VERSION ""

NS_ :

BS_:

BU_: PowertrainControlModule AtmosphericSensor SafetyRestraintSystem2 Aftertreatment_2_GasOutlet Aftertreatment_2_GasIntake DieselParticulateFilterControl Turbocharger SafetyRestraintSystem1 CabDisplay2 Aftertreatment_1_GasOutlet Aftertreatment_1_GasIntake OnBoardDataLogger OffBoardDiagnosticTool2 OffBoardDiagnosticTool1 FileServer ParkingBrakeController SeatController2 FanDriveController SteeringColumnUnit CommunicationUnitRadio CommunicationUnitSatellite CommunicationUnitCellular PropulsionBatteryCharger ChassisController2 ChassisController1 EngineValveControl AuxiliaryHeater2 AuxiliaryHeater1 ClutchUnit RampControl InformationSystem1 SuspensionSystemController2 OilSensor VehicleDynamicStability ExhaustEmissionController TransmissionDisplay2 TransmissionDisplay1 ClimateControl2 WaterPumpController RearAxleSteeringController LightingOperatorControl SeatController1 IgnitionController2 IgnitionController1 TirePressureController CabController2 CabController1 PneumaticSystemController SuspensionSystemController1 HydraulicPumpController EnduranceBrakingSystem RetarderExhaustEngine2 OnBoardDiagnosticUnit HeadwayController RetarderExhaustEngine1 CabDisplay1 ManagementComputer VirtualTerminal OffVehicleGateway PowerTakeOffFront HitchControl AuxiliaryValveControl BodyController TractorTrailerBridge1 StarterSystem ElectricalSystem VehicleSecurity VehicleNavigation AerodynamicControl ElectricalChargingSystem ClimateControl1 TripRecorder InstrumentCluster SuspensionDriveAxle2 SuspensionDriveAxle1 SuspensionSteerAxle SteeringController FuelSystem CruiseControl RetarderDriveline RetarderEngine BrakesDriveAxle2 BrakesDriveAxle1 BrakesSystemController BrakesSteerAxle AxleDrive2 AxleDrive1 AxleSteering PowerTakeOff ShiftConsoleSecondary ShiftConsolePrimary Transmission2 Transmission1 Engine2 Engine1

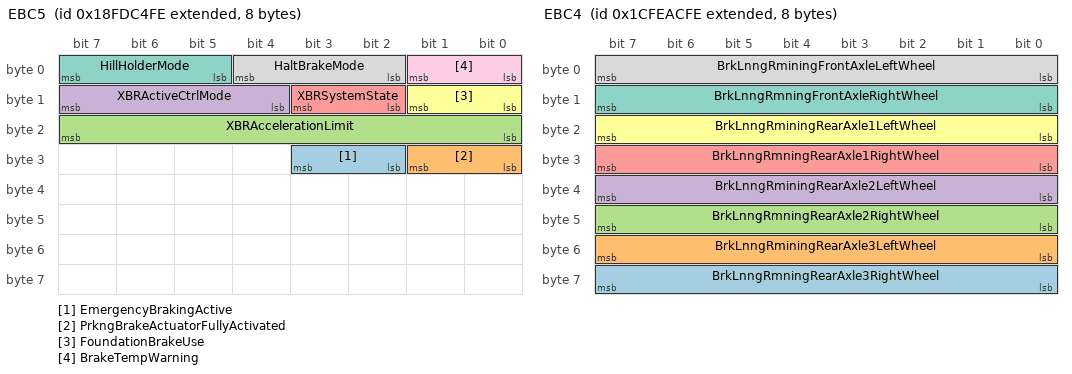
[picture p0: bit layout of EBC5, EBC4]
BO_ 2566767870 EBC5: 8 Vector__XXX
 SG_ EmergencyBrakingActive : 26|2@1+ (1,0) [0|3] "" Vector__XXX
 SG_ PrkngBrakeActuatorFullyActivated : 24|2@1+ (1,0) [0|3] "" Vector__XXX
 SG_ XBRAccelerationLimit : 16|8@1+ (0.1,-12.5) [-10|10] "m/s²" Vector__XXX
 SG_ XBRActiveCtrlMode : 12|4@1+ (1,0) [0|15] "" Vector__XXX
 SG_ XBRSystemState : 10|2@1+ (1,0) [0|3] "" Vector__XXX
 SG_ FoundationBrakeUse : 8|2@1+ (1,0) [0|3] "" Vector__XXX
 SG_ HillHolderMode : 5|3@1+ (1,0) [0|7] "" Vector__XXX
 SG_ HaltBrakeMode : 2|3@1+ (1,0) [0|7] "" Vector__XXX
 SG_ BrakeTempWarning : 0|2@1+ (1,0) [0|3] "" Vector__XXX

BO_ 2633936126 EBC4: 8 Vector__XXX
 SG_ BrkLnngRmningRearAxle3RightWheel : 56|8@1+ (0.4,0) [0|100] "%" Vector__XXX
 SG_ BrkLnngRminingRearAxle3LeftWheel : 48|8@1+ (0.4,0) [0|100] "%" Vector__XXX
 SG_ BrkLnngRmningRearAxle2RightWheel : 40|8@1+ (0.4,0) [0|100] "%" Vector__XXX
 SG_ BrkLnngRminingRearAxle2LeftWheel : 32|8@1+ (0.4,0) [0|100] "%" Vector__XXX
 SG_ BrkLnngRmningRearAxle1RightWheel : 24|8@1+ (0.4,0) [0|100] "%" Vector__XXX
 SG_ BrkLnngRminingRearAxle1LeftWheel : 16|8@1+ (0.4,0) [0|100] "%" Vector__XXX
 SG_ BrkLnngRmningFrontAxleRightWheel : 8|8@1+ (0.4,0) [0|100] "%" Vector__XXX
 SG_ BrkLnngRminingFrontAxleLeftWheel : 0|8@1+ (0.4,0) [0|100] "%" Vector__XXX

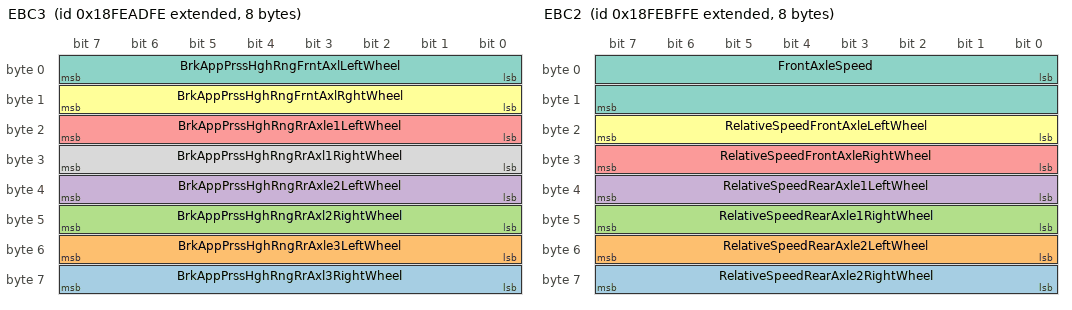
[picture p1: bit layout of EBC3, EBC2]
BO_ 2566827518 EBC3: 8 Vector__XXX
 SG_ BrkAppPrssHghRngRrAxl3RightWheel : 56|8@1+ (5,0) [0|1250] "kPa" Vector__XXX
 SG_ BrkAppPrssHghRngRrAxle3LeftWheel : 48|8@1+ (5,0) [0|1250] "kPa" Vector__XXX
 SG_ BrkAppPrssHghRngRrAxl2RightWheel : 40|8@1+ (5,0) [0|1250] "kPa" Vector__XXX
 SG_ BrkAppPrssHghRngRrAxle2LeftWheel : 32|8@1+ (5,0) [0|1250] "kPa" Vector__XXX
 SG_ BrkAppPrssHghRngRrAxle1LeftWheel : 16|8@1+ (5,0) [0|1250] "kPa" Vector__XXX
 SG_ BrkAppPrssHghRngFrntAxlRghtWheel : 8|8@1+ (5,0) [0|1250] "kPa" Vector__XXX
 SG_ BrkAppPrssHghRngFrntAxlLeftWheel : 0|8@1+ (5,0) [0|1250] "kPa" Vector__XXX
 SG_ BrkAppPrssHghRngRrAxl1RightWheel : 24|8@1+ (5,0) [0|1250] "kPa" Vector__XXX

BO_ 2566832126 EBC2: 8 Vector__XXX
 SG_ RelativeSpeedRearAxle2RightWheel : 56|8@1+ (0.0625,-7.8125) [-7.8125|7.8125] "km/h" Vector__XXX
 SG_ RelativeSpeedRearAxle2LeftWheel : 48|8@1+ (0.0625,-7.8125) [-7.8125|7.8125] "km/h" Vector__XXX
 SG_ RelativeSpeedRearAxle1RightWheel : 40|8@1+ (0.0625,-7.8125) [-7.8125|7.8125] "km/h" Vector__XXX
 SG_ RelativeSpeedRearAxle1LeftWheel : 32|8@1+ (0.0625,-7.8125) [-7.8125|7.8125] "km/h" Vector__XXX
 SG_ RelativeSpeedFrontAxleRightWheel : 24|8@1+ (0.0625,-7.8125) [-7.8125|7.8125] "km/h" Vector__XXX
 SG_ RelativeSpeedFrontAxleLeftWheel : 16|8@1+ (0.0625,-7.8125) [-7.8125|7.8125] "km/h" Vector__XXX
 SG_ FrontAxleSpeed : 0|16@1+ (0.00390625,0) [0|250.996] "km/h" Vector__XXX

BO_ 2565865982 EBC1: 8 Vector__XXX
 SG_ TrctrMntdTrailerABSWarningSignal : 62|2@1+ (1,0) [0|3] "" Vector__XXX
 SG_ TrailerABSStatus : 60|2@1+ (1,0) [0|3] "" Vector__XXX
 SG_ HaltBrakeSwitch : 58|2@1+ (1,0) [0|3] "" Vector__XXX
 SG_ SrcAddrssOfCntrllngDvcFrBrkeCtrl : 48|8@1+ (1,0) [0|253] "" Vector__XXX
 SG_ ATC_ASRInformationSignal : 46|2@1+ (1,0) [0|3] "" Vector__XXX
 SG_ ABS_EBSAmberWarningSignal : 44|2@1+ (1,0) [0|3] "" Vector__XXX
 SG_ EBSRedWarningSignal : 42|2@1+ (1,0) [0|3] "" Vector__XXX
 SG_ ABSFullyOperational : 40|2@1+ (1,0) [0|3] "" Vector__XXX
 SG_ EngRetarderSelection : 32|8@1+ (0.4,0) [0|100] "%" Vector__XXX
 SG_ RemoteAccelEnableSwitch : 30|2@1+ (1,0) [0|3] "" Vector__XXX
 SG_ EngAuxShutdownSwitch : 28|2@1+ (1,0) [0|3] "" Vector__XXX
 SG_ EngDerateSwitch : 26|2@1+ (1,0) [0|3] "" Vector__XXX
 SG_ AccelInterlockSwitch : 24|2@1+ (1,0) [0|3] "" Vector__XXX
 SG_ TractionCtrlOverrideSwitch : 22|2@1+ (1,0) [0|3] "" Vector__XXX
 SG_ ASRHillHolderSwitch : 20|2@1+ (1,0) [0|3] "" Vector__XXX
 SG_ ASROffroadSwitch : 18|2@1+ (1,0) [0|3] "" Vector__XXX
 SG_ ABSOffroadSwitch : 16|2@1+ (1,0) [0|3] "" Vector__XXX
 SG_ BrakePedalPos : 8|8@1+ (0.4,0) [0|100] "%" Vector__XXX
 SG_ EBSBrakeSwitch : 6|2@1+ (1,0) [0|3] "" Vector__XXX
 SG_ AntiLockBrakingActive : 4|2@1+ (1,0) [0|3] "" Vector__XXX
 SG_ ASRBrakeCtrlActive : 2|2@1+ (1,0) [0|3] "" Vector__XXX
 SG_ ASREngCtrlActive : 0|2@1+ (1,0) [0|3] "" Vector__XXX

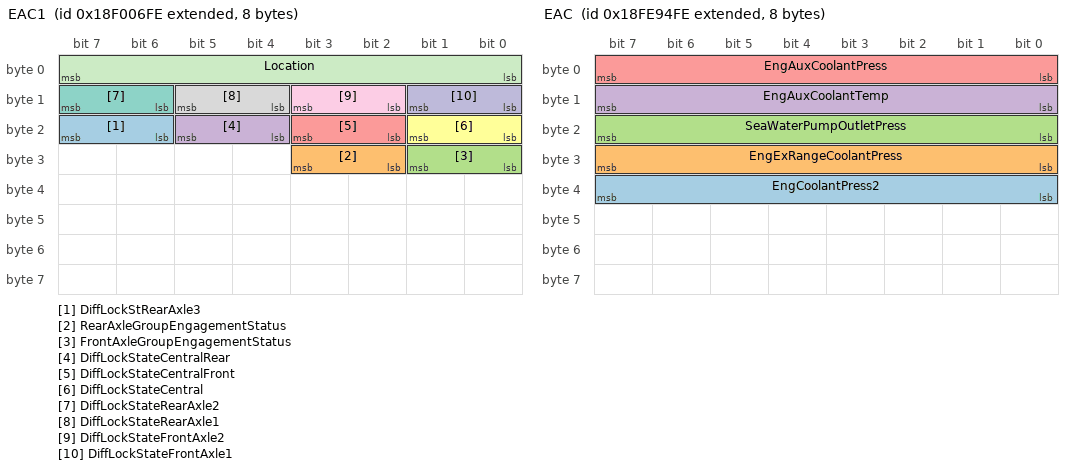
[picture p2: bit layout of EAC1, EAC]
BO_ 2565867262 EAC1: 8 Vector__XXX
 SG_ DiffLockStRearAxle3 : 22|2@1+ (1,0) [0|3] "" Vector__XXX
 SG_ RearAxleGroupEngagementStatus : 26|2@1+ (1,0) [0|3] "" Vector__XXX
 SG_ FrontAxleGroupEngagementStatus : 24|2@1+ (1,0) [0|3] "" Vector__XXX
 SG_ DiffLockStateCentralRear : 20|2@1+ (1,0) [0|3] "" Vector__XXX
 SG_ DiffLockStateCentralFront : 18|2@1+ (1,0) [0|3] "" Vector__XXX
 SG_ DiffLockStateCentral : 16|2@1+ (1,0) [0|3] "" Vector__XXX
 SG_ DiffLockStateRearAxle2 : 14|2@1+ (1,0) [0|3] "" Vector__XXX
 SG_ DiffLockStateRearAxle1 : 12|2@1+ (1,0) [0|3] "" Vector__XXX
 SG_ DiffLockStateFrontAxle2 : 10|2@1+ (1,0) [0|3] "" Vector__XXX
 SG_ DiffLockStateFrontAxle1 : 8|2@1+ (1,0) [0|3] "" Vector__XXX
 SG_ Location : 0|8@1+ (1,0) [0|255] "" Vector__XXX

BO_ 2566821118 EAC: 8 Vector__XXX
 SG_ EngCoolantPress2 : 32|8@1+ (4,0) [0|1000] "kPa" Vector__XXX
 SG_ EngExRangeCoolantPress : 24|8@1+ (4,0) [0|1000] "kPa" Vector__XXX
 SG_ SeaWaterPumpOutletPress : 16|8@1+ (2,0) [0|500] "kPa" Vector__XXX
 SG_ EngAuxCoolantTemp : 8|8@1+ (1,-40) [-40|210] "°C" Vector__XXX
 SG_ EngAuxCoolantPress : 0|8@1+ (4,0) [0|1000] "kPa" Vector__XXX

BO_ 2566810622 DI: 8 Vector__XXX
 SG_ Driver2Identification : 8|8@1+ (1,0) [0|255] "" Vector__XXX
 SG_ Driver1Identification : 0|8@1+ (1,0) [0|255] "" Vector__XXX

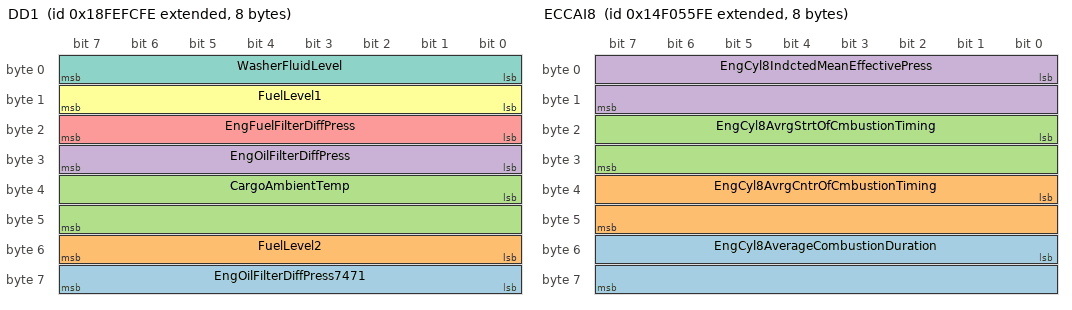
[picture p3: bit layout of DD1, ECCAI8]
BO_ 2566847742 DD1: 8 Vector__XXX
 SG_ EngOilFilterDiffPress7471 : 56|8@1+ (5,0) [0|1250] "kPa" Vector__XXX
 SG_ FuelLevel2 : 48|8@1+ (0.4,0) [0|100] "%" Vector__XXX
 SG_ CargoAmbientTemp : 32|16@1+ (0.03125,-273) [-273|1734.96875] "°C" Vector__XXX
 SG_ EngOilFilterDiffPress : 24|8@1+ (0.5,0) [0|125] "kPa" Vector__XXX
 SG_ EngFuelFilterDiffPress : 16|8@1+ (2,0) [0|500] "kPa" Vector__XXX
 SG_ FuelLevel1 : 8|8@1+ (0.4,0) [0|100] "%" Vector__XXX
 SG_ WasherFluidLevel : 0|8@1+ (0.4,0) [0|100] "%" Vector__XXX

BO_ 2498778622 ECCAI8: 8 Vector__XXX
 SG_ EngCyl8AverageCombustionDuration : 48|16@1+ (0.0078125,0) [0|501.99] "deg" Vector__XXX
 SG_ EngCyl8AvrgCntrOfCmbustionTiming : 32|16@1+ (0.0078125,-250) [-250|250.992] "deg" Vector__XXX
 SG_ EngCyl8AvrgStrtOfCmbustionTiming : 16|16@1+ (0.0078125,-250) [-250|250.992] "deg" Vector__XXX
 SG_ EngCyl8IndctedMeanEffectivePress : 0|16@1+ (0.0001220703125,-1) [-1|6.84362793] "MPa" Vector__XXX

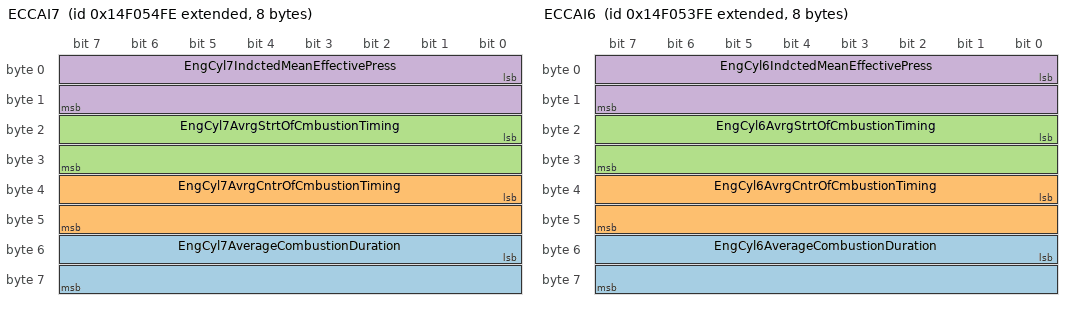
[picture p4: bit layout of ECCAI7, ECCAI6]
BO_ 2498778366 ECCAI7: 8 Vector__XXX
 SG_ EngCyl7AverageCombustionDuration : 48|16@1+ (0.0078125,0) [0|501.99] "deg" Vector__XXX
 SG_ EngCyl7AvrgCntrOfCmbustionTiming : 32|16@1+ (0.0078125,-250) [-250|250.992] "deg" Vector__XXX
 SG_ EngCyl7AvrgStrtOfCmbustionTiming : 16|16@1+ (0.0078125,-250) [-250|250.992] "deg" Vector__XXX
 SG_ EngCyl7IndctedMeanEffectivePress : 0|16@1+ (0.0001220703125,-1) [-1|6.84362793] "MPa" Vector__XXX

BO_ 2498778110 ECCAI6: 8 Vector__XXX
 SG_ EngCyl6AverageCombustionDuration : 48|16@1+ (0.0078125,0) [0|501.99] "deg" Vector__XXX
 SG_ EngCyl6AvrgCntrOfCmbustionTiming : 32|16@1+ (0.0078125,-250) [-250|250.992] "deg" Vector__XXX
 SG_ EngCyl6AvrgStrtOfCmbustionTiming : 16|16@1+ (0.0078125,-250) [-250|250.992] "deg" Vector__XXX
 SG_ EngCyl6IndctedMeanEffectivePress : 0|16@1+ (0.0001220703125,-1) [-1|6.84362793] "MPa" Vector__XXX

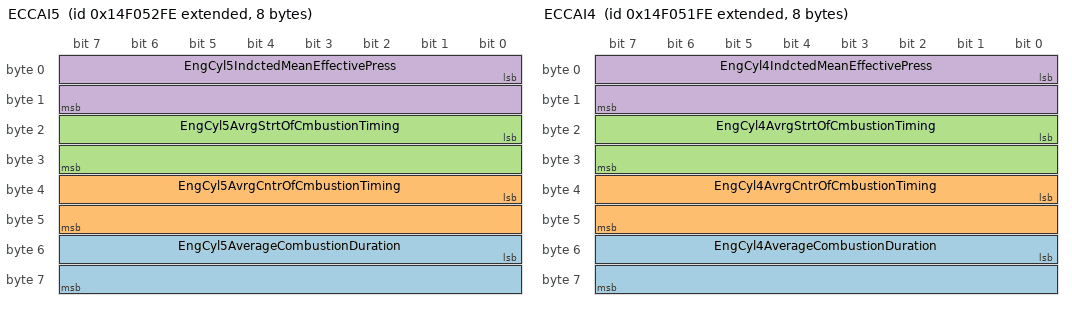
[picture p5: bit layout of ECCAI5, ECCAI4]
BO_ 2498777854 ECCAI5: 8 Vector__XXX
 SG_ EngCyl5AverageCombustionDuration : 48|16@1+ (0.0078125,0) [0|501.99] "deg" Vector__XXX
 SG_ EngCyl5AvrgCntrOfCmbustionTiming : 32|16@1+ (0.0078125,-250) [-250|250.992] "deg" Vector__XXX
 SG_ EngCyl5AvrgStrtOfCmbustionTiming : 16|16@1+ (0.0078125,-250) [-250|250.992] "deg" Vector__XXX
 SG_ EngCyl5IndctedMeanEffectivePress : 0|16@1+ (0.0001220703125,-1) [-1|6.84362793] "MPa" Vector__XXX

BO_ 2498777598 ECCAI4: 8 Vector__XXX
 SG_ EngCyl4AverageCombustionDuration : 48|16@1+ (0.0078125,0) [0|501.99] "deg" Vector__XXX
 SG_ EngCyl4AvrgCntrOfCmbustionTiming : 32|16@1+ (0.0078125,-250) [-250|250.992] "deg" Vector__XXX
 SG_ EngCyl4AvrgStrtOfCmbustionTiming : 16|16@1+ (0.0078125,-250) [-250|250.992] "deg" Vector__XXX
 SG_ EngCyl4IndctedMeanEffectivePress : 0|16@1+ (0.0001220703125,-1) [-1|6.84362793] "MPa" Vector__XXX

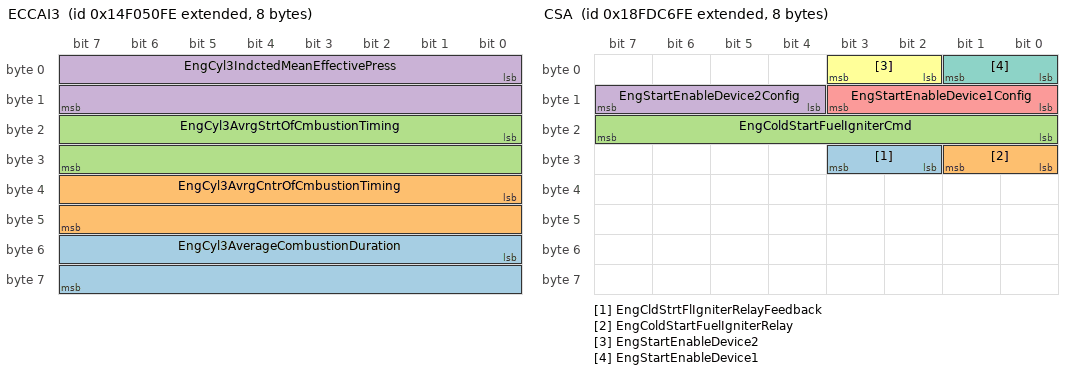
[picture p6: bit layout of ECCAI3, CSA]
BO_ 2498777342 ECCAI3: 8 Vector__XXX
 SG_ EngCyl3AverageCombustionDuration : 48|16@1+ (0.0078125,0) [0|501.99] "deg" Vector__XXX
 SG_ EngCyl3AvrgCntrOfCmbustionTiming : 32|16@1+ (0.0078125,-250) [-250|250.992] "deg" Vector__XXX
 SG_ EngCyl3AvrgStrtOfCmbustionTiming : 16|16@1+ (0.0078125,-250) [-250|250.992] "deg" Vector__XXX
 SG_ EngCyl3IndctedMeanEffectivePress : 0|16@1+ (0.0001220703125,-1) [-1|6.84362793] "MPa" Vector__XXX

BO_ 2566768382 CSA: 8 Vector__XXX
 SG_ EngCldStrtFlIgniterRelayFeedback : 26|2@1+ (1,0) [0|3] "" Vector__XXX
 SG_ EngColdStartFuelIgniterRelay : 24|2@1+ (1,0) [0|3] "" Vector__XXX
 SG_ EngColdStartFuelIgniterCmd : 16|8@1+ (0.4,0) [0|100] "%" Vector__XXX
 SG_ EngStartEnableDevice2Config : 12|4@1+ (1,0) [0|15] "" Vector__XXX
 SG_ EngStartEnableDevice1Config : 8|4@1+ (1,0) [0|15] "" Vector__XXX
 SG_ EngStartEnableDevice2 : 2|2@1+ (1,0) [0|3] "" Vector__XXX
 SG_ EngStartEnableDevice1 : 0|2@1+ (1,0) [0|3] "" Vector__XXX

BO_ 2566811902 CVW: 8 Vector__XXX
 SG_ PoweredVehicleWeight : 0|16@1+ (10,0) [0|642550] "kg" Vector__XXX
 SG_ GrossCombinationVehicleWeight : 16|16@1+ (10,0) [0|642550] "kg" Vector__XXX

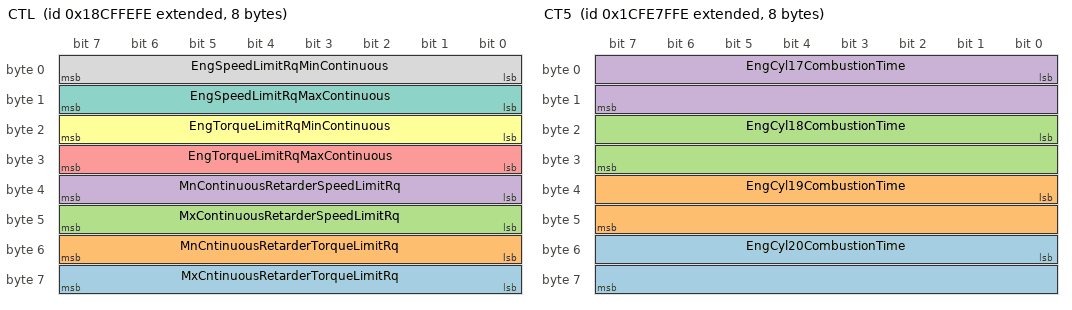
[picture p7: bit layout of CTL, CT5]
BO_ 2563768062 CTL: 8 Vector__XXX
 SG_ MxCntinuousRetarderTorqueLimitRq : 56|8@1+ (1,-125) [-125|0] "%" Vector__XXX
 SG_ MnCntinuousRetarderTorqueLimitRq : 48|8@1+ (1,-125) [-125|0] "%" Vector__XXX
 SG_ MxContinuousRetarderSpeedLimitRq : 40|8@1+ (32,0) [0|8000] "rpm" Vector__XXX
 SG_ MnContinuousRetarderSpeedLimitRq : 32|8@1+ (32,0) [0|8000] "rpm" Vector__XXX
 SG_ EngTorqueLimitRqMaxContinuous : 24|8@1+ (1,-125) [0|125] "%" Vector__XXX
 SG_ EngTorqueLimitRqMinContinuous : 16|8@1+ (1,-125) [0|125] "%" Vector__XXX
 SG_ EngSpeedLimitRqMaxContinuous : 8|8@1+ (32,0) [0|8000] "rpm" Vector__XXX
 SG_ EngSpeedLimitRqMinContinuous : 0|8@1+ (32,0) [0|8000] "rpm" Vector__XXX

BO_ 2633924862 CT6: 8 Vector__XXX
 SG_ EngAverageCombustionTime : 16|16@1+ (0.01,0) [0|642.55] "ms" Vector__XXX
 SG_ EngDesiredCombustionTime : 0|16@1+ (0.01,0) [0|642.55] "ms" Vector__XXX

BO_ 2633924606 CT5: 8 Vector__XXX
 SG_ EngCyl20CombustionTime : 48|16@1+ (0.01,0) [0|642.55] "ms" Vector__XXX
 SG_ EngCyl19CombustionTime : 32|16@1+ (0.01,0) [0|642.55] "ms" Vector__XXX
 SG_ EngCyl18CombustionTime : 16|16@1+ (0.01,0) [0|642.55] "ms" Vector__XXX
 SG_ EngCyl17CombustionTime : 0|16@1+ (0.01,0) [0|642.55] "ms" Vector__XXX

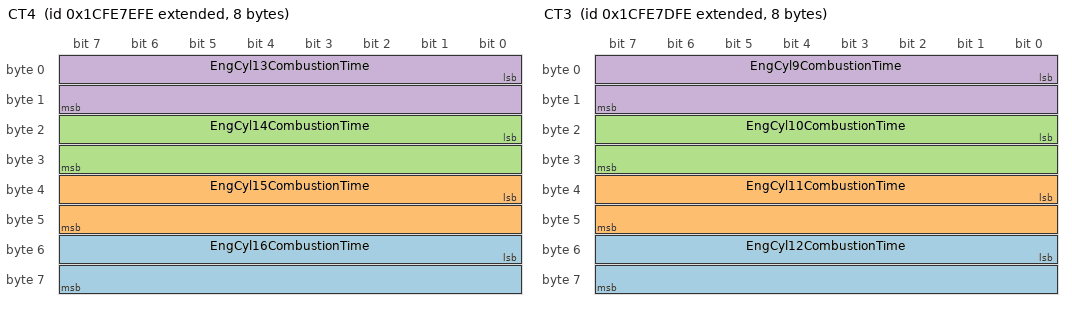
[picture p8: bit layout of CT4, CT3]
BO_ 2633924350 CT4: 8 Vector__XXX
 SG_ EngCyl16CombustionTime : 48|16@1+ (0.01,0) [0|642.55] "ms" Vector__XXX
 SG_ EngCyl15CombustionTime : 32|16@1+ (0.01,0) [0|642.55] "ms" Vector__XXX
 SG_ EngCyl14CombustionTime : 16|16@1+ (0.01,0) [0|642.55] "ms" Vector__XXX
 SG_ EngCyl13CombustionTime : 0|16@1+ (0.01,0) [0|642.55] "ms" Vector__XXX

BO_ 2633924094 CT3: 8 Vector__XXX
 SG_ EngCyl12CombustionTime : 48|16@1+ (0.01,0) [0|642.55] "ms" Vector__XXX
 SG_ EngCyl11CombustionTime : 32|16@1+ (0.01,0) [0|642.55] "ms" Vector__XXX
 SG_ EngCyl10CombustionTime : 16|16@1+ (0.01,0) [0|642.55] "ms" Vector__XXX
 SG_ EngCyl9CombustionTime : 0|16@1+ (0.01,0) [0|642.55] "ms" Vector__XXX

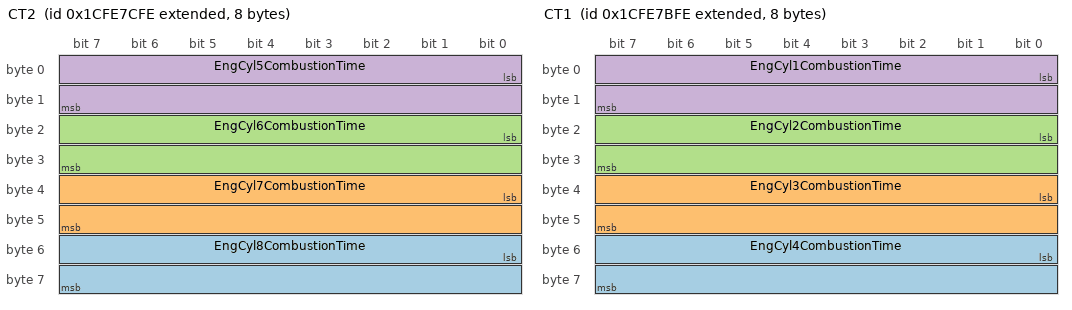
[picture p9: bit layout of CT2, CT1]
BO_ 2633923838 CT2: 8 Vector__XXX
 SG_ EngCyl8CombustionTime : 48|16@1+ (0.01,0) [0|642.55] "ms" Vector__XXX
 SG_ EngCyl7CombustionTime : 32|16@1+ (0.01,0) [0|642.55] "ms" Vector__XXX
 SG_ EngCyl6CombustionTime : 16|16@1+ (0.01,0) [0|642.55] "ms" Vector__XXX
 SG_ EngCyl5CombustionTime : 0|16@1+ (0.01,0) [0|642.55] "ms" Vector__XXX

BO_ 2633923582 CT1: 8 Vector__XXX
 SG_ EngCyl4CombustionTime : 48|16@1+ (0.01,0) [0|642.55] "ms" Vector__XXX
 SG_ EngCyl3CombustionTime : 32|16@1+ (0.01,0) [0|642.55] "ms" Vector__XXX
 SG_ EngCyl2CombustionTime : 16|16@1+ (0.01,0) [0|642.55] "ms" Vector__XXX
 SG_ EngCyl1CombustionTime : 0|16@1+ (0.01,0) [0|642.55] "ms" Vector__XXX

BO_ 2633878014 CMI: 8 Vector__XXX
 SG_ TotalCountOfConfigChangesMade : 0|16@1+ (1,0) [0|64255] "" Vector__XXX

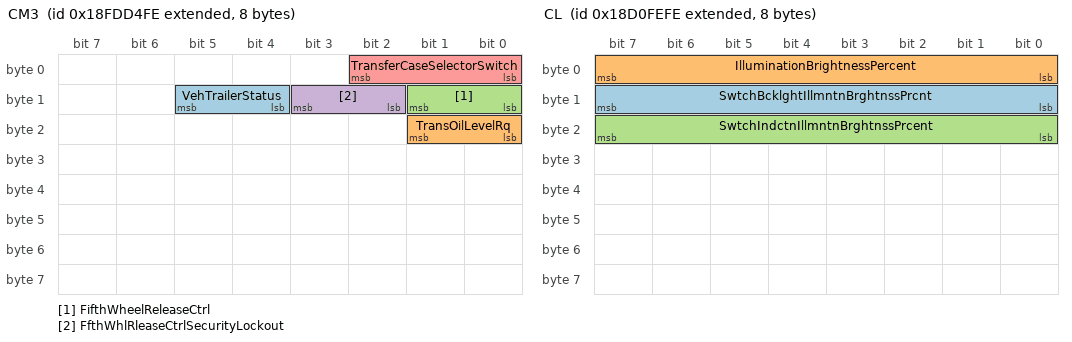
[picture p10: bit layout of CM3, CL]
BO_ 2566771966 CM3: 8 Vector__XXX
 SG_ VehTrailerStatus : 12|2@1+ (1,0) [0|3] "" Vector__XXX
 SG_ TransOilLevelRq : 16|2@1+ (1,0) [0|3] "" Vector__XXX
 SG_ FifthWheelReleaseCtrl : 8|2@1+ (1,0) [0|3] "" Vector__XXX
 SG_ FfthWhlRleaseCtrlSecurityLockout : 10|2@1+ (1,0) [0|3] "" Vector__XXX
 SG_ TransferCaseSelectorSwitch : 0|3@1+ (1,0) [0|7] "" Vector__XXX

BO_ 2564882174 CM1: 8 Vector__XXX
 SG_ SelectedMaxVehicleSpeedLimit : 56|8@1+ (1,0) [0|250] "" Vector__XXX
 SG_ RqCabZoneHeating : 54|2@1+ (1,0) [0|3] "" Vector__XXX
 SG_ RqEngZoneHeating : 52|2@1+ (1,0) [0|3] "" Vector__XXX
 SG_ AuxHeaterModeRq : 48|4@1+ (1,0) [0|15] "" Vector__XXX
 SG_ EngAutomaticStartEnableSwitch : 46|2@1+ (1,0) [0|3] "" Vector__XXX
 SG_ AtomaticGearShiftingEnableSwitch : 44|2@1+ (1,0) [0|3] "" Vector__XXX
 SG_ AFTRegenForceSw : 42|2@1+ (1,0) [0|3] "" Vector__XXX
 SG_ AFTRegenInhSw : 40|2@1+ (1,0) [0|3] "" Vector__XXX
 SG_ VhclLmtngSpdGovernorEnableSwitch : 38|2@1+ (1,0) [0|3] "" Vector__XXX
 SG_ VhclLmtngSpdGvrnrIncrementSwitch : 36|2@1+ (1,0) [0|3] "" Vector__XXX
 SG_ VhclLmtngSpdGvrnrDecrementSwitch : 34|2@1+ (1,0) [0|3] "" Vector__XXX
 SG_ ParkBrakeCmd : 32|2@1+ (1,0) [0|3] "" Vector__XXX
 SG_ SeatBeltSwitch : 30|2@1+ (1,0) [0|3] "" Vector__XXX
 SG_ OperatorSeatDirectionSwitch : 28|2@1+ (1,0) [0|3] "" Vector__XXX
 SG_ BatteryMainSwitchHoldRq : 26|2@1+ (1,0) [0|3] "" Vector__XXX
 SG_ AuxHeaterCoolantPumpRq : 24|2@1+ (1,0) [0|3] "" Vector__XXX
 SG_ CabInteriorTempCmd : 8|16@1+ (0.03125,-273) [-273|1734.96875] "°C" Vector__XXX
 SG_ RequestedPercentFanSpeed : 0|8@1+ (0.4,0) [0|100] "%" Vector__XXX

BO_ 2563833598 CL: 8 Vector__XXX
 SG_ SwtchBcklghtIllmntnBrghtnssPrcnt : 8|8@1+ (0.4,0) [0|100] "%" Vector__XXX
 SG_ IlluminationBrightnessPercent : 0|8@1+ (0.4,0) [0|100] "%" Vector__XXX
 SG_ SwtchIndctnIllmntnBrghtnssPrcent : 16|8@1+ (0.4,0) [0|100] "%" Vector__XXX

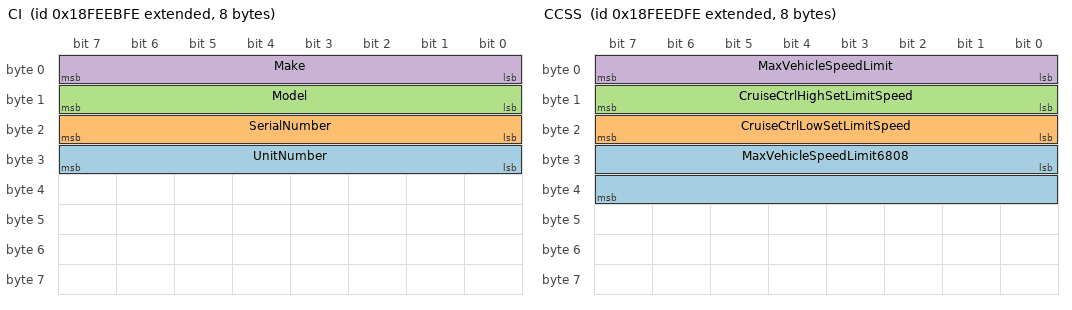
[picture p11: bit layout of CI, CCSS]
BO_ 2566843390 CI: 8 Vector__XXX
 SG_ UnitNumber : 24|8@1+ (1,0) [0|255] "" Vector__XXX
 SG_ SerialNumber : 16|8@1+ (1,0) [0|255] "" Vector__XXX
 SG_ Model : 8|8@1+ (1,0) [0|255] "" Vector__XXX
 SG_ Make : 0|8@1+ (1,0) [0|255] "" Vector__XXX

BO_ 2566844926 CCVS1: 8 Vector__XXX
 SG_ EngShutdownOverrideSwitch : 62|2@1+ (1,0) [0|3] "" Vector__XXX
 SG_ EngTestModeSwitch : 60|2@1+ (1,0) [0|3] "" Vector__XXX
 SG_ EngIdleDecrementSwitch : 58|2@1+ (1,0) [0|3] "" Vector__XXX
 SG_ EngIdleIncrementSwitch : 56|2@1+ (1,0) [0|3] "" Vector__XXX
 SG_ CruiseCtrlStates : 53|3@1+ (1,0) [0|7] "" Vector__XXX
 SG_ PTOGovernorState : 48|5@1+ (1,0) [0|31] "" Vector__XXX
 SG_ CruiseCtrlSetSpeed : 40|8@1+ (1,0) [0|250] "km/h" Vector__XXX
 SG_ CruiseCtrlAccelerateSwitch : 38|2@1+ (1,0) [0|3] "" Vector__XXX
 SG_ CruiseCtrlResumeSwitch : 36|2@1+ (1,0) [0|3] "" Vector__XXX
 SG_ CruiseCtrlCoastSwitch : 34|2@1+ (1,0) [0|3] "" Vector__XXX
 SG_ CruiseCtrlSetSwitch : 32|2@1+ (1,0) [0|3] "" Vector__XXX
 SG_ ClutchSwitch : 30|2@1+ (1,0) [0|3] "" Vector__XXX
 SG_ BrakeSwitch : 28|2@1+ (1,0) [0|3] "" Vector__XXX
 SG_ CruiseCtrlEnableSwitch : 26|2@1+ (1,0) [0|3] "" Vector__XXX
 SG_ CruiseCtrlActive : 24|2@1+ (1,0) [0|3] "" Vector__XXX
 SG_ WheelBasedVehicleSpeed : 8|16@1+ (0.00390625,0) [0|250.996] "km/h" Vector__XXX
 SG_ ParkBrakeReleaseInhibitRq : 6|2@1+ (1,0) [0|3] "" Vector__XXX
 SG_ CruiseCtrlPauseSwitch : 4|2@1+ (1,0) [0|3] "" Vector__XXX
 SG_ ParkingBrakeSwitch : 2|2@1+ (1,0) [0|3] "" Vector__XXX
 SG_ TwoSpeedAxleSwitch : 0|2@1+ (1,0) [0|3] "" Vector__XXX

BO_ 2566843902 CCSS: 8 Vector__XXX
 SG_ MaxVehicleSpeedLimit6808 : 24|16@1+ (0.00390625,0) [0|250.996] "km/h" Vector__XXX
 SG_ CruiseCtrlLowSetLimitSpeed : 16|8@1+ (1,0) [0|250] "km/h" Vector__XXX
 SG_ CruiseCtrlHighSetLimitSpeed : 8|8@1+ (1,0) [0|250] "km/h" Vector__XXX
 SG_ MaxVehicleSpeedLimit : 0|8@1+ (1,0) [0|250] "km/h" Vector__XXX

BO_ 2566809598 CCC: 8 Vector__XXX
 SG_ AuxHeaterMaxOutputPower : 0|16@1+ (2,0) [0|128510] "W" Vector__XXX

BO_ 2633940222 CBI: 16 Vector__XXX
 SG_ TripServiceBrakeApplications : 96|32@1+ (1,0) [0|4211081215] "appl" Vector__XXX
 SG_ TripServiceBrakeDistance : 64|32@1+ (0.125,0) [0|526385151.875] "km" Vector__XXX
 SG_ TripCompressionBrakeDistance : 32|32@1+ (0.125,0) [0|526385151.875] "km" Vector__XXX
 SG_ TotalCompressionBrakeDistance : 0|32@1+ (0.125,0) [0|526385151.875] "km" Vector__XXX

BO_ 2566775294 CACI: 8 Vector__XXX
 SG_ CbA_CRfrgrntCmpressorOutletPress : 0|8@1+ (16,0) [0|4000] "kPa" Vector__XXX

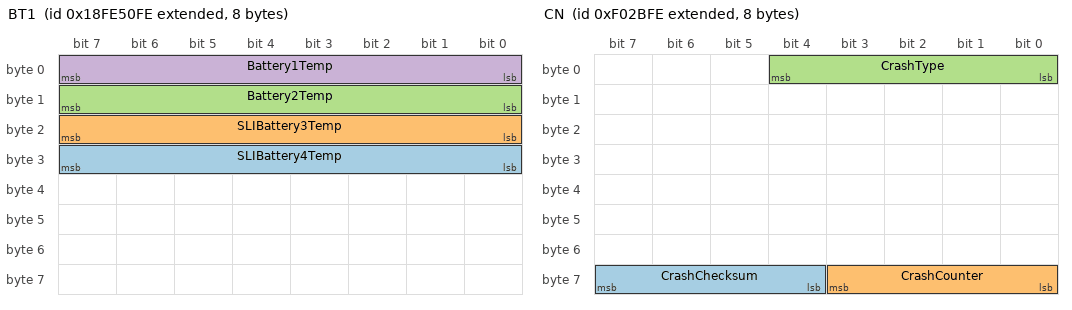
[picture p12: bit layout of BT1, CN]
BO_ 2566803710 BT1: 8 Vector__XXX
 SG_ SLIBattery4Temp : 24|8@1+ (1,-40) [-40|210] "°C" Vector__XXX
 SG_ SLIBattery3Temp : 16|8@1+ (1,-40) [-40|210] "°C" Vector__XXX
 SG_ Battery2Temp : 8|8@1+ (1,-40) [-40|210] "°C" Vector__XXX
 SG_ Battery1Temp : 0|8@1+ (1,-40) [-40|210] "°C" Vector__XXX

BO_ 2566719486 DLCC1: 8 Vector__XXX
 SG_ VhclAccelerationRateLimitLampCmd : 34|2@1+ (1,0) [0|3] "" Vector__XXX
 SG_ EngSpeedVeryHighLampCmd : 32|2@1+ (1,0) [0|3] "" Vector__XXX
 SG_ EngSpeedHighLampCmd : 30|2@1+ (1,0) [0|3] "" Vector__XXX
 SG_ EngCtrlModule3ReadyForUseLampCmd : 28|2@1+ (1,0) [0|3] "" Vector__XXX
 SG_ EngCtrlModule2ReadyForUseLampCmd : 26|2@1+ (1,0) [0|3] "" Vector__XXX
 SG_ EngCtrlModule1ReadyForUseLampCmd : 24|2@1+ (1,0) [0|3] "" Vector__XXX
 SG_ EngFuelFilterRestrictedLampCmd : 22|2@1+ (1,0) [0|3] "" Vector__XXX
 SG_ EngAirFilterRestrictionLampCmd : 20|2@1+ (1,0) [0|3] "" Vector__XXX
 SG_ EngIdleManagementActiveLampCmd : 18|2@1+ (1,0) [0|3] "" Vector__XXX
 SG_ EngCoolantLevelLowLampCmd : 16|2@1+ (1,0) [0|3] "" Vector__XXX
 SG_ EngCoolantTempHighLampCmd : 14|2@1+ (1,0) [0|3] "" Vector__XXX
 SG_ EngOilPressLowLampCmd : 12|2@1+ (1,0) [0|3] "" Vector__XXX
 SG_ CmprssnBrkEnblSwtchIndctrLampCmd : 10|2@1+ (1,0) [0|3] "" Vector__XXX
 SG_ EngBrakeActiveLampCmd : 8|2@1+ (1,0) [0|3] "" Vector__XXX
 SG_ OBDMalfunctionIndicatorLampCmd : 6|2@1+ (1,0) [0|3] "" Vector__XXX
 SG_ EngRedStopLampCmd : 4|2@1+ (1,0) [0|3] "" Vector__XXX
 SG_ EngAmberWarningLampCmd : 2|2@1+ (1,0) [0|3] "" Vector__XXX
 SG_ EngProtectLampCmd : 0|2@1+ (1,0) [0|3] "" Vector__XXX

BO_ 2163223550 CN: 8 Vector__XXX
 SG_ CrashChecksum : 60|4@1+ (1,0) [0|15] "" Vector__XXX
 SG_ CrashCounter : 56|4@1+ (1,0) [0|15] "" Vector__XXX
 SG_ CrashType : 0|5@1+ (1,0) [0|0] "" Vector__XXX

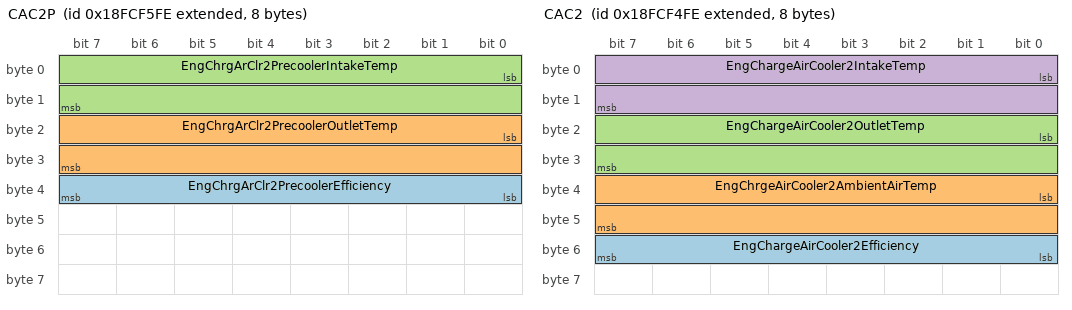
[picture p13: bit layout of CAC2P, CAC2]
BO_ 2566714878 CAC2P: 8 Vector__XXX
 SG_ EngChrgArClr2PrecoolerEfficiency : 32|8@1+ (0.4,0) [0|100] "%" Vector__XXX
 SG_ EngChrgArClr2PrecoolerOutletTemp : 16|16@1+ (0.03125,-273) [-273|1734.96875] "°C" Vector__XXX
 SG_ EngChrgArClr2PrecoolerIntakeTemp : 0|16@1+ (0.03125,-273) [-273|1734.96875] "°C" Vector__XXX

BO_ 2566714622 CAC2: 8 Vector__XXX
 SG_ EngChargeAirCooler2Efficiency : 48|8@1+ (0.4,0) [0|100] "%" Vector__XXX
 SG_ EngChrgeAirCooler2AmbientAirTemp : 32|16@1+ (0.03125,-273) [-273|1734.96875] "°C" Vector__XXX
 SG_ EngChargeAirCooler2OutletTemp : 16|16@1+ (0.03125,-273) [-273|1734.96875] "°C" Vector__XXX
 SG_ EngChargeAirCooler2IntakeTemp : 0|16@1+ (0.03125,-273) [-273|1734.96875] "°C" Vector__XXX

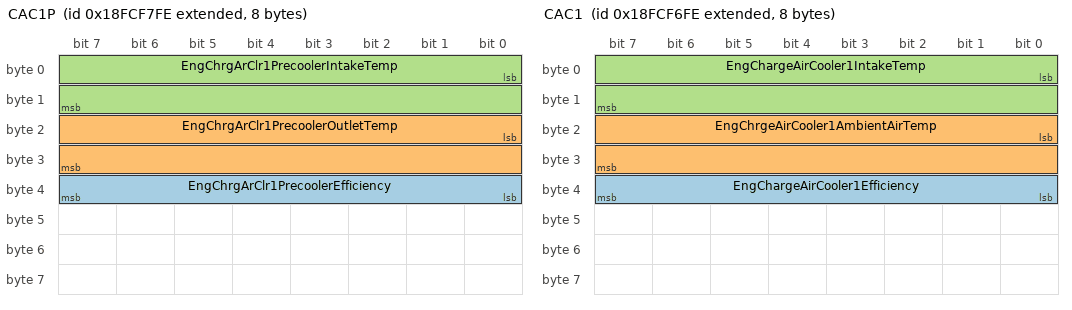
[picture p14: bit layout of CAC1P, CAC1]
BO_ 2566715390 CAC1P: 8 Vector__XXX
 SG_ EngChrgArClr1PrecoolerEfficiency : 32|8@1+ (0.4,0) [0|100] "%" Vector__XXX
 SG_ EngChrgArClr1PrecoolerOutletTemp : 16|16@1+ (0.03125,-273) [-273|1734.96875] "°C" Vector__XXX
 SG_ EngChrgArClr1PrecoolerIntakeTemp : 0|16@1+ (0.03125,-273) [-273|1734.96875] "°C" Vector__XXX

BO_ 2566715134 CAC1: 8 Vector__XXX
 SG_ EngChargeAirCooler1Efficiency : 32|8@1+ (0.4,0) [0|100] "%" Vector__XXX
 SG_ EngChrgeAirCooler1AmbientAirTemp : 16|16@1+ (0.03125,-273) [-273|1734.96875] "°C" Vector__XXX
 SG_ EngChargeAirCooler1IntakeTemp : 0|16@1+ (0.03125,-273) [-273|1734.96875] "°C" Vector__XXX

BO_ 2365400830 BJM9: 8 Vector__XXX
 SG_ Joystick9Button9PressedStatus : 62|2@1+ (1,0) [0|3] "" Vector__XXX
 SG_ Joystick9Button10PressedStatus : 60|2@1+ (1,0) [0|3] "" Vector__XXX
 SG_ Joystick9Button11PressedStatus : 58|2@1+ (1,0) [0|3] "" Vector__XXX
 SG_ Joystick9Button12PressedStatus : 56|2@1+ (1,0) [0|3] "" Vector__XXX
 SG_ Joystick9Button5PressedStatus : 54|2@1+ (1,0) [0|3] "" Vector__XXX
 SG_ Joystick9Button6PressedStatus : 52|2@1+ (1,0) [0|3] "" Vector__XXX
 SG_ Joystick9Button7PressedStatus : 50|2@1+ (1,0) [0|3] "" Vector__XXX
 SG_ Joystick9Button8PressedStatus : 48|2@1+ (1,0) [0|3] "" Vector__XXX
 SG_ Joystick9Button1PressedStatus : 46|2@1+ (1,0) [0|3] "" Vector__XXX
 SG_ Joystick9Button2PressedStatus : 44|2@1+ (1,0) [0|3] "" Vector__XXX
 SG_ Joystick9Button3PressedStatus : 42|2@1+ (1,0) [0|3] "" Vector__XXX
 SG_ Joystick9Button4PressedStatus : 40|2@1+ (1,0) [0|3] "" Vector__XXX
 SG_ Joystick9XAxisDetentPosStatus : 38|2@1+ (1,0) [0|3] "" Vector__XXX
 SG_ Joystick9YAxisDetentPosStatus : 36|2@1+ (1,0) [0|3] "" Vector__XXX
 SG_ Joystick9YAxisPos : 22|10@1+ (0.1,0) [0|102] "%" Vector__XXX
 SG_ Jystck9YAxsLvrFrwrdPstvPosStatus : 20|2@1+ (1,0) [0|3] "" Vector__XXX
 SG_ Jystck9YAxsLvrBckNgtivePosStatus : 18|2@1+ (1,0) [0|3] "" Vector__XXX
 SG_ Joystick9YAxisNeutralPosStatus : 16|2@1+ (1,0) [0|3] "" Vector__XXX
 SG_ Joystick9XAxisPos : 6|10@1+ (0.1,0) [0|102] "%" Vector__XXX
 SG_ Jystck9XAxsLvrRghtPstvePosStatus : 4|2@1+ (1,0) [0|3] "" Vector__XXX
 SG_ Jystck9XAxsLvrLftNgtivePosStatus : 2|2@1+ (1,0) [0|3] "" Vector__XXX
 SG_ Joystick9XAxisNeutralPosStatus : 0|2@1+ (1,0) [0|3] "" Vector__XXX

BO_ 2365401342 BJM8: 8 Vector__XXX
 SG_ Joystick8Button9PressedStatus : 62|2@1+ (1,0) [0|3] "" Vector__XXX
 SG_ Joystick8Button10PressedStatus : 60|2@1+ (1,0) [0|3] "" Vector__XXX
 SG_ Joystick8Button11PressedStatus : 58|2@1+ (1,0) [0|3] "" Vector__XXX
 SG_ Joystick8Button12PressedStatus : 56|2@1+ (1,0) [0|3] "" Vector__XXX
 SG_ Joystick8Button5PressedStatus : 54|2@1+ (1,0) [0|3] "" Vector__XXX
 SG_ Joystick8Button6PressedStatus : 52|2@1+ (1,0) [0|3] "" Vector__XXX
 SG_ Joystick8Button7PressedStatus : 50|2@1+ (1,0) [0|3] "" Vector__XXX
 SG_ Joystick8Button8PressedStatus : 48|2@1+ (1,0) [0|3] "" Vector__XXX
 SG_ Joystick8Button1PressedStatus : 46|2@1+ (1,0) [0|3] "" Vector__XXX
 SG_ Joystick8Button2PressedStatus : 44|2@1+ (1,0) [0|3] "" Vector__XXX
 SG_ Joystick8Button3PressedStatus : 42|2@1+ (1,0) [0|3] "" Vector__XXX
 SG_ Joystick8Button4PressedStatus : 40|2@1+ (1,0) [0|3] "" Vector__XXX
 SG_ Joystick8XAxisDetentPosStatus : 38|2@1+ (1,0) [0|3] "" Vector__XXX
 SG_ Joystick8YAxisDetentPosStatus : 36|2@1+ (1,0) [0|3] "" Vector__XXX
 SG_ Joystick8YAxisPos : 22|10@1+ (0.1,0) [0|102] "%" Vector__XXX
 SG_ Jystck8YAxsLvrFrwrdPstvPosStatus : 20|2@1+ (1,0) [0|3] "" Vector__XXX
 SG_ Jystck8YAxsLvrBckNgtivePosStatus : 18|2@1+ (1,0) [0|3] "" Vector__XXX
 SG_ Joystick8YAxisNeutralPosStatus : 16|2@1+ (1,0) [0|3] "" Vector__XXX
 SG_ Joystick8XAxisPos : 6|10@1+ (0.1,0) [0|102] "%" Vector__XXX
 SG_ Jystck8XAxsLvrRghtPstvePosStatus : 4|2@1+ (1,0) [0|3] "" Vector__XXX
 SG_ Jystck8XAxsLvrLftNgtivePosStatus : 2|2@1+ (1,0) [0|3] "" Vector__XXX
 SG_ Joystick8XAxisNeutralPosStatus : 0|2@1+ (1,0) [0|3] "" Vector__XXX

BO_ 2365401854 BJM7: 8 Vector__XXX
 SG_ Joystick7Button9PressedStatus : 62|2@1+ (1,0) [0|3] "" Vector__XXX
 SG_ Joystick7Button10PressedStatus : 60|2@1+ (1,0) [0|3] "" Vector__XXX
 SG_ Joystick7Button11PressedStatus : 58|2@1+ (1,0) [0|3] "" Vector__XXX
 SG_ Joystick7Button12PressedStatus : 56|2@1+ (1,0) [0|3] "" Vector__XXX
 SG_ Joystick7Button5PressedStatus : 54|2@1+ (1,0) [0|3] "" Vector__XXX
 SG_ Joystick7Button6PressedStatus : 52|2@1+ (1,0) [0|3] "" Vector__XXX
 SG_ Joystick7Button7PressedStatus : 50|2@1+ (1,0) [0|3] "" Vector__XXX
 SG_ Joystick7Button8PressedStatus : 48|2@1+ (1,0) [0|3] "" Vector__XXX
 SG_ Joystick7Button1PressedStatus : 46|2@1+ (1,0) [0|3] "" Vector__XXX
 SG_ Joystick7Button2PressedStatus : 44|2@1+ (1,0) [0|3] "" Vector__XXX
 SG_ Joystick7Button3PressedStatus : 42|2@1+ (1,0) [0|3] "" Vector__XXX
 SG_ Joystick7Button4PressedStatus : 40|2@1+ (1,0) [0|3] "" Vector__XXX
 SG_ Joystick7XAxisDetentPosStatus : 38|2@1+ (1,0) [0|3] "" Vector__XXX
 SG_ Joystick7YAxisDetentPosStatus : 36|2@1+ (1,0) [0|3] "" Vector__XXX
 SG_ Joystick7YAxisPos : 22|10@1+ (0.1,0) [0|102] "%" Vector__XXX
 SG_ Jystck7YAxsLvrFrwrdPstvPosStatus : 20|2@1+ (1,0) [0|3] "" Vector__XXX
 SG_ Jystck7YAxsLvrBckNgtivePosStatus : 18|2@1+ (1,0) [0|3] "" Vector__XXX
 SG_ Joystick7YAxisNeutralPosStatus : 16|2@1+ (1,0) [0|3] "" Vector__XXX
 SG_ Joystick7XAxisPos : 6|10@1+ (0.1,0) [0|102] "%" Vector__XXX
 SG_ Jystck7XAxsLvrRghtPstvePosStatus : 4|2@1+ (1,0) [0|3] "" Vector__XXX
 SG_ Jystck7XAxsLvrLftNgtivePosStatus : 2|2@1+ (1,0) [0|3] "" Vector__XXX
 SG_ Joystick7XAxisNeutralPosStatus : 0|2@1+ (1,0) [0|3] "" Vector__XXX

BO_ 2365402366 BJM6: 8 Vector__XXX
 SG_ Joystick6Button9PressedStatus : 62|2@1+ (1,0) [0|3] "" Vector__XXX
 SG_ Joystick6Button10PressedStatus : 60|2@1+ (1,0) [0|3] "" Vector__XXX
 SG_ Joystick6Button11PressedStatus : 58|2@1+ (1,0) [0|3] "" Vector__XXX
 SG_ Joystick6Button12PressedStatus : 56|2@1+ (1,0) [0|3] "" Vector__XXX
 SG_ Joystick6Button5PressedStatus : 54|2@1+ (1,0) [0|3] "" Vector__XXX
 SG_ Joystick6Button6PressedStatus : 52|2@1+ (1,0) [0|3] "" Vector__XXX
 SG_ Joystick6Button7PressedStatus : 50|2@1+ (1,0) [0|3] "" Vector__XXX
 SG_ Joystick6Button8PressedStatus : 48|2@1+ (1,0) [0|3] "" Vector__XXX
 SG_ Joystick6Button1PressedStatus : 46|2@1+ (1,0) [0|3] "" Vector__XXX
 SG_ Joystick6Button2PressedStatus : 44|2@1+ (1,0) [0|3] "" Vector__XXX
 SG_ Joystick6Button3PressedStatus : 42|2@1+ (1,0) [0|3] "" Vector__XXX
 SG_ Joystick6Button4PressedStatus : 40|2@1+ (1,0) [0|3] "" Vector__XXX
 SG_ Joystick6XAxisDetentPosStatus : 38|2@1+ (1,0) [0|3] "" Vector__XXX
 SG_ Joystick6YAxisDetentPosStatus : 36|2@1+ (1,0) [0|3] "" Vector__XXX
 SG_ Joystick6YAxisPos : 22|10@1+ (0.1,0) [0|102] "%" Vector__XXX
 SG_ Jystck6YAxsLvrFrwrdPstvPosStatus : 20|2@1+ (1,0) [0|3] "" Vector__XXX
 SG_ Jystck6YAxsLvrBckNgtivePosStatus : 18|2@1+ (1,0) [0|3] "" Vector__XXX
 SG_ Joystick6YAxisNeutralPosStatus : 16|2@1+ (1,0) [0|3] "" Vector__XXX
 SG_ Joystick6XAxisPos : 6|10@1+ (0.1,0) [0|102] "%" Vector__XXX
 SG_ Jystck6XAxsLvrRghtPstvePosStatus : 4|2@1+ (1,0) [0|3] "" Vector__XXX
 SG_ Jystck6XAxsLvrLftNgtivePosStatus : 2|2@1+ (1,0) [0|3] "" Vector__XXX
 SG_ Joystick6XAxisNeutralPosStatus : 0|2@1+ (1,0) [0|3] "" Vector__XXX

BO_ 2365402878 BJM5: 8 Vector__XXX
 SG_ Joystick5Button9PressedStatus : 62|2@1+ (1,0) [0|3] "" Vector__XXX
 SG_ Joystick5Button10PressedStatus : 60|2@1+ (1,0) [0|3] "" Vector__XXX
 SG_ Joystick5Button11PressedStatus : 58|2@1+ (1,0) [0|3] "" Vector__XXX
 SG_ Joystick5Button12PressedStatus : 56|2@1+ (1,0) [0|3] "" Vector__XXX
 SG_ Joystick5Button5PressedStatus : 54|2@1+ (1,0) [0|3] "" Vector__XXX
 SG_ Joystick5Button6PressedStatus : 52|2@1+ (1,0) [0|3] "" Vector__XXX
 SG_ Joystick5Button7PressedStatus : 50|2@1+ (1,0) [0|3] "" Vector__XXX
 SG_ Joystick5Button8PressedStatus : 48|2@1+ (1,0) [0|3] "" Vector__XXX
 SG_ Joystick5Button1PressedStatus : 46|2@1+ (1,0) [0|3] "" Vector__XXX
 SG_ Joystick5Button2PressedStatus : 44|2@1+ (1,0) [0|3] "" Vector__XXX
 SG_ Joystick5Button3PressedStatus : 42|2@1+ (1,0) [0|3] "" Vector__XXX
 SG_ Joystick5Button4PressedStatus : 40|2@1+ (1,0) [0|3] "" Vector__XXX
 SG_ Joystick5XAxisDetentPosStatus : 38|2@1+ (1,0) [0|3] "" Vector__XXX
 SG_ Joystick5YAxisDetentPosStatus : 36|2@1+ (1,0) [0|3] "" Vector__XXX
 SG_ Joystick5YAxisPos : 22|10@1+ (0.1,0) [0|102] "%" Vector__XXX
 SG_ Jystck5YAxsLvrFrwrdPstvPosStatus : 20|2@1+ (1,0) [0|3] "" Vector__XXX
 SG_ Jystck5YAxsLvrBckNgtivePosStatus : 18|2@1+ (1,0) [0|3] "" Vector__XXX
 SG_ Joystick5YAxisNeutralPosStatus : 16|2@1+ (1,0) [0|3] "" Vector__XXX
 SG_ Joystick5XAxisPos : 6|10@1+ (0.1,0) [0|102] "%" Vector__XXX
 SG_ Jystck5XAxsLvrRghtPstvePosStatus : 4|2@1+ (1,0) [0|3] "" Vector__XXX
 SG_ Jystck5XAxsLvrLftNgtivePosStatus : 2|2@1+ (1,0) [0|3] "" Vector__XXX
 SG_ Joystick5XAxisNeutralPosStatus : 0|2@1+ (1,0) [0|3] "" Vector__XXX

BO_ 2365403390 BJM4: 8 Vector__XXX
 SG_ Joystick4Button9PressedStatus : 62|2@1+ (1,0) [0|3] "" Vector__XXX
 SG_ Joystick4Button10PressedStatus : 60|2@1+ (1,0) [0|3] "" Vector__XXX
 SG_ Joystick4Button11PressedStatus : 58|2@1+ (1,0) [0|3] "" Vector__XXX
 SG_ Joystick4Button12PressedStatus : 56|2@1+ (1,0) [0|3] "" Vector__XXX
 SG_ Joystick4Button5PressedStatus : 54|2@1+ (1,0) [0|3] "" Vector__XXX
 SG_ Joystick4Button6PressedStatus : 52|2@1+ (1,0) [0|3] "" Vector__XXX
 SG_ Joystick4Button7PressedStatus : 50|2@1+ (1,0) [0|3] "" Vector__XXX
 SG_ Joystick4Button8PressedStatus : 48|2@1+ (1,0) [0|3] "" Vector__XXX
 SG_ Joystick4Button1PressedStatus : 46|2@1+ (1,0) [0|3] "" Vector__XXX
 SG_ Joystick4Button2PressedStatus : 44|2@1+ (1,0) [0|3] "" Vector__XXX
 SG_ Joystick4Button3PressedStatus : 42|2@1+ (1,0) [0|3] "" Vector__XXX
 SG_ Joystick4Button4PressedStatus : 40|2@1+ (1,0) [0|3] "" Vector__XXX
 SG_ Joystick4XAxisDetentPosStatus : 38|2@1+ (1,0) [0|3] "" Vector__XXX
 SG_ Joystick4YAxisDetentPosStatus : 36|2@1+ (1,0) [0|3] "" Vector__XXX
 SG_ Joystick4YAxisPos : 22|10@1+ (0.1,0) [0|102] "%" Vector__XXX
 SG_ Jystck4YAxsLvrFrwrdPstvPosStatus : 20|2@1+ (1,0) [0|3] "" Vector__XXX
 SG_ Jystck4YAxsLvrBckNgtivePosStatus : 18|2@1+ (1,0) [0|3] "" Vector__XXX
 SG_ Joystick4YAxisNeutralPosStatus : 16|2@1+ (1,0) [0|3] "" Vector__XXX
 SG_ Joystick4XAxisPos : 6|10@1+ (0.1,0) [0|102] "%" Vector__XXX
 SG_ Jystck4XAxsLvrRghtPstvePosStatus : 4|2@1+ (1,0) [0|3] "" Vector__XXX
 SG_ Jystck4XAxsLvrLftNgtivePosStatus : 2|2@1+ (1,0) [0|3] "" Vector__XXX
 SG_ Joystick4XAxisNeutralPosStatus : 0|2@1+ (1,0) [0|3] "" Vector__XXX

CM_ BO_ 2566767870 "Electronic Brake Controller 5
Used for information on brake control.";
CM_ SG_ 2566767870 EmergencyBrakingActive "Signal which indicates an emergency braking situation (ref. ECE Regulation 13 paragraph 5.2.1.31) with high  deceleration values.  This signal can be used to activate the hazard lights (ref ECE Regulation 48 paragraph 6.23) to
indicate other road ...";
CM_ SG_ 2566767870 PrkngBrakeActuatorFullyActivated "Signal which indicates when the parking brake actuator is fully activated.  (see also SPN 70 and 619).

00 - Parking Brake Actuator not fully activated
01 - Parking Brake Actuator fully activated
10 - Error
11 - Not available";
CM_ SG_ 2566767870 XBRAccelerationLimit "The brake system may temporarily or generally limit the maximum brake performance available for external systems. A temporary limit may be nessary due to high brake temperature; a general limit may be defined by the vehicle manufacturer, e.g. a ...";
CM_ SG_ 2566767870 XBRActiveCtrlMode "This parameter indicates which XBR Control Mode is executed by the brake system.
0000                No brake demand being executed (default mode)
0001                Driver's brake demand being executed, no external brake demand
0010 ...";
CM_ SG_ 2566767870 XBRSystemState "This parameter indicates which external brake control is allowed.
00 - Any external brake demand will be accepted (brake system fully operational)
01 - Only external brake demand of highest XBR Priority (00) will be accepted  (e.g. because the ...";
CM_ SG_ 2566767870 FoundationBrakeUse "This parameter indicates if the brake system presently uses the foundation brakes.

00   Foundation brakes not in use
01   Foundation brakes in use
10   Reserved
11   Not available";
CM_ SG_ 2566767870 HillHolderMode "Signal which indicates the current mode of the hill holder function.
000            Inactive
001            Active
010            Active, but will change to inactive in a short time.  (This mode may be used to warn the driver)
011 ...";
CM_ SG_ 2566767870 HaltBrakeMode "Signal which indicates the current mode of the halt brake function.
000            Inactive
001            Active
010            Active, but not functioning properly.  (This mode may be used to warn the driver)
011 - 101  Not defined
110 ...";
CM_ SG_ 2566767870 BrakeTempWarning "This parameter indicates if the temperature in the service brakes exceeds a certain value. It can be used for a warning information for the driver. The temperature warning value is vehicle manufacturer specific.
00 Not Active
01 Active
10 ...";
CM_ BO_ 2633936126 "Wheel Brake Lining Remaining Information";
CM_ SG_ 2633936126 BrkLnngRmningRearAxle3RightWheel "The percentage of brake lining which can still be measured for the right wheel on the rear axle #3.  100% represents new brake linings, 0% represents totally worn brake linings.";
CM_ SG_ 2633936126 BrkLnngRminingRearAxle3LeftWheel "The percentage of brake lining which can still be measured for the left wheel on the rear axle #3.  100% represents new brake linings, 0% represents totally worn brake linings.";
CM_ SG_ 2633936126 BrkLnngRmningRearAxle2RightWheel "The percentage of brake lining which can still be measured for the right wheel on the rear axle #2.  100% represents new brake linings, 0% represents totally worn brake linings.";
CM_ SG_ 2633936126 BrkLnngRminingRearAxle2LeftWheel "The percentage of brake lining which can still be measured for the left wheel on the rear axle #2.  100% represents new brake linings, 0% represents totally worn brake linings.";
CM_ SG_ 2633936126 BrkLnngRmningRearAxle1RightWheel "The percentage of brake lining which can still be measured for the right wheel on the rear axle #1.  100% represents new brake linings, 0% represents totally worn brake linings.";
CM_ SG_ 2633936126 BrkLnngRminingRearAxle1LeftWheel "The percentage of brake lining which can still be measured for the left wheel on the rear axle #1.  100% represents new brake linings, 0% represents totally worn brake linings.";
CM_ SG_ 2633936126 BrkLnngRmningFrontAxleRightWheel "The percentage of brake lining which can still be measured for the right wheel on the front axle.  100% represents new brake linings, 0% represents totally worn brake linings.";
CM_ SG_ 2633936126 BrkLnngRminingFrontAxleLeftWheel "The percentage of brake lining which can still be measured for the left wheel on the front axle.  100% represents new brake linings, 0% represents totally worn brake linings.";
CM_ BO_ 2566827518 "Wheel Application Pressure High Range Information";
CM_ SG_ 2566827518 BrkAppPrssHghRngRrAxl3RightWheel "The brake application pressure for the right wheel on the rear axle #3.";
CM_ SG_ 2566827518 BrkAppPrssHghRngRrAxle3LeftWheel "The brake application pressure for the left wheel on the rear axle #3.";
CM_ SG_ 2566827518 BrkAppPrssHghRngRrAxl2RightWheel "The brake application pressure for the right wheel on the rear axle #2.";
CM_ SG_ 2566827518 BrkAppPrssHghRngRrAxle2LeftWheel "The brake application pressure for the left wheel on the rear axle #2.";
CM_ SG_ 2566827518 BrkAppPrssHghRngRrAxle1LeftWheel "The brake application pressure for the left wheel on the rear axle #1.";
CM_ SG_ 2566827518 BrkAppPrssHghRngFrntAxlRghtWheel "The brake application pressure for the right wheel on the front axle.";
CM_ SG_ 2566827518 BrkAppPrssHghRngFrntAxlLeftWheel "The brake application pressure for the left wheel on the front axle.";
CM_ SG_ 2566827518 BrkAppPrssHghRngRrAxl1RightWheel "The brake application pressure for the right wheel on the rear axle #1.";
CM_ BO_ 2566832126 "Wheel Speed Information";
CM_ SG_ 2566832126 RelativeSpeedRearAxle2RightWheel "The speed of the rear axle #2, right wheel relative to the front axle speed, SPN 904.";
CM_ SG_ 2566832126 RelativeSpeedRearAxle2LeftWheel "The speed of the rear axle #2, left wheel relative to the front axle speed, SPN 904.";
CM_ SG_ 2566832126 RelativeSpeedRearAxle1RightWheel "The speed of the rear axle #1, right wheel relative to the front axle speed, SPN 904.";
CM_ SG_ 2566832126 RelativeSpeedRearAxle1LeftWheel "The speed of the rear axle #1, left wheel relative to the front axle speed, SPN 904.";
CM_ SG_ 2566832126 RelativeSpeedFrontAxleRightWheel "The speed of the front axle, right wheel relative to the front axle speed, SPN 904.";
CM_ SG_ 2566832126 RelativeSpeedFrontAxleLeftWheel "The speed of the front axle, left wheel relative to the front axle speed, SPN 904.";
CM_ SG_ 2566832126 FrontAxleSpeed "The average speed of the two front wheels.";
CM_ BO_ 2565865982 "Electronic Brake Controller 1
Used for brake control information";
CM_ SG_ 2565865982 TrctrMntdTrailerABSWarningSignal "This parameter commands the tractor-mounted trailer ABS optical warning signal.

00 Off
01 On 
10 Reserved
11 Take no action";
CM_ SG_ 2565865982 TrailerABSStatus "State signal which indicates that ABS in the trailer is actively controlling the brakes.  A message is sent to the tractor from the trailer (i.e. by PLC). The receiving device in the tractor transfers this information to the J1939 network.  At the ...";
CM_ SG_ 2565865982 HaltBrakeSwitch "Switch signal which indicates the position of the halt brake switch.

00    Halt brake switch passive
01    Halt brake switch active
10    Error
11    Not available";
CM_ SG_ 2565865982 SrcAddrssOfCntrllngDvcFrBrkeCtrl "The source address of the SAE J1939 device currently controlling the brake system. Its value may be the source address of the ECU transmitting the message (which means that no external SAE J1939 message is providing the active command) or the source ...";
CM_ SG_ 2565865982 ATC_ASRInformationSignal "This parameter commands the ATC/ASR driver information signal, for example a dash lamp.

00 Off
01 On 
10 Reserved
11 Take no action";
CM_ SG_ 2565865982 ABS_EBSAmberWarningSignal "This parameter commands the ABS/EBS amber/yellow optical warning signal

00 Off
01 On
10 Reserved
11 Take no action";
CM_ SG_ 2565865982 EBSRedWarningSignal "This parameter commands the EBS red optical warning signal

00 Off
01 On
10 Reserved
11 Take no action";
CM_ SG_ 2565865982 ABSFullyOperational "Signal which indicates whether an ABS system is fully operational or whether its functionality is reduced by a defect or by an intended action (e.g., by activation of an ABS-off-road switch or during special diagnostic procedures).  There are cases ...";
CM_ SG_ 2565865982 EngRetarderSelection "The position of the operator controlled selector, expressed as a percentage and determined by the ratio of the current position of the selector to its maximum possible position. Zero percent means no braking torque is requested by the operator from ...";
CM_ SG_ 2565865982 RemoteAccelEnableSwitch "Switch signal which indicates that the remote accelerator has been enabled and controls the engine.
00 - Off
01 - On
10 - Error
11 - Not available
NOTE—The accelerator interlock switch (see SPN 972) must be disabled in order for the remote ...";
CM_ SG_ 2565865982 EngAuxShutdownSwitch "Switch signal which requests that all engine fueling stop.

00 - Off
01 - On
10 - Error
11 - Not available";
CM_ SG_ 2565865982 EngDerateSwitch "Switch signal used to activate the torque limiting feature of the engine.  The specific nature of torque limiting should be verified with the manufacturer.

00 - Off
01 - On
10 - Error
11 - Not available";
CM_ SG_ 2565865982 AccelInterlockSwitch "Switch signal used to disable the accelerator and remote accelerator inputs, causing the engine to return to idle.

00 - Off
01 - On
10 - Error
11 - Not available";
CM_ SG_ 2565865982 TractionCtrlOverrideSwitch "Switch signal which indicates the position of the traction control override switch.  The traction control override signal disables the automatic traction control function allowing the wheels to spin.
00 - Off
01 - On
10 - Error
11 - Not ...";
CM_ SG_ 2565865982 ASRHillHolderSwitch "Switch signal which indicates the position of the ASR “hill holder” switch.

00 - ASR “hill holder” switch passive
01 - ASR “hill holder” switch active
10 - Error
11 - Not available";
CM_ SG_ 2565865982 ASROffroadSwitch "Switch signal which indicates the position of the ASR off-road switch.

00 - ASR off-road switch passive
01 - ASR off-road switch active
10 - Error
11 - Not available";
CM_ SG_ 2565865982 ABSOffroadSwitch "Switch signal which indicates the position of the ABS off-road switch.

00 - ABS off-road switch passive
01 - ABS off-road switch active
10 - Error
11 - Not available";
CM_ SG_ 2565865982 BrakePedalPos "Ratio of brake pedal position to maximum pedal position.  Used for electric brake applications. 0% means no braking. Also when there are two brake pedals on the machine (Left Brake Pedal Position SPN 3033 and Right Brake Pedal Position SPN 3032) the ...";
CM_ SG_ 2565865982 EBSBrakeSwitch "Switch signal which indicates that the brake pedal is being pressed.  The EBS brake switch is independent of the brake light switch and has no provisions for external connections.
00 - Brake pedal is not being pressed
01 - Brake pedal is being ...";
CM_ SG_ 2565865982 AntiLockBrakingActive "State signal which indicates that the ABS is active.  The signal is set active when wheel brake pressure actually starts to be modulated by ABS and is reset to passive when all wheels are in a stable condition for a certain time.  The signal can ...";
CM_ SG_ 2565865982 ASRBrakeCtrlActive "State signal which indicates that ASR brake control is active. Active means that ASR actually controls wheel brake pressure at one or more wheels of the driven axle(s).
00 - ASR brake control passive but installed
01 - ASR brake control active
10 ...";
CM_ SG_ 2565865982 ASREngCtrlActive "State signal which indicates that ASR engine control has been commanded to be active. Active means that ASR actually tries to control the engine. This state signal is independent of other control commands to the engine (e.g., from the transmission) ...";
CM_ BO_ 2565867262 "Electronic Axle Controller 1
NOTE - Request has to be responded to with as many messages as necessary to transmit all available information.";
CM_ SG_ 2565867262 DiffLockStRearAxle3 "State used which indicates the condition of the rear axle 3 differential lock. The differential locks are located as defined in figure SPN 564_A.
[Ed note:  Forum comment resolution is in process.  The figure may need to be updated further and/or ...";
CM_ SG_ 2565867262 RearAxleGroupEngagementStatus "Rear axle group engagement status

00 rear axle group disengaged 
01 rear axle group engaged
10 error
11 not available";
CM_ SG_ 2565867262 FrontAxleGroupEngagementStatus "Front axle group engagement status 

00 front axle group disengaged 
01 front axle group engaged
10 error
11 not available";
CM_ SG_ 2565867262 DiffLockStateCentralRear "State used which indicates the condition of the central rear differential lock.  The differential locks are located as defined in figure SPN564_A.

00 Differential lock disengaged
01 Differential lock engaged
10 Error
11 Not available";
CM_ SG_ 2565867262 DiffLockStateCentralFront "State used which indicates the condition of the central front differential lock.  The differential locks are located as defined in figure SPN564_A.

00 Differential lock disengaged
01 Differential lock engaged
10 Error
11 Not available";
CM_ SG_ 2565867262 DiffLockStateCentral "State used which indicates the condition of the central differential lock.  The differential locks are located as defined in attached figure SPN564_A.

00 Differential lock disengaged
01 Differential lock engaged
10 Error
11 Not available";
CM_ SG_ 2565867262 DiffLockStateRearAxle2 "State used which indicates the condition of the rear axle 2 differential lock.  The differential locks are located as defined in figure SPN 564_A.

00 Differential lock disengaged
01 Differential lock engaged
10 Error
11 Not available";
CM_ SG_ 2565867262 DiffLockStateRearAxle1 "State used which indicates the condition of the rear axle 1 differential lock.  The differential locks are located as defined in figure SPN 564_A.

00 Differential lock disengaged
01 Differential lock engaged
10 Error
11 Not available";
CM_ SG_ 2565867262 DiffLockStateFrontAxle2 "State used which indicates the condition of the front axle 2 differential lock. The differential locks are located as defined in figure SPN 564_A.

00 Differential lock disengaged
01 Differential lock engaged
10 Error
11 Not available";
CM_ SG_ 2565867262 DiffLockStateFrontAxle1 "State used which indicates the condition of the front axle 1 differential lock.  The differential locks are located as defined in figure SPN564_A.

00 Differential lock disengaged
01 Differential lock engaged
10 Error
11 Not available";
CM_ SG_ 2565867262 Location "To identify to which of several similar devices (such as tires or fuel tanks) the information applies.
The low order 4 bits represent a position number, counting left to right when facing in the direction of normal vehicle travel (forward).
The ...";
CM_ BO_ 2566821118 "Engine Auxiliary Coolant";
CM_ SG_ 2566821118 EngCoolantPress2 "Gage pressure of liquid found in engine coolant system - second instance.

See also SPN 5708 for alternate range and resolution.";
CM_ SG_ 2566821118 EngExRangeCoolantPress "Gage pressure of liquid found in engine cooling system.

See also SPN 109 for alternate range and resolution.";
CM_ SG_ 2566821118 SeaWaterPumpOutletPress "Gauge pressure of liquid found at outlet of sea water pump in sea water cooling system.";
CM_ SG_ 2566821118 EngAuxCoolantTemp "Temperature of coolant found in the intercooler which is located after the turbocharger.";
CM_ SG_ 2566821118 EngAuxCoolantPress "Gage pressure of coolant found in the intercooler which is located after the turbocharger.";
CM_ BO_ 2566810622 "Driver's Identification
Field:
a Driver 1 Identification
Delimiter (ASCII “*”)
b Driver 2 Identification
Delimiter (ASCII “*”)
NOTE - If only driver card 1 is present, only the parameter driver 1 identification and two delimiters shall be ...";
CM_ SG_ 2566810622 Driver2Identification "Used to obtain the driver identity.";
CM_ SG_ 2566810622 Driver1Identification "Used to obtain the driver identity.";
CM_ BO_ 2566847742 "Dash Display 1";
CM_ SG_ 2566847742 EngOilFilterDiffPress7471 "Change in engine oil pressure, measured across the filter, due to the filter and any accumulation of solid or semisolid material on or in the filter. See SPN 99 for alternate resolution.";
CM_ SG_ 2566847742 FuelLevel2 "Ratio of volume of fuel to the total volume of fuel in the second or right-side storage container.  When Fuel Level 2 is not used, Fuel Level 1 (SPN 96) represents the total fuel in all fuel storage containers.";
CM_ SG_ 2566847742 CargoAmbientTemp "Temperature of air inside vehicle container used to accommodate cargo.";
CM_ SG_ 2566847742 EngOilFilterDiffPress "Change in engine oil pressure, measured across the filter, due to the filter and any accumulation of solid or semisolid material on or in the filter.  See SPN 7471 for alternate resolution.";
CM_ SG_ 2566847742 EngFuelFilterDiffPress "Change in fuel delivery pressure, measured across the filter, due to accumulation of solid or semisolid matter on the filter element.";
CM_ SG_ 2566847742 FuelLevel1 "Ratio of volume of fuel to the total volume of fuel storage container.
When Fuel Level 2 (SPN 38) is not used, Fuel Level 1 represents the total fuel in all fuel storage containers.  When Fuel Level 2 is used, Fuel Level 1 represents the fuel level ...";
CM_ SG_ 2566847742 WasherFluidLevel "Ratio of volume of liquid to total container volume of fluid reservoir in windshield wash system.";
CM_ BO_ 2498778622 "Engine Cylinder 8 Combustion Average Information
Used to transmit the average of combustion parameters of Engine Cylinder 8.
This PGN is transmitted at a defined ratio of the engine speed. The transmission rate is dependent on
SPN 6394 - Number ...";
CM_ SG_ 2498778622 EngCyl8AverageCombustionDuration "Average duration of combustion calculated over defined number of combustion cycles for engine cylinder 8 with reference to the crank angle.  Combustion duration is the difference between end of combustion and start of combustion expressed, in this ...";
CM_ SG_ 2498778622 EngCyl8AvrgCntrOfCmbustionTiming "Average timing calculated over defined number of combustion cycles for the center of combustion in engine cylinder 8 with reference to the crank angle.  Center of Combustion is used to indicate the combustion efficiency.  When the combustion happens ...";
CM_ SG_ 2498778622 EngCyl8AvrgStrtOfCmbustionTiming "Average start of combustion timing calculated over defined number of combustion cycles for engine cylinder 8 with reference to the crank angle.  When the combustion happens after the TDC (Top Dead Center) of this cylinder, the timing is referred in ...";
CM_ SG_ 2498778622 EngCyl8IndctedMeanEffectivePress "Average cylinder pressure calculated over defined number of combustion cycles for engine cylinder 8.  Negative range is to cover thermodynamic behavior during misfire.";
CM_ BO_ 2498778366 "Engine Cylinder 7 Combustion Average Information
Used to transmit the average of combustion parameters of Engine Cylinder 7.
This PGN is transmitted at a defined ratio of the engine speed. The transmission rate is dependent on
SPN 6394 - Number ...";
CM_ SG_ 2498778366 EngCyl7AverageCombustionDuration "Average duration of combustion calculated over defined number of combustion cycles for engine cylinder 7 with reference to the crank angle.  Combustion duration is the difference between end of combustion and start of combustion expressed, in this ...";
CM_ SG_ 2498778366 EngCyl7AvrgCntrOfCmbustionTiming "Average timing calculated over defined number of combustion cycles for the center of combustion in engine cylinder 7 with reference to the crank angle.  Center of Combustion is used to indicate the combustion efficiency.  When the combustion happens ...";
CM_ SG_ 2498778366 EngCyl7AvrgStrtOfCmbustionTiming "Average start of combustion timing calculated over defined number of combustion cycles for engine cylinder 7 with reference to the crank angle.  When the combustion happens after the TDC (Top Dead Center) of this cylinder, the timing is referred in ...";
CM_ SG_ 2498778366 EngCyl7IndctedMeanEffectivePress "Average cylinder pressure calculated over defined number of combustion cycles for engine cylinder 7.  Negative range is to cover thermodynamic behavior during misfire.";
CM_ BO_ 2498778110 "Engine Cylinder 6 Combustion Average Information
Used to transmit the average of combustion parameters of Engine Cylinder 6.
This PGN is transmitted at a defined ratio of the engine speed. The transmission rate is dependent on
SPN 6394 - Number ...";
CM_ SG_ 2498778110 EngCyl6AverageCombustionDuration "Average duration of combustion calculated over defined number of combustion cycles for engine cylinder 6 with reference to the crank angle.  Combustion duration is the difference between end of combustion and start of combustion expressed, in this ...";
CM_ SG_ 2498778110 EngCyl6AvrgCntrOfCmbustionTiming "Average timing calculated over defined number of combustion cycles for the center of combustion in engine cylinder 6 with reference to the crank angle.  Center of Combustion is used to indicate the combustion efficiency.  When the combustion happens ...";
CM_ SG_ 2498778110 EngCyl6AvrgStrtOfCmbustionTiming "Average start of combustion timing calculated over defined number of combustion cycles for engine cylinder 6 with reference to the crank angle.  When the combustion happens after the TDC (Top Dead Center) of this cylinder, the timing is referred in ...";
CM_ SG_ 2498778110 EngCyl6IndctedMeanEffectivePress "Average cylinder pressure calculated over defined number of combustion cycles for engine cylinder 6.  Negative range is to cover thermodynamic behavior during misfire.";
CM_ BO_ 2498777854 "Engine Cylinder 5 Combustion Average Information
Used to transmit the average of combustion parameters of Engine Cylinder 5.
This PGN is transmitted at a defined ratio of the engine speed. The transmission rate is dependent on
SPN 6394 - Number ...";
CM_ SG_ 2498777854 EngCyl5AverageCombustionDuration "Average duration of combustion calculated over defined number of combustion cycles for engine cylinder 5 with reference to the crank angle.  Combustion duration is the difference between end of combustion and start of combustion expressed, in this ...";
CM_ SG_ 2498777854 EngCyl5AvrgCntrOfCmbustionTiming "Average timing calculated over defined number of combustion cycles for the center of combustion in engine cylinder 5 with reference to the crank angle.  Center of Combustion is used to indicate the combustion efficiency.  When the combustion happens ...";
CM_ SG_ 2498777854 EngCyl5AvrgStrtOfCmbustionTiming "Average start of combustion timing calculated over defined number of combustion cycles for engine cylinder 5 with reference to the crank angle.  When the combustion happens after the TDC (Top Dead Center) of this cylinder, the timing is referred in ...";
CM_ SG_ 2498777854 EngCyl5IndctedMeanEffectivePress "Average cylinder pressure calculated over defined number of combustion cycles for engine cylinder 5.  Negative range is to cover thermodynamic behavior during misfire.";
CM_ BO_ 2498777598 "Engine Cylinder 4 Combustion Average Information
Used to transmit the average of combustion parameters of Engine Cylinder 4.
This PGN is transmitted at a defined ratio of the engine speed. The transmission rate is dependent on
SPN 6394 - Number ...";
CM_ SG_ 2498777598 EngCyl4AverageCombustionDuration "Average duration of combustion calculated over defined number of combustion cycles for engine cylinder 4 with reference to the crank angle.  Combustion duration is the difference between end of combustion and start of combustion expressed, in this ...";
CM_ SG_ 2498777598 EngCyl4AvrgCntrOfCmbustionTiming "Average timing calculated over defined number of combustion cycles for the center of combustion in engine cylinder 4 with reference to the crank angle.  Center of Combustion is used to indicate the combustion efficiency.  When the combustion happens ...";
CM_ SG_ 2498777598 EngCyl4AvrgStrtOfCmbustionTiming "Average start of combustion timing calculated over defined number of combustion cycles for engine cylinder 4 with reference to the crank angle.  When the combustion happens after the TDC (Top Dead Center) of this cylinder, the timing is referred in ...";
CM_ SG_ 2498777598 EngCyl4IndctedMeanEffectivePress "Average cylinder pressure calculated over defined number of combustion cycles for engine cylinder 4.  Negative range is to cover thermodynamic behavior during misfire.";
CM_ BO_ 2498777342 "Engine Cylinder 3 Combustion Average Information
Used to transmit the average of combustion parameters of Engine Cylinder 3.
This PGN is transmitted at a defined ratio of the engine speed. The transmission rate is dependent on
SPN 6394 - Number ...";
CM_ SG_ 2498777342 EngCyl3AverageCombustionDuration "Average duration of combustion calculated over defined number of combustion cycles for engine cylinder 3 with reference to the crank angle.  Combustion duration is the difference between end of combustion and start of combustion expressed, in this ...";
CM_ SG_ 2498777342 EngCyl3AvrgCntrOfCmbustionTiming "Average timing calculated over defined number of combustion cycles for the center of combustion in engine cylinder 3 with reference to the crank angle.  Center of Combustion is used to indicate the combustion efficiency.  When the combustion happens ...";
CM_ SG_ 2498777342 EngCyl3AvrgStrtOfCmbustionTiming "Average start of combustion timing calculated over defined number of combustion cycles for engine cylinder 3 with reference to the crank angle.  When the combustion happens after the TDC (Top Dead Center) of this cylinder, the timing is referred in ...";
CM_ SG_ 2498777342 EngCyl3IndctedMeanEffectivePress "Average cylinder pressure calculated over defined number of combustion cycles for engine cylinder 3.  Negative range is to cover thermodynamic behavior during misfire.";
CM_ BO_ 2566768382 "Cold Start Aids
Cold start aid information and settings.";
CM_ SG_ 2566768382 EngCldStrtFlIgniterRelayFeedback "Feedback state of the engine cold start fuel igniter relay which indicates the status of the relay output.

00  Off
01  On
10  Error
11  Not available";
CM_ SG_ 2566768382 EngColdStartFuelIgniterRelay "The engine cold start fuel igniter relay control command.  This command controls the relay, not the igniter.

00  Off
01  On
10  Reserved
11  Don't care/take no action";
CM_ SG_ 2566768382 EngColdStartFuelIgniterCmd "The engine cold start fuel igniter control command, normalized to %, where 0% represents fully off and 100% represents fully on.";
CM_ SG_ 2566768382 EngStartEnableDevice2Config "The start enable device installed for start enable device 2.
0000 - no start enable device 2 installed
0001 - glow plugs installed
0010 - fuelled start installed
0011 - ether injection installed
0100 - electric intake air heater installed
0101 ...";
CM_ SG_ 2566768382 EngStartEnableDevice1Config "The start enable device installed for start enable device 1.
0000 - no start enable device 1 installed
0001 - glow plugs installed
0010 - fuelled start installed
0011 - ether injection installed
0100 - electric intake air heater installed
0101 ...";
CM_ SG_ 2566768382 EngStartEnableDevice2 "Devices that assist an engine in starting, e.g. intake heaters, ether, or an alternate/secondary starting aid.  May be of the same type or different than Start Enable Device 1 (SPN 626). Parameter indicating whether the start enable device 2 is ON ...";
CM_ SG_ 2566768382 EngStartEnableDevice1 "Devices that assist an Engine in starting, e.g. intake heaters and ether.  Primary starting aid.
Parameter indicating whether the start enable device 1 is ON or OFF

00 - start enable OFF
01 - start enable ON
10 - reserved
11 - not available";
CM_ BO_ 2566811902 "Combination Vehicle Weight";
CM_ SG_ 2566811902 PoweredVehicleWeight "Total mass imposed by the tires of the powered vehicle on the road surface.  Does not include the trailer.";
CM_ SG_ 2566811902 GrossCombinationVehicleWeight "The total weight of the truck and all attached trailers.";
CM_ BO_ 2563768062 "Continuous Torque & Speed Limit Request";
CM_ SG_ 2563768062 MxCntinuousRetarderTorqueLimitRq "Requested maximum continuous retarder torque (operating range: -125 to 0%)";
CM_ SG_ 2563768062 MnCntinuousRetarderTorqueLimitRq "Requested minimum continuous retarder torque (operating range: -125 to 0%)";
CM_ SG_ 2563768062 MxContinuousRetarderSpeedLimitRq "Requested maximum continuous retarder speed";
CM_ SG_ 2563768062 MnContinuousRetarderSpeedLimitRq "Requested minimum continuous retarder speed";
CM_ SG_ 2563768062 EngTorqueLimitRqMaxContinuous "Requested maximum continuous engine torque (operating range: 0 to 125%)";
CM_ SG_ 2563768062 EngTorqueLimitRqMinContinuous "Requested minimum continuous engine torque (operating range: 0 to 125%)";
CM_ SG_ 2563768062 EngSpeedLimitRqMaxContinuous "Requested maximum continuous engine speed";
CM_ SG_ 2563768062 EngSpeedLimitRqMinContinuous "Requested minimum continuous engine speed";
CM_ BO_ 2633924862 "Combustion Time 6";
CM_ SG_ 2633924862 EngAverageCombustionTime "The average combustion time of all cylinders of an engine.";
CM_ SG_ 2633924862 EngDesiredCombustionTime "The desired combustion time based upon engine load and speed lookup maps.";
CM_ BO_ 2633924606 "Combustion Time 5";
CM_ SG_ 2633924606 EngCyl20CombustionTime "The amount of time from when the ignition of the fuel is initiated to when the fuel is completely ignited (i.e., the flame front has propagated across the cylinder).";
CM_ SG_ 2633924606 EngCyl19CombustionTime "The amount of time from when the ignition of the fuel is initiated to when the fuel is completely ignited (i.e., the flame front has propagated across the cylinder).";
CM_ SG_ 2633924606 EngCyl18CombustionTime "The amount of time from when the ignition of the fuel is initiated to when the fuel is completely ignited (i.e., the flame front has propagated across the cylinder).";
CM_ SG_ 2633924606 EngCyl17CombustionTime "The amount of time from when the ignition of the fuel is initiated to when the fuel is completely ignited (i.e., the flame front has propagated across the cylinder).";
CM_ BO_ 2633924350 "Combustion Time 4";
CM_ SG_ 2633924350 EngCyl16CombustionTime "The amount of time from when the ignition of the fuel is initiated to when the fuel is completely ignited (i.e., the flame front has propagated across the cylinder).";
CM_ SG_ 2633924350 EngCyl15CombustionTime "The amount of time from when the ignition of the fuel is initiated to when the fuel is completely ignited (i.e., the flame front has propagated across the cylinder).";
CM_ SG_ 2633924350 EngCyl14CombustionTime "The amount of time from when the ignition of the fuel is initiated to when the fuel is completely ignited (i.e., the flame front has propagated across the cylinder).";
CM_ SG_ 2633924350 EngCyl13CombustionTime "The amount of time from when the ignition of the fuel is initiated to when the fuel is completely ignited (i.e., the flame front has propagated across the cylinder).";
CM_ BO_ 2633924094 "Combustion Time 3";
CM_ SG_ 2633924094 EngCyl12CombustionTime "The amount of time from when the ignition of the fuel is initiated to when the fuel is completely ignited (i.e., the flame front has propagated across the cylinder).";
CM_ SG_ 2633924094 EngCyl11CombustionTime "The amount of time from when the ignition of the fuel is initiated to when the fuel is completely ignited (i.e., the flame front has propagated across the cylinder).";
CM_ SG_ 2633924094 EngCyl10CombustionTime "The amount of time from when the ignition of the fuel is initiated to when the fuel is completely ignited (i.e., the flame front has propagated across the cylinder).";
CM_ SG_ 2633924094 EngCyl9CombustionTime "The amount of time from when the ignition of the fuel is initiated to when the fuel is completely ignited (i.e., the flame front has propagated across the cylinder).";
CM_ BO_ 2633923838 "Combustion Time 2";
CM_ SG_ 2633923838 EngCyl8CombustionTime "The amount of time from when the ignition of the fuel is initiated to when the fuel is completely ignited (i.e., the flame front has propagated across the cylinder).";
CM_ SG_ 2633923838 EngCyl7CombustionTime "The amount of time from when the ignition of the fuel is initiated to when the fuel is completely ignited (i.e., the flame front has propagated across the cylinder).";
CM_ SG_ 2633923838 EngCyl6CombustionTime "The amount of time from when the ignition of the fuel is initiated to when the fuel is completely ignited (i.e., the flame front has propagated across the cylinder).";
CM_ SG_ 2633923838 EngCyl5CombustionTime "The amount of time from when the ignition of the fuel is initiated to when the fuel is completely ignited (i.e., the flame front has propagated across the cylinder).";
CM_ BO_ 2633923582 "Combustion Time 1";
CM_ SG_ 2633923582 EngCyl4CombustionTime "The amount of time from when the ignition of the fuel is initiated to when the fuel is completely ignited (i.e., the flame front has propagated across the cylinder).";
CM_ SG_ 2633923582 EngCyl3CombustionTime "The amount of time from when the ignition of the fuel is initiated to when the fuel is completely ignited (i.e., the flame front has propagated across the cylinder).";
CM_ SG_ 2633923582 EngCyl2CombustionTime "The amount of time from when the ignition of the fuel is initiated to when the fuel is completely ignited (i.e., the flame front has propagated across the cylinder).";
CM_ SG_ 2633923582 EngCyl1CombustionTime "The amount of time from when the ignition of the fuel is initiated to when the fuel is completely ignited (i.e., the flame front has propagated across the cylinder).";
CM_ BO_ 2633878014 "Electronic Control Module Information
Information relating to electronic control modules";
CM_ SG_ 2633878014 TotalCountOfConfigChangesMade "Total number of times changes have been made to any of the configurable parameters.";
CM_ BO_ 2566771966 "Cab Message 3
Provides information from Cab mounted operator inputs.";
CM_ SG_ 2566771966 VehTrailerStatus "Indicates a trailer is connected to the towing mechanism.  This is not intended to indicate that the trailer is latched.

00 - Trailer is not detected
01 - Trailer is detected
10 - Error
11 - Not available";
CM_ SG_ 2566771966 TransOilLevelRq "Conveys operator or vehicle system desire for a transmission oil level reading to be taken. 

00 - No transmission oil level reading desired
01 - Transmission oil level reading desired
10 - Reserved
11 - Don't care / take no action";
CM_ SG_ 2566771966 FifthWheelReleaseCtrl "Operator input used to release the fifth wheel. Fifth Wheel Release Control Security Lockout and other conditions must be properly enabled before this will function.
00   Coupler Locked
01   Coupler Unlocked, trailer can be unhitched or hitched
 ...";
CM_ SG_ 2566771966 FfthWhlRleaseCtrlSecurityLockout "Operator's fifth wheel release control interlock. This operator input must be enabled prior to activating the fifth wheel release control (SPN 3314).
00    Fifth wheel release Disabled
01    Fifth wheel release Enabled
10    Error
11    Not ...";
CM_ SG_ 2566771966 TransferCaseSelectorSwitch "Operator switch to select the condition of the transfer case.  States 000 and 001 should be used if the transfer case only functions to switch between 2-wheel and 4-wheel drive.  If the transfer case includes a High / Low Range function, states 011 ...";
CM_ BO_ 2564882174 "Cab Message 1
Message containing parameters originating from the vehicle cab.";
CM_ SG_ 2564882174 SelectedMaxVehicleSpeedLimit "User selected maximum vehicle speed.  If one is selected, then this SPN must equal one of the maximum vehicle speeds #1-#7 from PGN 64997 - Maximum Vehicle Speed Limit Status . If different maximum vehicle speed requests are present from different ...";
CM_ SG_ 2564882174 RqCabZoneHeating "Request to activate cab zone heating.

00 Do not heat cab engine zone
01 Heat cab zone
10 Reserved
11 Don't care/take no action";
CM_ SG_ 2564882174 RqEngZoneHeating "Request to activate engine zone heating.

00 Do not heat engine zone
01 Heat engine zone
10 Reserved
11 Don't care/take no action";
CM_ SG_ 2564882174 AuxHeaterModeRq "Request to activate the auxiliary heater.
0000 De-activate auxiliary heater
0001 Off due to ADR per European Regulations for Transport of hazardous materials
0010 Economy mode
0011 Normal mode
0100 Heater pump up-keep
0101-1000 Reserved
 ...";
CM_ SG_ 2564882174 EngAutomaticStartEnableSwitch "Switch signal which enables the idle management system to be enabled. When this system is enabled with the engine in an idle mode and safe operating conditions existing, then the engine may be started or stopped automatically.
00 - Switch in the ...";
CM_ SG_ 2564882174 AtomaticGearShiftingEnableSwitch "Indicates that automated gear shifting is enabled via a switch

    00 = Automated Gear Shifting is disabled
    01 = Automated Gear Shifting is enabled
    10 = Error
    11 = Not available";
CM_ SG_ 2564882174 AFTRegenForceSw "Indicates the state of a switch available to the operator that forces aftertreatment regeneration.
00 not active
01 active
10 error
11 not available
This SPN would be “not active” when aftertreatment regeneration is allowed to occur normally ...";
CM_ SG_ 2564882174 AFTRegenInhSw "Indicates the state of a switch available to the operator that inhibits aftertreatment regeneration.
00 not active
01 active
10 error
11 not available
This SPN would be “not active” when aftertreatment regeneration is allowed to occur normally ...";
CM_ SG_ 2564882174 VhclLmtngSpdGovernorEnableSwitch "Switch signal which enables the Vehicle Limiting Speed Governor (VLSG) such that the vehicle speed may be either increased or decreased when the engine is off idle.

00 - Switch disabled
01 - Switched enabled
10 - Error
11 - Not available";
CM_ SG_ 2564882174 VhclLmtngSpdGvrnrIncrementSwitch "Switch signal which increases the Vehicle Limiting Speed Governor (VLSG).

00 - Switch in the off state
01 - Switch in the on state - increase
10 - Error
11 - Not available";
CM_ SG_ 2564882174 VhclLmtngSpdGvrnrDecrementSwitch "Switch signal which decreases the Vehicle Limiting Speed Governor (VLSG).

00 - Switch in the off state
01 - Switch in the on state - decrease
10 - Error
11 - Not available";
CM_ SG_ 2564882174 ParkBrakeCmd "Request by a secondary device to command the Park Brake.  The Park Brake controller should treat this as a request and should apply the Park Brake as determined by the controller.
Feedback of the park brake actuation may utilize SPN 70, SPN 619 or ...";
CM_ SG_ 2564882174 SeatBeltSwitch "State of switch used to determine if Seat Belt is buckled

00 NOT Buckled
01 OK - Seat Belt is buckled
10 Error - Switch state cannot be determined
11 Not Available";
CM_ SG_ 2564882174 OperatorSeatDirectionSwitch "Senses whether the operator seat is in the forward driving position

00 Operator seat not facing forward
01 Operator seat is facing forward
10 Error
11 Not Available";
CM_ SG_ 2564882174 BatteryMainSwitchHoldRq "Request to hold the battery main switch.

00 Release Battery Main Switch
01 Hold Battery Main Switch
10 undefined
11 Don't care/take no action";
CM_ SG_ 2564882174 AuxHeaterCoolantPumpRq "Indicates whether to activate the auxiliary heater coolant water pump.

00 Deactivate water pump
01 Activate water pump
10 Reserved
11 Don't care/take no action";
CM_ SG_ 2564882174 CabInteriorTempCmd "Parameter used to command a certain cab interior temperature.

Note: See also SPN 170.  SPN 1662 is an additional diagnostic SPN associated with cab temperature.";
CM_ SG_ 2564882174 RequestedPercentFanSpeed "Fan speed of the first or only fan in the system as a ratio of the actual fan drive (current speed) to the fully engaged fan drive (maximum fan speed). A two state fan (off/on) will use 0% and 100% respectively. A three state fan ...";
CM_ BO_ 2563833598 "Cab Illumination Message
This message contains information that controls illumination devices inside the vehicle's cab.";
CM_ SG_ 2563833598 SwtchBcklghtIllmntnBrghtnssPrcnt "Commanded switch backlight brightness level for all operator control switches.  This is separate from the cab display illumination Brightness Percent parameter.
Note:  If a single device is used to control both the backlight brightness level of the ...";
CM_ SG_ 2563833598 IlluminationBrightnessPercent "Commanded backlight brightness level for all cab displays.  

Note:  If a separate device is used to independently control the switch backlight brightness level, see SPN 5532.";
CM_ SG_ 2563833598 SwtchIndctnIllmntnBrghtnssPrcent "Commanded switch indication illumination brightness level for all operator control switches. This is separate from the cab display illumination Brightness Percent parameter.
Note: If a single device is used to control both the indication brightness ...";
CM_ BO_ 2566843390 "Component Identification
NOTE - The make, model, serial number and unit number fields in this message are optional and separated by an ASCII “*”.  It is not necessary to include all fields; however, the delimiter (“*”) is always required.
Field:
 ...";
CM_ SG_ 2566843390 UnitNumber "Owner assigned unit number for the power unit of the vehicle.

NOTE: The ASCII character \"*\" is reserved as a delimiter.";
CM_ SG_ 2566843390 SerialNumber "Serial number of the component.

NOTE - The ASCII character \"*\" is reserved as a delimiter.";
CM_ SG_ 2566843390 Model "Model of the component.

NOTE - The ASCII character \"*\" is reserved as a delimiter.";
CM_ SG_ 2566843390 Make "Make of the component corresponding to the codes defined in the American Trucking Association Vehicle Maintenance Reporting Standard (ATA/VMRS).
Note:  This parameter is to be transmitted as a 5 character ASCII string;  as a zero length string, if ...";
CM_ BO_ 2566844926 "Cruise Control/Vehicle Speed 1
Cruise Control/Vehicle Speed 1";
CM_ SG_ 2566844926 EngShutdownOverrideSwitch "Switch signal which indicates the position of the engine shutdown override switch.  This switch function allows the operator to override an impending engine shutdown.

00 - Off
01 - On
10 - Error
11 - Not available";
CM_ SG_ 2566844926 EngTestModeSwitch "Switch signal which indicates the position of the engine diagnostic test mode switch.

00 - Off
01 - On
10 - Error
11 - Not available";
CM_ SG_ 2566844926 EngIdleDecrementSwitch "Switch signal which indicates the position of the idle decrement switch.

00 - Off
01 - On
10 - Error
11 - Not available";
CM_ SG_ 2566844926 EngIdleIncrementSwitch "Switch signal which indicates the position of the idle increment switch.

00 - Off
01 - On
10 - Error
11 - Not available";
CM_ SG_ 2566844926 CruiseCtrlStates "This parameter is used to indicate the current state, or mode, of operation by the cruise control device.  This is a status parameter.
000 - Off/Disabled
001 - Hold
010 - Accelerate
011 - Decelerate
100 - Resume
101 - Set
110 - Accelerator ...";
CM_ SG_ 2566844926 PTOGovernorState "This parameter is used to indicate the current state or mode of operation by the power takeoff (PTO) governor.  In lieu of support for PTO Drive Engagement parameters, this parameter may represent the status of a PTO drive.  The broadcasting device ...";
CM_ SG_ 2566844926 CruiseCtrlSetSpeed "Value of set (chosen) velocity of velocity control system.  See SPN 6809 for an alternate resolution.
If an algorithm that can modify the cruise control set point exists in the system, such as Predictive Cruise Control or Adaptive Cruise Control, ...";
CM_ SG_ 2566844926 CruiseCtrlAccelerateSwitch "Switch signal of the cruise control activator which indicates that the activator is in the position “accelerate.”
00 - Cruise control activator not in the position “accelerate”
01 - Cruise control activator in position “accelerate”
10 - Error
11 ...";
CM_ SG_ 2566844926 CruiseCtrlResumeSwitch "Switch signal of the cruise control activator which indicates that the activator is in the position “resume.”
00 - Cruise control activator not in the position “resume”
01 - Cruise control activator in position “resume”
10 - Error
11 - Not ...";
CM_ SG_ 2566844926 CruiseCtrlCoastSwitch "Switch signal of the cruise control activator which indicates that the activator is in the position “coast (decelerate).”
00 - Cruise control activator not in the position “coast”
01 - Cruise control activator in position “coast”
10 - Error
11 - ...";
CM_ SG_ 2566844926 CruiseCtrlSetSwitch "Switch signal of the cruise control activator which indicates that the activator is in the position “set.”

00 - Cruise control activator not in the position “set”
01 - Cruise control activator in position “set”
10 - Error
11 - Not available";
CM_ SG_ 2566844926 ClutchSwitch "Switch signal which indicates that the clutch pedal is being pressed. It is necessary for a safe drivetrain behavior that the clutch switch is set before the clutch is opened (cruise control function).
00 - Clutch pedal released
01 - Clutch pedal ...";
CM_ SG_ 2566844926 BrakeSwitch "Switch signal which indicates that the driver operated brake foot pedal is being pressed.  This brake foot pedal is controlling the vehicles’ service brake (total vehicle braking application, not park brakes).  It is necessary for safe drivetrain ...";
CM_ SG_ 2566844926 CruiseCtrlEnableSwitch "Switch signal which indicates that it is possible to manage the cruise control function.

00 - Cruise control disabled
01 - Cruise control enabled
10 - Error
11 - Not available";
CM_ SG_ 2566844926 CruiseCtrlActive "Cruise control is switched on.  It is not ensured that the engine is controlled by cruise control, as in the case of a large driver's demand the engine is controlled by the driver while cruise control is active (maximum selection of cruise control ...";
CM_ SG_ 2566844926 WheelBasedVehicleSpeed "Speed of the vehicle as calculated from wheel or tailshaft speed.";
CM_ SG_ 2566844926 ParkBrakeReleaseInhibitRq "Park Brake Release Inhibit Request signals the desire that an applied park brake remain applied and limit the ability of the vehicle to be moved.
00 - Park Brake Release Inhibit not requested
01 - Park Brake Release Inhibit requested
10 - SAE ...";
CM_ SG_ 2566844926 CruiseCtrlPauseSwitch "Switch signal which indicates the position of the Cruise Control Pause Switch used on Remote Cruise Control applications. The Cruise Control Pause Switch signal temporarily disables the Cruise Control function.
00 - Off
01 - On
10 - Error ...";
CM_ SG_ 2566844926 ParkingBrakeSwitch "Switch signal which indicates when the parking brake is set. In general the switch actuated by the operator's park brake control, whether a pedal, lever or other control mechanism  (see also SPN 619 and 5275).
00 - Parking brake not set
01 - ...";
CM_ SG_ 2566844926 TwoSpeedAxleSwitch "Switch signal which indicates the current axle range.

00 - Low speed range
01 - High speed range
10 - Error
11 - Not available";
CM_ BO_ 2566843902 "Cruise Control/Vehicle Speed Setup";
CM_ SG_ 2566843902 MaxVehicleSpeedLimit6808 "Maximum vehicle velocity allowed. See SPN 74 for an alternate resolution.";
CM_ SG_ 2566843902 CruiseCtrlLowSetLimitSpeed "Minimum vehicle velocity at which cruise can be set or minimum vehicle velocity for cruise operation before it will exit cruise control operation.";
CM_ SG_ 2566843902 CruiseCtrlHighSetLimitSpeed "Maximum vehicle velocity at which cruise can be set.

If Cruise Control Adjusted Maximum Speed (SPN 7495) is supported, then SPN 7495 has priority over SPN 87. See the definition for SPN 7495 for more details.";
CM_ SG_ 2566843902 MaxVehicleSpeedLimit "Maximum vehicle velocity allowed.   See SPN 6808 for an alternate resolution.";
CM_ BO_ 2566809598 "Climate Control Configuration";
CM_ SG_ 2566809598 AuxHeaterMaxOutputPower "The maximum output power of the auxiliary heater.";
CM_ BO_ 2633940222 "Compression/Service Brake Information";
CM_ SG_ 2633940222 TripServiceBrakeApplications "Total number of times the service brakes have been activated since the last trip reset.  Brake applications of less than 0.5 s are not counted and lengthy brake applications (longer than 0.5 s) are counted as a single event.
NOTE - Definition and ...";
CM_ SG_ 2633940222 TripServiceBrakeDistance "Total distance over which the service brakes have been active since the last trip reset.";
CM_ SG_ 2633940222 TripCompressionBrakeDistance "Total distance over which the compression brakes have been active since the last trip reset.";
CM_ SG_ 2633940222 TotalCompressionBrakeDistance "Total distance over which the compression brakes have been active for the life of the engine.";
CM_ BO_ 2566775294 "Cab A/C Climate System Information
This message contains measurement and condition information from cab air conditioning components.";
CM_ SG_ 2566775294 CbA_CRfrgrntCmpressorOutletPress "This is the gage pressure at the compressor outlet in the cab air conditioning system.";
CM_ BO_ 2566803710 "Battery Temperature
Contains battery temperature information.";
CM_ SG_ 2566803710 SLIBattery4Temp "Temperature of the battery 4 used for starting the engine, for lighting, and for ignition (SLI). 

The relation to physical location is determined by the equipment manufacturer.";
CM_ SG_ 2566803710 SLIBattery3Temp "Temperature of the battery 3 used for starting the engine, for lighting, and for ignition (SLI). 

The relation to physical location is determined by the equipment manufacturer.";
CM_ SG_ 2566803710 Battery2Temp "Temperature of the battery 2 used for starting the engine, for lighting, and for ignition (SLI). 

The relation to physical location is determined by the equipment manufacturer.";
CM_ SG_ 2566803710 Battery1Temp "Temperature of the battery 1 used for starting the engine, for lighting, and for ignition (SLI). 

The relation to physical location is determined by the equipment manufacturer.";
CM_ BO_ 2566719486 "Direct Lamp Control Command 1
Message that directly controls the driver indicator lamps.  See also PGN 64774 for additional lamps and PGN 64773 for the feedback information about these lamps.
Note: Since this message is direct lamp control, it is ...";
CM_ SG_ 2566719486 VhclAccelerationRateLimitLampCmd "Command signal directly controlling the Vehicle Acceleration Rate Limit Lamp.
00 - Lamp Off
01 - Lamp On
10 - Reserved
11 - Not available
NOTE: SPN 2979 is the original parameter used to provide vehicle acceleration rate limit status.  This ...";
CM_ SG_ 2566719486 EngSpeedVeryHighLampCmd "Command signal directly controlling the Engine Speed Very High Warning lamp.

00 - Lamp Off
01 - Lamp On
10 - Reserved
11 - Not available";
CM_ SG_ 2566719486 EngSpeedHighLampCmd "Command signal directly controlling the Engine Speed High Warning lamp.

00 - Lamp Off
01 - Lamp On
10 - Reserved
11 - Not available";
CM_ SG_ 2566719486 EngCtrlModule3ReadyForUseLampCmd "Command signal directly controlling the Engine Control Module 3 Ready for Use Lamp. This lamp is used to indicate whether ECM 3 can control the operation of the engine. In case of a failure in ECM 3, lamp will be turned OFF.
00 - Lamp Off
01 - ...";
CM_ SG_ 2566719486 EngCtrlModule2ReadyForUseLampCmd "Command signal directly controlling the Engine Control Module 2 Ready for Use Lamp. This lamp is used to indicate whether ECM 2 can control the operation of the engine. In case of a failure in ECM 2, lamp will be turned OFF.
00 - Lamp Off
01 - ...";
CM_ SG_ 2566719486 EngCtrlModule1ReadyForUseLampCmd "Command signal directly controlling the Engine Control Module 1 Ready for use Lamp. This lamp is used to indicate whether ECM 1 can control the operation of the engine. In case of a failure in ECM 1, lamp will be turned OFF.
00 - Lamp Off
01 - ...";
CM_ SG_ 2566719486 EngFuelFilterRestrictedLampCmd "Command signal directly controlling the Engine Fuel Filter Restricted Lamp.

00 - Lamp Off
01 - Lamp On
10 - Reserved
11 - Not available";
CM_ SG_ 2566719486 EngAirFilterRestrictionLampCmd "Command signal directly controlling the Engine Air Filter Restriction Lamp.

00 - Lamp Off
01 - Lamp On
10 - Reserved
11 - Not available";
CM_ SG_ 2566719486 EngIdleManagementActiveLampCmd "Command signal directly controlling the Engine Idle Management Active Lamp

00 - Lamp Off
01 - Lamp On
10 - Reserved
11 - Not available

Note:  SPN 1661 should be used for reporting diagnostics of the Engine Idle Management Active Lamp.";
CM_ SG_ 2566719486 EngCoolantLevelLowLampCmd "Command signal directly controlling the Engine Coolant Level Low Lamp

00 - Lamp Off
01 - Lamp On
10 - Reserved
11 - Not available";
CM_ SG_ 2566719486 EngCoolantTempHighLampCmd "Command signal directly controlling the Engine Coolant Temperature High Lamp

00 - Lamp Off
01 - Lamp On
10 - Reserved
11 - Not available";
CM_ SG_ 2566719486 EngOilPressLowLampCmd "Command signal directly controlling the Engine Oil Pressure Low Lamp

00 - Lamp Off
01 - Lamp On
10 - Reserved
11 - Not available";
CM_ SG_ 2566719486 CmprssnBrkEnblSwtchIndctrLampCmd "Command signal directly controlling Compression Brake Enable Switch Indicator Lamp.  The compression brake switch indicator signals the status of the compression brake enable switch to the operator.
00 - Lamp OFF
01 - Lamp ON
10 - Reserved
11 - ...";
CM_ SG_ 2566719486 EngBrakeActiveLampCmd "Command signal directly controlling the Engine Brake Active Lamp. This is used for engine based retarders.

00 - Lamp Off
01 - Lamp On
10 - Reserved
11 - Not available";
CM_ SG_ 2566719486 OBDMalfunctionIndicatorLampCmd "Command signal directly controlling the OBD Malfunction Indicator Lamp

00 - Lamp Off
01 - Lamp On
10 - Reserved
11 - Not available

Note:  SPN 1213 should be used for reporting diagnostics of the OBD Malfunction Indicator Lamp.";
CM_ SG_ 2566719486 EngRedStopLampCmd "Command signal directly controlling the Engine Red Stop Lamp

00 - Lamp Off
01 - Lamp On
10 - Reserved
11 - Not available

Note:  SPN 623 should be used for reporting diagnostics of the Engine Red Stop Lamp.";
CM_ SG_ 2566719486 EngAmberWarningLampCmd "Command signal directly controlling the Engine Amber Warning Lamp

00 - Lamp Off
01 - Lamp On
10 - Reserved
11 - Not available

Note:  SPN 624 should be used for reporting diagnostics of the Engine Amber Warning Lamp.";
CM_ SG_ 2566719486 EngProtectLampCmd "Command signal directly controlling the Engine Protect Lamp

00 - Lamp Off
01 - Lamp On
10 - Reserved
11 - Not available

Note:  SPN 987 should be used for reporting diagnostics of the Engine Protect Lamp.";
CM_ BO_ 2163223550 "Crash Notification
This message is transmitted in case of a crash event.
The message contains information about the Crash Type, a Crash Counter and a Checksum. The function of the Crash Counter is to prevent other ECU's from reacting to a faulty ...";
CM_ SG_ 2163223550 CrashChecksum "The Crash Checksum is used to verify the signal path from the airbag ECU to other devices in case of a crash.
The 4 bit checksum is the sum of the high nibble and the low nibble of the sum of the identifier, the first 7 data bytes and the 4 bit ...";
CM_ SG_ 2163223550 CrashCounter "The Crash Counter prevents other ECUs from reacting to a faulty transmission of the Crash Notification PGN and serves as a safety mechanism. The Crash Counter becomes incremented by 1 for every sent message, starting with \"0\". (0 follows 15)";
CM_ SG_ 2163223550 CrashType "Type of crash event. 

00001 = frontal crash
00010 = rear crash
00100 = side crash (left)
01000 = side crash (right)
10000 = rollover

It is possible to combine different Crash Types. (e.g. frontal and side crash (left) = 00101)";
CM_ BO_ 2566714878 "Charge Air Cooler 2 Precooler
Engine bank 2 CAC precooler parameters";
CM_ SG_ 2566714878 EngChrgArClr2PrecoolerEfficiency "Engine charge air cooler 2 (CAC2) precooler efficiency is an indication of the precooler’s ability to reduce the temperature of the gas that is being routed through the precooler. 0% = no reduction in temperature, 100% = maximum cooling. The CAC2 ...";
CM_ SG_ 2566714878 EngChrgArClr2PrecoolerOutletTemp "Temperature of the combustion air measured at the charge air cooler 2 precooler outlet.";
CM_ SG_ 2566714878 EngChrgArClr2PrecoolerIntakeTemp "Temperature of the combustion air measured at the charge air cooler 2 precooler Intake.";
CM_ BO_ 2566714622 "Charge Air Cooler 2
Engine bank 2 Charge Air Cooler parameters";
CM_ SG_ 2566714622 EngChargeAirCooler2Efficiency "Engine charge air cooler 2 (CAC2) is an indication of the CAC’s ability to reduce the temperature of the combustion air that is being routed through the CAC. 0% = no reduction in temperature, 100% = maximum cooling. The CAC2 efficiency is calculated ...";
CM_ SG_ 2566714622 EngChrgeAirCooler2AmbientAirTemp "Temperature of the air surrounding charge air cooler 2.";
CM_ SG_ 2566714622 EngChargeAirCooler2OutletTemp "Temperature of combustion air after it exits from the Charge Air Cooler 2 but before any mixing of recirculated exhaust gas.";
CM_ SG_ 2566714622 EngChargeAirCooler2IntakeTemp "Temperature of the combustion air measured at the charge air cooler 2 Intake.";
CM_ BO_ 2566715390 "Charge Air Cooler 1 Precooler
Engine bank 1 CAC precooler parameters";
CM_ SG_ 2566715390 EngChrgArClr1PrecoolerEfficiency "Engine charge air cooler 1 (CAC1) precooler efficiency is an indication of the precooler’s ability to reduce the temperature of the combustion air that is being routed through the precooler. 0% = no reduction in temperature, 100% = maximum cooling ...";
CM_ SG_ 2566715390 EngChrgArClr1PrecoolerOutletTemp "Temperature of the combustion air measured at the charge air cooler 1 precooler outlet.";
CM_ SG_ 2566715390 EngChrgArClr1PrecoolerIntakeTemp "Temperature of the combustion air measured at the charge air cooler 1 precooler intake.";
CM_ BO_ 2566715134 "Charge Air Cooler 1
Engine bank 1 Charge Air Cooler parameters";
CM_ SG_ 2566715134 EngChargeAirCooler1Efficiency "Engine charge air cooler 1(CAC1) efficiency is an indication of the CAC’s ability to reduce the temperature of the combustion air that is being routed through the CAC1. 0% = no reduction in temperature, 100% = maximum cooling. The CAC1 efficiency is ...";
CM_ SG_ 2566715134 EngChrgeAirCooler1AmbientAirTemp "Temperature of the air surrounding charge air cooler 1.";
CM_ SG_ 2566715134 EngChargeAirCooler1IntakeTemp "Temperature of the combustion air measured at the CAC 1 Intake.";
CM_ BO_ 2365400830 "Basic Joystick Message 9
Used to transfer information about the measured status of the 1st 2 axes and up to 12 buttons of a joystick.  Additional handle information is available in the Expanded Joystick Message.
10-bit position parameters are ...";
CM_ SG_ 2365400830 Joystick9Button9PressedStatus "Reports when the joystick button has been pressed.

00 Button not pressed
01 Button pressed
10 Error Indicator
11 Not Available";
CM_ SG_ 2365400830 Joystick9Button10PressedStatus "Reports when the joystick button has been pressed.

00 Button not pressed
01 Button pressed
10 Error Indicator
11 Not Available";
CM_ SG_ 2365400830 Joystick9Button11PressedStatus "Reports when the joystick button has been pressed.

00 Button not pressed
01 Button pressed
10 Error Indicator
11 Not Available";
CM_ SG_ 2365400830 Joystick9Button12PressedStatus "Reports when the joystick button has been pressed.

00 Button not pressed
01 Button pressed
10 Error Indicator
11 Not Available";
CM_ SG_ 2365400830 Joystick9Button5PressedStatus "Reports when the joystick button has been pressed.

00 Button not pressed
01 Button pressed
10 Error Indicator
11 Not Available";
CM_ SG_ 2365400830 Joystick9Button6PressedStatus "Reports when the joystick button has been pressed.

00 Button not pressed
01 Button pressed
10 Error Indicator
11 Not Available";
CM_ SG_ 2365400830 Joystick9Button7PressedStatus "Reports when the joystick button has been pressed.

00 Button not pressed
01 Button pressed
10 Error Indicator
11 Not Available";
CM_ SG_ 2365400830 Joystick9Button8PressedStatus "Reports when the joystick button has been pressed.

00 Button not pressed
01 Button pressed
10 Error Indicator
11 Not Available";
CM_ SG_ 2365400830 Joystick9Button1PressedStatus "Reports when the joystick button has been pressed.

00 Button not pressed
01 Button pressed
10 Error Indicator
11 Not Available";
CM_ SG_ 2365400830 Joystick9Button2PressedStatus "Reports when the joystick button has been pressed.

00 Button not pressed
01 Button pressed
10 Error Indicator
11 Not Available";
CM_ SG_ 2365400830 Joystick9Button3PressedStatus "Reports when the joystick button has been pressed.

00 Button not pressed
01 Button pressed
10 Error Indicator
11 Not Available";
CM_ SG_ 2365400830 Joystick9Button4PressedStatus "Reports when the joystick button has been pressed.

00 Button not pressed
01 Button pressed
10 Error Indicator
11 Not Available";
CM_ SG_ 2365400830 Joystick9XAxisDetentPosStatus "Reports when the current joystick position is in the detent position for that axis of travel.

00 Not in the Detent Position
01 In the Detent Position
10 Error Indicator
11 Not Available";
CM_ SG_ 2365400830 Joystick9YAxisDetentPosStatus "Reports when the current joystick position is in the detent position for that axis of travel.

00 Not in the Detent Position
01 In the Detent Position
10 Error Indicator
11 Not Available";
CM_ SG_ 2365400830 Joystick9YAxisPos "The position of the joystick in the relative motion of travel from the neutral position.  Position value of 0 is Neutral and position value 1000 (100%) is the end of linear zone.  Value of 1022 indicates an error has occurred.";
CM_ SG_ 2365400830 Jystck9YAxsLvrFrwrdPstvPosStatus "Reports when the current joystick position is on the positive travel side (forward, right, clockwise, up) relative to the neutral position for that axis of travel.
00 Not on Positive side of Neutral
01 On positive side of Neutral
10 Error ...";
CM_ SG_ 2365400830 Jystck9YAxsLvrBckNgtivePosStatus "Reports when the current joystick position is on the negative travel side (back, left, counterclockwise, down) relative to the neutral position for that axis of travel.
00 Not on negative side of Neutral
01 On negative side of Neutral
10 Error ...";
CM_ SG_ 2365400830 Joystick9YAxisNeutralPosStatus "Reports when the current joystick position is in the neutral position for that axis of travel.  The neutral position measurement must be determined from some mechanism other than the axis position measurement device.
00 Not in Neutral Position
01 ...";
CM_ SG_ 2365400830 Joystick9XAxisPos "The position of the joystick in the relative motion of travel from the neutral position.  Position value of 0 is Neutral and position value 1000 (100%) is the end of linear zone.  Value of 1022 indicates an error has occurred.";
CM_ SG_ 2365400830 Jystck9XAxsLvrRghtPstvePosStatus "Reports when the current joystick position is on the positive travel side (forward, right, clockwise, up) relative to the neutral position for that axis of travel.
00 Not on Positive side of Neutral
01 On positive side of Neutral
10 Error ...";
CM_ SG_ 2365400830 Jystck9XAxsLvrLftNgtivePosStatus "Reports when the current joystick position is on the negative travel side (back, left, counterclockwise, down) relative to the neutral position for that axis of travel.
00 Not on negative side of Neutral
01 On negative side of Neutral
10 Error ...";
CM_ SG_ 2365400830 Joystick9XAxisNeutralPosStatus "Reports when the current joystick position is in the neutral position for that axis of travel.  The neutral position measurement must be determined from some mechanism other than the axis position measurement device.
00 Not in Neutral Position
01 ...";
CM_ BO_ 2365401342 "Basic Joystick Message 8
Used to transfer information about the measured status of the 1st 2 axes and up to 12 buttons of a joystick.  Additional handle information is available in the Expanded Joystick Message.
10-bit position parameters are ...";
CM_ SG_ 2365401342 Joystick8Button9PressedStatus "Reports when the joystick button has been pressed.

00 Button not pressed
01 Button pressed
10 Error Indicator
11 Not Available";
CM_ SG_ 2365401342 Joystick8Button10PressedStatus "Reports when the joystick button has been pressed.

00 Button not pressed
01 Button pressed
10 Error Indicator
11 Not Available";
CM_ SG_ 2365401342 Joystick8Button11PressedStatus "Reports when the joystick button has been pressed.

00 Button not pressed
01 Button pressed
10 Error Indicator
11 Not Available";
CM_ SG_ 2365401342 Joystick8Button12PressedStatus "Reports when the joystick button has been pressed.

00 Button not pressed
01 Button pressed
10 Error Indicator
11 Not Available";
CM_ SG_ 2365401342 Joystick8Button5PressedStatus "Reports when the joystick button has been pressed.

00 Button not pressed
01 Button pressed
10 Error Indicator
11 Not Available";
CM_ SG_ 2365401342 Joystick8Button6PressedStatus "Reports when the joystick button has been pressed.

00 Button not pressed
01 Button pressed
10 Error Indicator
11 Not Available";
CM_ SG_ 2365401342 Joystick8Button7PressedStatus "Reports when the joystick button has been pressed.

00 Button not pressed
01 Button pressed
10 Error Indicator
11 Not Available";
CM_ SG_ 2365401342 Joystick8Button8PressedStatus "Reports when the joystick button has been pressed.

00 Button not pressed
01 Button pressed
10 Error Indicator
11 Not Available";
CM_ SG_ 2365401342 Joystick8Button1PressedStatus "Reports when the joystick button has been pressed.

00 Button not pressed
01 Button pressed
10 Error Indicator
11 Not Available";
CM_ SG_ 2365401342 Joystick8Button2PressedStatus "Reports when the joystick button has been pressed.

00 Button not pressed
01 Button pressed
10 Error Indicator
11 Not Available";
CM_ SG_ 2365401342 Joystick8Button3PressedStatus "Reports when the joystick button has been pressed.

00 Button not pressed
01 Button pressed
10 Error Indicator
11 Not Available";
CM_ SG_ 2365401342 Joystick8Button4PressedStatus "Reports when the joystick button has been pressed.

00 Button not pressed
01 Button pressed
10 Error Indicator
11 Not Available";
CM_ SG_ 2365401342 Joystick8XAxisDetentPosStatus "Reports when the current joystick position is in the detent position for that axis of travel.

00 Not in the Detent Position
01 In the Detent Position
10 Error Indicator
11 Not Available";
CM_ SG_ 2365401342 Joystick8YAxisDetentPosStatus "Reports when the current joystick position is in the detent position for that axis of travel.

00 Not in the Detent Position
01 In the Detent Position
10 Error Indicator
11 Not Available";
CM_ SG_ 2365401342 Joystick8YAxisPos "The position of the joystick in the relative motion of travel from the neutral position.  Position value of 0 is Neutral and position value 1000 (100%) is the end of linear zone.  Value of 1022 indicates an error has occurred.";
CM_ SG_ 2365401342 Jystck8YAxsLvrFrwrdPstvPosStatus "Reports when the current joystick position is on the positive travel side (forward, right, clockwise, up) relative to the neutral position for that axis of travel.
00 Not on Positive side of Neutral
01 On positive side of Neutral
10 Error ...";
CM_ SG_ 2365401342 Jystck8YAxsLvrBckNgtivePosStatus "Reports when the current joystick position is on the negative travel side (back, left, counterclockwise, down) relative to the neutral position for that axis of travel.
00 Not on negative side of Neutral
01 On negative side of Neutral
10 Error ...";
CM_ SG_ 2365401342 Joystick8YAxisNeutralPosStatus "Reports when the current joystick position is in the neutral position for that axis of travel.  The neutral position measurement must be determined from some mechanism other than the axis position measurement device.
00 Not in Neutral Position
01 ...";
CM_ SG_ 2365401342 Joystick8XAxisPos "The position of the joystick in the relative motion of travel from the neutral position.  Position value of 0 is Neutral and position value 1000 (100%) is the end of linear zone.  Value of 1022 indicates an error has occurred.";
CM_ SG_ 2365401342 Jystck8XAxsLvrRghtPstvePosStatus "Reports when the current joystick position is on the positive travel side (forward, right, clockwise, up) relative to the neutral position for that axis of travel.
00 Not on Positive side of Neutral
01 On positive side of Neutral
10 Error ...";
CM_ SG_ 2365401342 Jystck8XAxsLvrLftNgtivePosStatus "Reports when the current joystick position is on the negative travel side (back, left, counterclockwise, down) relative to the neutral position for that axis of travel.
00 Not on negative side of Neutral
01 On negative side of Neutral
10 Error ...";
CM_ SG_ 2365401342 Joystick8XAxisNeutralPosStatus "Reports when the current joystick position is in the neutral position for that axis of travel.  The neutral position measurement must be determined from some mechanism other than the axis position measurement device.
00 Not in Neutral Position
01 ...";
CM_ BO_ 2365401854 "Basic Joystick Message 7
Used to transfer information about the measured status of the 1st 2 axes and up to 12 buttons of a joystick.  Additional handle information is available in the Expanded Joystick Message.
10-bit position parameters are ...";
CM_ SG_ 2365401854 Joystick7Button9PressedStatus "Reports when the joystick button has been pressed.

00 Button not pressed
01 Button pressed
10 Error Indicator
11 Not Available";
CM_ SG_ 2365401854 Joystick7Button10PressedStatus "Reports when the joystick button has been pressed.

00 Button not pressed
01 Button pressed
10 Error Indicator
11 Not Available";
CM_ SG_ 2365401854 Joystick7Button11PressedStatus "Reports when the joystick button has been pressed.

00 Button not pressed
01 Button pressed
10 Error Indicator
11 Not Available";
CM_ SG_ 2365401854 Joystick7Button12PressedStatus "Reports when the joystick button has been pressed.

00 Button not pressed
01 Button pressed
10 Error Indicator
11 Not Available";
CM_ SG_ 2365401854 Joystick7Button5PressedStatus "Reports when the joystick button has been pressed.

00 Button not pressed
01 Button pressed
10 Error Indicator
11 Not Available";
CM_ SG_ 2365401854 Joystick7Button6PressedStatus "Reports when the joystick button has been pressed.

00 Button not pressed
01 Button pressed
10 Error Indicator
11 Not Available";
CM_ SG_ 2365401854 Joystick7Button7PressedStatus "Reports when the joystick button has been pressed.

00 Button not pressed
01 Button pressed
10 Error Indicator
11 Not Available";
CM_ SG_ 2365401854 Joystick7Button8PressedStatus "Reports when the joystick button has been pressed.

00 Button not pressed
01 Button pressed
10 Error Indicator
11 Not Available";
CM_ SG_ 2365401854 Joystick7Button1PressedStatus "Reports when the joystick button has been pressed.

00 Button not pressed
01 Button pressed
10 Error Indicator
11 Not Available";
CM_ SG_ 2365401854 Joystick7Button2PressedStatus "Reports when the joystick button has been pressed.

00 Button not pressed
01 Button pressed
10 Error Indicator
11 Not Available";
CM_ SG_ 2365401854 Joystick7Button3PressedStatus "Reports when the joystick button has been pressed.

00 Button not pressed
01 Button pressed
10 Error Indicator
11 Not Available";
CM_ SG_ 2365401854 Joystick7Button4PressedStatus "Reports when the joystick button has been pressed.

00 Button not pressed
01 Button pressed
10 Error Indicator
11 Not Available";
CM_ SG_ 2365401854 Joystick7XAxisDetentPosStatus "Reports when the current joystick position is in the detent position for that axis of travel.

00 Not in the Detent Position
01 In the Detent Position
10 Error Indicator
11 Not Available";
CM_ SG_ 2365401854 Joystick7YAxisDetentPosStatus "Reports when the current joystick position is in the detent position for that axis of travel.

00 Not in the Detent Position
01 In the Detent Position
10 Error Indicator
11 Not Available";
CM_ SG_ 2365401854 Joystick7YAxisPos "The position of the joystick in the relative motion of travel from the neutral position.  Position value of 0 is Neutral and position value 1000 (100%) is the end of linear zone.  Value of 1022 indicates an error has occurred.";
CM_ SG_ 2365401854 Jystck7YAxsLvrFrwrdPstvPosStatus "Reports when the current joystick position is on the positive travel side (forward, right, clockwise, up) relative to the neutral position for that axis of travel.
00 Not on Positive side of Neutral
01 On positive side of Neutral
10 Error ...";
CM_ SG_ 2365401854 Jystck7YAxsLvrBckNgtivePosStatus "Reports when the current joystick position is on the negative travel side (back, left, counterclockwise, down) relative to the neutral position for that axis of travel.
00 Not on negative side of Neutral
01 On negative side of Neutral
10 Error ...";
CM_ SG_ 2365401854 Joystick7YAxisNeutralPosStatus "Reports when the current joystick position is in the neutral position for that axis of travel.  The neutral position measurement must be determined from some mechanism other than the axis position measurement device.
00 Not in Neutral Position
01 ...";
CM_ SG_ 2365401854 Joystick7XAxisPos "The position of the joystick in the relative motion of travel from the neutral position.  Position value of 0 is Neutral and position value 1000 (100%) is the end of linear zone.  Value of 1022 indicates an error has occurred.";
CM_ SG_ 2365401854 Jystck7XAxsLvrRghtPstvePosStatus "Reports when the current joystick position is on the positive travel side (forward, right, clockwise, up) relative to the neutral position for that axis of travel.
00 Not on Positive side of Neutral
01 On positive side of Neutral
10 Error ...";
CM_ SG_ 2365401854 Jystck7XAxsLvrLftNgtivePosStatus "Reports when the current joystick position is on the negative travel side (back, left, counterclockwise, down) relative to the neutral position for that axis of travel.
00 Not on negative side of Neutral
01 On negative side of Neutral
10 Error ...";
CM_ SG_ 2365401854 Joystick7XAxisNeutralPosStatus "Reports when the current joystick position is in the neutral position for that axis of travel.  The neutral position measurement must be determined from some mechanism other than the axis position measurement device.
00 Not in Neutral Position
01 ...";
CM_ BO_ 2365402366 "Basic Joystick Message 6
Used to transfer information about the measured status of the 1st 2 axes and up to 12 buttons of a joystick.  Additional handle information is available in the Expanded Joystick Message.
10-bit position parameters are ...";
CM_ SG_ 2365402366 Joystick6Button9PressedStatus "Reports when the joystick button has been pressed.

00 Button not pressed
01 Button pressed
10 Error Indicator
11 Not Available";
CM_ SG_ 2365402366 Joystick6Button10PressedStatus "Reports when the joystick button has been pressed.

00 Button not pressed
01 Button pressed
10 Error Indicator
11 Not Available";
CM_ SG_ 2365402366 Joystick6Button11PressedStatus "Reports when the joystick button has been pressed.

00 Button not pressed
01 Button pressed
10 Error Indicator
11 Not Available";
CM_ SG_ 2365402366 Joystick6Button12PressedStatus "Reports when the joystick button has been pressed.

00 Button not pressed
01 Button pressed
10 Error Indicator
11 Not Available";
CM_ SG_ 2365402366 Joystick6Button5PressedStatus "Reports when the joystick button has been pressed.

00 Button not pressed
01 Button pressed
10 Error Indicator
11 Not Available";
CM_ SG_ 2365402366 Joystick6Button6PressedStatus "Reports when the joystick button has been pressed.

00 Button not pressed
01 Button pressed
10 Error Indicator
11 Not Available";
CM_ SG_ 2365402366 Joystick6Button7PressedStatus "Reports when the joystick button has been pressed.

00 Button not pressed
01 Button pressed
10 Error Indicator
11 Not Available";
CM_ SG_ 2365402366 Joystick6Button8PressedStatus "Reports when the joystick button has been pressed.

00 Button not pressed
01 Button pressed
10 Error Indicator
11 Not Available";
CM_ SG_ 2365402366 Joystick6Button1PressedStatus "Reports when the joystick button has been pressed.

00 Button not pressed
01 Button pressed
10 Error Indicator
11 Not Available";
CM_ SG_ 2365402366 Joystick6Button2PressedStatus "Reports when the joystick button has been pressed.

00 Button not pressed
01 Button pressed
10 Error Indicator
11 Not Available";
CM_ SG_ 2365402366 Joystick6Button3PressedStatus "Reports when the joystick button has been pressed.

00 Button not pressed
01 Button pressed
10 Error Indicator
11 Not Available";
CM_ SG_ 2365402366 Joystick6Button4PressedStatus "Reports when the joystick button has been pressed.

00 Button not pressed
01 Button pressed
10 Error Indicator
11 Not Available";
CM_ SG_ 2365402366 Joystick6XAxisDetentPosStatus "Reports when the current joystick position is in the detent position for that axis of travel.

00 Not in the Detent Position
01 In the Detent Position
10 Error Indicator
11 Not Available";
CM_ SG_ 2365402366 Joystick6YAxisDetentPosStatus "Reports when the current joystick position is in the detent position for that axis of travel.

00 Not in the Detent Position
01 In the Detent Position
10 Error Indicator
11 Not Available";
CM_ SG_ 2365402366 Joystick6YAxisPos "The position of the joystick in the relative motion of travel from the neutral position.  Position value of 0 is Neutral and position value 1000 (100%) is the end of linear zone.  Value of 1022 indicates an error has occurred.";
CM_ SG_ 2365402366 Jystck6YAxsLvrFrwrdPstvPosStatus "Reports when the current joystick position is on the positive travel side (forward, right, clockwise, up) relative to the neutral position for that axis of travel.
00 Not on Positive side of Neutral
01 On positive side of Neutral
10 Error ...";
CM_ SG_ 2365402366 Jystck6YAxsLvrBckNgtivePosStatus "Reports when the current joystick position is on the negative travel side (back, left, counterclockwise, down) relative to the neutral position for that axis of travel.
00 Not on negative side of Neutral
01 On negative side of Neutral
10 Error ...";
CM_ SG_ 2365402366 Joystick6YAxisNeutralPosStatus "Reports when the current joystick position is in the neutral position for that axis of travel.  The neutral position measurement must be determined from some mechanism other than the axis position measurement device.
00 Not in Neutral Position
01 ...";
CM_ SG_ 2365402366 Joystick6XAxisPos "The position of the joystick in the relative motion of travel from the neutral position.  Position value of 0 is Neutral and position value 1000 (100%) is the end of linear zone.  Value of 1022 indicates an error has occurred.";
CM_ SG_ 2365402366 Jystck6XAxsLvrRghtPstvePosStatus "Reports when the current joystick position is on the positive travel side (forward, right, clockwise, up) relative to the neutral position for that axis of travel.
00 Not on Positive side of Neutral
01 On positive side of Neutral
10 Error ...";
CM_ SG_ 2365402366 Jystck6XAxsLvrLftNgtivePosStatus "Reports when the current joystick position is on the negative travel side (back, left, counterclockwise, down) relative to the neutral position for that axis of travel.
00 Not on negative side of Neutral
01 On negative side of Neutral
10 Error ...";
CM_ SG_ 2365402366 Joystick6XAxisNeutralPosStatus "Reports when the current joystick position is in the neutral position for that axis of travel.  The neutral position measurement must be determined from some mechanism other than the axis position measurement device.
00 Not in Neutral Position
01 ...";
CM_ BO_ 2365402878 "Basic Joystick Message 5
Used to transfer information about the measured status of the 1st 2 axes and up to 12 buttons of a joystick.  Additional handle information is available in the Expanded Joystick Message.
10-bit position parameters are ...";
CM_ SG_ 2365402878 Joystick5Button9PressedStatus "Reports when the joystick button has been pressed.

00 Button not pressed
01 Button pressed
10 Error Indicator
11 Not Available";
CM_ SG_ 2365402878 Joystick5Button10PressedStatus "Reports when the joystick button has been pressed.

00 Button not pressed
01 Button pressed
10 Error Indicator
11 Not Available";
CM_ SG_ 2365402878 Joystick5Button11PressedStatus "Reports when the joystick button has been pressed.

00 Button not pressed
01 Button pressed
10 Error Indicator
11 Not Available";
CM_ SG_ 2365402878 Joystick5Button12PressedStatus "Reports when the joystick button has been pressed.

00 Button not pressed
01 Button pressed
10 Error Indicator
11 Not Available";
CM_ SG_ 2365402878 Joystick5Button5PressedStatus "Reports when the joystick button has been pressed.

00 Button not pressed
01 Button pressed
10 Error Indicator
11 Not Available";
CM_ SG_ 2365402878 Joystick5Button6PressedStatus "Reports when the joystick button has been pressed.

00 Button not pressed
01 Button pressed
10 Error Indicator
11 Not Available";
CM_ SG_ 2365402878 Joystick5Button7PressedStatus "Reports when the joystick button has been pressed.

00 Button not pressed
01 Button pressed
10 Error Indicator
11 Not Available";
CM_ SG_ 2365402878 Joystick5Button8PressedStatus "Reports when the joystick button has been pressed.

00 Button not pressed
01 Button pressed
10 Error Indicator
11 Not Available";
CM_ SG_ 2365402878 Joystick5Button1PressedStatus "Reports when the joystick button has been pressed.

00 Button not pressed
01 Button pressed
10 Error Indicator
11 Not Available";
CM_ SG_ 2365402878 Joystick5Button2PressedStatus "Reports when the joystick button has been pressed.

00 Button not pressed
01 Button pressed
10 Error Indicator
11 Not Available";
CM_ SG_ 2365402878 Joystick5Button3PressedStatus "Reports when the joystick button has been pressed.

00 Button not pressed
01 Button pressed
10 Error Indicator
11 Not Available";
CM_ SG_ 2365402878 Joystick5Button4PressedStatus "Reports when the joystick button has been pressed.

00 Button not pressed
01 Button pressed
10 Error Indicator
11 Not Available";
CM_ SG_ 2365402878 Joystick5XAxisDetentPosStatus "Reports when the current joystick position is in the detent position for that axis of travel.

00 Not in the Detent Position
01 In the Detent Position
10 Error Indicator
11 Not Available";
CM_ SG_ 2365402878 Joystick5YAxisDetentPosStatus "Reports when the current joystick position is in the detent position for that axis of travel.

00 Not in the Detent Position
01 In the Detent Position
10 Error Indicator
11 Not Available";
CM_ SG_ 2365402878 Joystick5YAxisPos "The position of the joystick in the relative motion of travel from the neutral position.  Position value of 0 is Neutral and position value 1000 (100%) is the end of linear zone.  Value of 1022 indicates an error has occurred.";
CM_ SG_ 2365402878 Jystck5YAxsLvrFrwrdPstvPosStatus "Reports when the current joystick position is on the positive travel side (forward, right, clockwise, up) relative to the neutral position for that axis of travel.
00 Not on Positive side of Neutral
01 On positive side of Neutral
10 Error ...";
CM_ SG_ 2365402878 Jystck5YAxsLvrBckNgtivePosStatus "Reports when the current joystick position is on the negative travel side (back, left, counterclockwise, down) relative to the neutral position for that axis of travel.
00 Not on negative side of Neutral
01 On negative side of Neutral
10 Error ...";
CM_ SG_ 2365402878 Joystick5YAxisNeutralPosStatus "Reports when the current joystick position is in the neutral position for that axis of travel.  The neutral position measurement must be determined from some mechanism other than the axis position measurement device.
00 Not in Neutral Position
01 ...";
CM_ SG_ 2365402878 Joystick5XAxisPos "The position of the joystick in the relative motion of travel from the neutral position.  Position value of 0 is Neutral and position value 1000 (100%) is the end of linear zone.  Value of 1022 indicates an error has occurred.";
CM_ SG_ 2365402878 Jystck5XAxsLvrRghtPstvePosStatus "Reports when the current joystick position is on the positive travel side (forward, right, clockwise, up) relative to the neutral position for that axis of travel.
00 Not on Positive side of Neutral
01 On positive side of Neutral
10 Error ...";
CM_ SG_ 2365402878 Jystck5XAxsLvrLftNgtivePosStatus "Reports when the current joystick position is on the negative travel side (back, left, counterclockwise, down) relative to the neutral position for that axis of travel.
00 Not on negative side of Neutral
01 On negative side of Neutral
10 Error ...";
CM_ SG_ 2365402878 Joystick5XAxisNeutralPosStatus "Reports when the current joystick position is in the neutral position for that axis of travel.  The neutral position measurement must be determined from some mechanism other than the axis position measurement device.
00 Not in Neutral Position
01 ...";
CM_ BO_ 2365403390 "Basic Joystick Message 4
Used to transfer information about the measured status of the 1st 2 axes and up to 12 buttons of a joystick.  Additional handle information is available in the Expanded Joystick Message.
10-bit position parameters are ...";
CM_ SG_ 2365403390 Joystick4Button9PressedStatus "Reports when the joystick button has been pressed.

00 Button not pressed
01 Button pressed
10 Error Indicator
11 Not Available";
CM_ SG_ 2365403390 Joystick4Button10PressedStatus "Reports when the joystick button has been pressed.

00 Button not pressed
01 Button pressed
10 Error Indicator
11 Not Available";
CM_ SG_ 2365403390 Joystick4Button11PressedStatus "Reports when the joystick button has been pressed.

00 Button not pressed
01 Button pressed
10 Error Indicator
11 Not Available";
CM_ SG_ 2365403390 Joystick4Button12PressedStatus "Reports when the joystick button has been pressed.

00 Button not pressed
01 Button pressed
10 Error Indicator
11 Not Available";
CM_ SG_ 2365403390 Joystick4Button5PressedStatus "Reports when the joystick button has been pressed.

00 Button not pressed
01 Button pressed
10 Error Indicator
11 Not Available";
CM_ SG_ 2365403390 Joystick4Button6PressedStatus "Reports when the joystick button has been pressed.

00 Button not pressed
01 Button pressed
10 Error Indicator
11 Not Available";
CM_ SG_ 2365403390 Joystick4Button7PressedStatus "Reports when the joystick button has been pressed.

00 Button not pressed
01 Button pressed
10 Error Indicator
11 Not Available";
CM_ SG_ 2365403390 Joystick4Button8PressedStatus "Reports when the joystick button has been pressed.

00 Button not pressed
01 Button pressed
10 Error Indicator
11 Not Available";
CM_ SG_ 2365403390 Joystick4Button1PressedStatus "Reports when the joystick button has been pressed.

00 Button not pressed
01 Button pressed
10 Error Indicator
11 Not Available";
CM_ SG_ 2365403390 Joystick4Button2PressedStatus "Reports when the joystick button has been pressed.

00 Button not pressed
01 Button pressed
10 Error Indicator
11 Not Available";
CM_ SG_ 2365403390 Joystick4Button3PressedStatus "Reports when the joystick button has been pressed.

00 Button not pressed
01 Button pressed
10 Error Indicator
11 Not Available";
CM_ SG_ 2365403390 Joystick4Button4PressedStatus "Reports when the joystick button has been pressed.

00 Button not pressed
01 Button pressed
10 Error Indicator
11 Not Available";
CM_ SG_ 2365403390 Joystick4XAxisDetentPosStatus "Reports when the current joystick position is in the detent position for that axis of travel.

00 Not in the Detent Position
01 In the Detent Position
10 Error Indicator
11 Not Available";
CM_ SG_ 2365403390 Joystick4YAxisDetentPosStatus "Reports when the current joystick position is in the detent position for that axis of travel.

00 Not in the Detent Position
01 In the Detent Position
10 Error Indicator
11 Not Available";
CM_ SG_ 2365403390 Joystick4YAxisPos "The position of the joystick in the relative motion of travel from the neutral position.  Position value of 0 is Neutral and position value 1000 (100%) is the end of linear zone.  Value of 1022 indicates an error has occurred.";
CM_ SG_ 2365403390 Jystck4YAxsLvrFrwrdPstvPosStatus "Reports when the current joystick position is on the positive travel side (forward, right, clockwise, up) relative to the neutral position for that axis of travel.
00 Not on Positive side of Neutral
01 On positive side of Neutral
10 Error ...";
CM_ SG_ 2365403390 Jystck4YAxsLvrBckNgtivePosStatus "Reports when the current joystick position is on the negative travel side (back, left, counterclockwise, down) relative to the neutral position for that axis of travel.
00 Not on negative side of Neutral
01 On negative side of Neutral
10 Error ...";
CM_ SG_ 2365403390 Joystick4YAxisNeutralPosStatus "Reports when the current joystick position is in the neutral position for that axis of travel.  The neutral position measurement must be determined from some mechanism other than the axis position measurement device.
00 Not in Neutral Position
01 ...";
CM_ SG_ 2365403390 Joystick4XAxisPos "The position of the joystick in the relative motion of travel from the neutral position.  Position value of 0 is Neutral and position value 1000 (100%) is the end of linear zone.  Value of 1022 indicates an error has occurred.";
CM_ SG_ 2365403390 Jystck4XAxsLvrRghtPstvePosStatus "Reports when the current joystick position is on the positive travel side (forward, right, clockwise, up) relative to the neutral position for that axis of travel.
00 Not on Positive side of Neutral
01 On positive side of Neutral
10 Error ...";
CM_ SG_ 2365403390 Jystck4XAxsLvrLftNgtivePosStatus "Reports when the current joystick position is on the negative travel side (back, left, counterclockwise, down) relative to the neutral position for that axis of travel.
00 Not on negative side of Neutral
01 On negative side of Neutral
10 Error ...";
CM_ SG_ 2365403390 Joystick4XAxisNeutralPosStatus "Reports when the current joystick position is in the neutral position for that axis of travel.  The neutral position measurement must be determined from some mechanism other than the axis position measurement device.
00 Not in Neutral Position
01 ...";
BA_DEF_ SG_  "SigType" ENUM  "Default","Range","RangeSigned","ASCII","Discrete","Control","ReferencePGN","DTC","StringDelimiter","StringLength","StringLengthControl","MessageCounter","MessageChecksum";
BA_DEF_ SG_  "GenSigStartValue" INT 0 2147483647;
BA_DEF_ SG_  "GenSigSendType" ENUM  "Cyclic","OnWrite","OnWriteWithRepetition","OnChange","OnChangeWithRepetition","IfActive","IfActiveWithRepetition","NoSigSendType";
BA_DEF_ SG_  "GenSigILSupport" ENUM  "No","Yes";
BA_DEF_ SG_  "GenSigEVName" STRING ;
BA_DEF_ SG_  "SPN" INT 0 524287;
BA_DEF_ BO_  "TpJ1939VarDlc" ENUM  "No","Yes";
BA_DEF_ BO_  "GenMsgStartDelayTime" INT 0 100000;
BA_DEF_ BO_  "GenMsgILSupport" ENUM  "No","Yes";
BA_DEF_ BO_  "GenMsgDelayTime" INT 0 1000;
BA_DEF_ BO_  "GenMsgRequestable" INT 0 1;
BA_DEF_ BO_  "GenMsgSendType" ENUM  "cyclic","NotUsed","NotUsed","NotUsed","NotUsed","NotUsed","NotUsed","IfActive","noMsgSendType";
BA_DEF_ BO_  "VFrameFormat" ENUM  "StandardCAN","ExtendedCAN","reserved","J1939PG";
BA_DEF_ BO_  "GenMsgCycleTime" INT 0 3600000;
BA_DEF_ SG_  "SystemSignalLongSymbol" STRING ;
BA_DEF_DEF_  "SigType" "Default";
BA_DEF_DEF_  "GenSigStartValue" 0;
BA_DEF_DEF_  "GenSigSendType" "NoSigSendType";
BA_DEF_DEF_  "GenSigILSupport" "Yes";
BA_DEF_DEF_  "GenSigEVName" "Env@Nodename_@Signame";
BA_DEF_DEF_  "SPN" 0;
BA_DEF_DEF_  "TpJ1939VarDlc" "No";
BA_DEF_DEF_  "GenMsgStartDelayTime" 0;
BA_DEF_DEF_  "GenMsgILSupport" "Yes";
BA_DEF_DEF_  "GenMsgDelayTime" 0;
BA_DEF_DEF_  "GenMsgRequestable" 1;
BA_DEF_DEF_  "GenMsgSendType" "noMsgSendType";
BA_DEF_DEF_  "VFrameFormat" "J1939PG";
BA_DEF_DEF_  "GenMsgCycleTime" 0;
BA_DEF_DEF_  "SystemSignalLongSymbol" "";
BA_ "GenMsgSendType" BO_ 2566767870 0;
BA_ "GenMsgCycleTime" BO_ 2566767870 100;
BA_ "GenMsgSendType" BO_ 2566827518 0;
BA_ "GenMsgCycleTime" BO_ 2566827518 100;
BA_ "GenMsgSendType" BO_ 2566832126 0;
BA_ "GenMsgCycleTime" BO_ 2566832126 100;
BA_ "GenMsgSendType" BO_ 2565865982 0;
BA_ "GenMsgCycleTime" BO_ 2565865982 100;
BA_ "GenMsgSendType" BO_ 2565867262 0;
BA_ "GenMsgCycleTime" BO_ 2565867262 500;
BA_ "GenMsgSendType" BO_ 2566821118 0;
BA_ "GenMsgCycleTime" BO_ 2566821118 5000;
BA_ "TpJ1939VarDlc" BO_ 2566810622 1;
BA_ "GenMsgSendType" BO_ 2566847742 0;
BA_ "GenMsgCycleTime" BO_ 2566847742 1000;
BA_ "GenMsgSendType" BO_ 2563768062 0;
BA_ "GenMsgCycleTime" BO_ 2563768062 5000;
BA_ "GenMsgDelayTime" BO_ 2566771966 100;
BA_ "GenMsgSendType" BO_ 2566771966 0;
BA_ "GenMsgCycleTime" BO_ 2566771966 10000;
BA_ "GenMsgSendType" BO_ 2564882174 0;
BA_ "GenMsgCycleTime" BO_ 2564882174 1000;
BA_ "GenMsgDelayTime" BO_ 2563833598 100;
BA_ "GenMsgSendType" BO_ 2563833598 0;
BA_ "GenMsgCycleTime" BO_ 2563833598 5000;
BA_ "TpJ1939VarDlc" BO_ 2566843390 1;
BA_ "GenMsgSendType" BO_ 2566844926 0;
BA_ "GenMsgCycleTime" BO_ 2566844926 100;
BA_ "GenMsgSendType" BO_ 2566775294 0;
BA_ "GenMsgCycleTime" BO_ 2566775294 1000;
BA_ "GenMsgSendType" BO_ 2566803710 0;
BA_ "GenMsgCycleTime" BO_ 2566803710 1000;
BA_ "GenMsgDelayTime" BO_ 2566719486 100;
BA_ "GenMsgSendType" BO_ 2566719486 0;
BA_ "GenMsgCycleTime" BO_ 2566719486 1000;
BA_ "GenMsgSendType" BO_ 2163223550 0;
BA_ "GenMsgCycleTime" BO_ 2163223550 20;
BA_ "GenMsgSendType" BO_ 2566714878 0;
BA_ "GenMsgCycleTime" BO_ 2566714878 1000;
BA_ "GenMsgSendType" BO_ 2566714622 0;
BA_ "GenMsgCycleTime" BO_ 2566714622 1000;
BA_ "GenMsgSendType" BO_ 2566715390 0;
BA_ "GenMsgCycleTime" BO_ 2566715390 1000;
BA_ "GenMsgSendType" BO_ 2566715134 0;
BA_ "GenMsgCycleTime" BO_ 2566715134 1000;
BA_ "GenMsgDelayTime" BO_ 2365400830 20;
BA_ "GenMsgSendType" BO_ 2365400830 0;
BA_ "GenMsgCycleTime" BO_ 2365400830 100;
BA_ "GenMsgDelayTime" BO_ 2365401342 20;
BA_ "GenMsgSendType" BO_ 2365401342 0;
BA_ "GenMsgCycleTime" BO_ 2365401342 100;
BA_ "GenMsgDelayTime" BO_ 2365401854 20;
BA_ "GenMsgSendType" BO_ 2365401854 0;
BA_ "GenMsgCycleTime" BO_ 2365401854 100;
BA_ "GenMsgDelayTime" BO_ 2365402366 20;
BA_ "GenMsgSendType" BO_ 2365402366 0;
BA_ "GenMsgCycleTime" BO_ 2365402366 100;
BA_ "GenMsgDelayTime" BO_ 2365402878 20;
BA_ "GenMsgSendType" BO_ 2365402878 0;
BA_ "GenMsgCycleTime" BO_ 2365402878 100;
BA_ "GenMsgDelayTime" BO_ 2365403390 20;
BA_ "GenMsgSendType" BO_ 2365403390 0;
BA_ "GenMsgCycleTime" BO_ 2365403390 100;
BA_ "SigType" SG_ 2566767870 EmergencyBrakingActive 5;
BA_ "SPN" SG_ 2566767870 EmergencyBrakingActive 5847;
BA_ "SigType" SG_ 2566767870 PrkngBrakeActuatorFullyActivated 4;
BA_ "SPN" SG_ 2566767870 PrkngBrakeActuatorFullyActivated 5275;
BA_ "SigType" SG_ 2566767870 XBRAccelerationLimit 1;
BA_ "GenSigStartValue" SG_ 2566767870 XBRAccelerationLimit 25;
BA_ "SPN" SG_ 2566767870 XBRAccelerationLimit 2921;
BA_ "SPN" SG_ 2566767870 XBRActiveCtrlMode 2918;
BA_ "SigType" SG_ 2566767870 XBRSystemState 5;
BA_ "SPN" SG_ 2566767870 XBRSystemState 2917;
BA_ "SigType" SG_ 2566767870 FoundationBrakeUse 5;
BA_ "SPN" SG_ 2566767870 FoundationBrakeUse 2919;
BA_ "SPN" SG_ 2566767870 HillHolderMode 2912;
BA_ "SPN" SG_ 2566767870 HaltBrakeMode 2913;
BA_ "SigType" SG_ 2566767870 BrakeTempWarning 5;
BA_ "SPN" SG_ 2566767870 BrakeTempWarning 3839;
BA_ "SigType" SG_ 2633936126 BrkLnngRmningRearAxle3RightWheel 1;
BA_ "SPN" SG_ 2633936126 BrkLnngRmningRearAxle3RightWheel 1106;
BA_ "SigType" SG_ 2633936126 BrkLnngRminingRearAxle3LeftWheel 1;
BA_ "SPN" SG_ 2633936126 BrkLnngRminingRearAxle3LeftWheel 1105;
BA_ "SigType" SG_ 2633936126 BrkLnngRmningRearAxle2RightWheel 1;
BA_ "SPN" SG_ 2633936126 BrkLnngRmningRearAxle2RightWheel 1104;
BA_ "SigType" SG_ 2633936126 BrkLnngRminingRearAxle2LeftWheel 1;
BA_ "SPN" SG_ 2633936126 BrkLnngRminingRearAxle2LeftWheel 1103;
BA_ "SigType" SG_ 2633936126 BrkLnngRmningRearAxle1RightWheel 1;
BA_ "SPN" SG_ 2633936126 BrkLnngRmningRearAxle1RightWheel 1102;
BA_ "SigType" SG_ 2633936126 BrkLnngRminingRearAxle1LeftWheel 1;
BA_ "SPN" SG_ 2633936126 BrkLnngRminingRearAxle1LeftWheel 1101;
BA_ "SigType" SG_ 2633936126 BrkLnngRmningFrontAxleRightWheel 1;
BA_ "SPN" SG_ 2633936126 BrkLnngRmningFrontAxleRightWheel 1100;
BA_ "SigType" SG_ 2633936126 BrkLnngRminingFrontAxleLeftWheel 1;
BA_ "SPN" SG_ 2633936126 BrkLnngRminingFrontAxleLeftWheel 1099;
BA_ "SigType" SG_ 2566827518 BrkAppPrssHghRngRrAxl3RightWheel 1;
BA_ "SPN" SG_ 2566827518 BrkAppPrssHghRngRrAxl3RightWheel 1098;
BA_ "SigType" SG_ 2566827518 BrkAppPrssHghRngRrAxle3LeftWheel 1;
BA_ "SPN" SG_ 2566827518 BrkAppPrssHghRngRrAxle3LeftWheel 1097;
BA_ "SigType" SG_ 2566827518 BrkAppPrssHghRngRrAxl2RightWheel 1;
BA_ "SPN" SG_ 2566827518 BrkAppPrssHghRngRrAxl2RightWheel 1096;
BA_ "SigType" SG_ 2566827518 BrkAppPrssHghRngRrAxle2LeftWheel 1;
BA_ "SPN" SG_ 2566827518 BrkAppPrssHghRngRrAxle2LeftWheel 1095;
BA_ "SigType" SG_ 2566827518 BrkAppPrssHghRngRrAxle1LeftWheel 1;
BA_ "SPN" SG_ 2566827518 BrkAppPrssHghRngRrAxle1LeftWheel 1093;
BA_ "SigType" SG_ 2566827518 BrkAppPrssHghRngFrntAxlRghtWheel 1;
BA_ "SPN" SG_ 2566827518 BrkAppPrssHghRngFrntAxlRghtWheel 1092;
BA_ "SigType" SG_ 2566827518 BrkAppPrssHghRngFrntAxlLeftWheel 1;
BA_ "SPN" SG_ 2566827518 BrkAppPrssHghRngFrntAxlLeftWheel 1091;
BA_ "SigType" SG_ 2566827518 BrkAppPrssHghRngRrAxl1RightWheel 1;
BA_ "SPN" SG_ 2566827518 BrkAppPrssHghRngRrAxl1RightWheel 1094;
BA_ "SigType" SG_ 2566832126 RelativeSpeedRearAxle2RightWheel 1;
BA_ "SPN" SG_ 2566832126 RelativeSpeedRearAxle2RightWheel 910;
BA_ "SigType" SG_ 2566832126 RelativeSpeedRearAxle2LeftWheel 1;
BA_ "SPN" SG_ 2566832126 RelativeSpeedRearAxle2LeftWheel 909;
BA_ "SigType" SG_ 2566832126 RelativeSpeedRearAxle1RightWheel 1;
BA_ "SPN" SG_ 2566832126 RelativeSpeedRearAxle1RightWheel 908;
BA_ "SigType" SG_ 2566832126 RelativeSpeedRearAxle1LeftWheel 1;
BA_ "SPN" SG_ 2566832126 RelativeSpeedRearAxle1LeftWheel 907;
BA_ "SigType" SG_ 2566832126 RelativeSpeedFrontAxleRightWheel 1;
BA_ "SPN" SG_ 2566832126 RelativeSpeedFrontAxleRightWheel 906;
BA_ "SigType" SG_ 2566832126 RelativeSpeedFrontAxleLeftWheel 1;
BA_ "SPN" SG_ 2566832126 RelativeSpeedFrontAxleLeftWheel 905;
BA_ "SigType" SG_ 2566832126 FrontAxleSpeed 1;
BA_ "SPN" SG_ 2566832126 FrontAxleSpeed 904;
BA_ "SigType" SG_ 2565865982 TrctrMntdTrailerABSWarningSignal 5;
BA_ "SPN" SG_ 2565865982 TrctrMntdTrailerABSWarningSignal 1792;
BA_ "SigType" SG_ 2565865982 TrailerABSStatus 5;
BA_ "SPN" SG_ 2565865982 TrailerABSStatus 1836;
BA_ "SigType" SG_ 2565865982 HaltBrakeSwitch 4;
BA_ "SPN" SG_ 2565865982 HaltBrakeSwitch 2911;
BA_ "SPN" SG_ 2565865982 SrcAddrssOfCntrllngDvcFrBrkeCtrl 1481;
BA_ "SigType" SG_ 2565865982 ATC_ASRInformationSignal 5;
BA_ "SPN" SG_ 2565865982 ATC_ASRInformationSignal 1793;
BA_ "SigType" SG_ 2565865982 ABS_EBSAmberWarningSignal 5;
BA_ "SPN" SG_ 2565865982 ABS_EBSAmberWarningSignal 1438;
BA_ "SigType" SG_ 2565865982 EBSRedWarningSignal 5;
BA_ "SPN" SG_ 2565865982 EBSRedWarningSignal 1439;
BA_ "SigType" SG_ 2565865982 ABSFullyOperational 5;
BA_ "SPN" SG_ 2565865982 ABSFullyOperational 1243;
BA_ "SigType" SG_ 2565865982 EngRetarderSelection 1;
BA_ "SPN" SG_ 2565865982 EngRetarderSelection 973;
BA_ "SigType" SG_ 2565865982 RemoteAccelEnableSwitch 4;
BA_ "SPN" SG_ 2565865982 RemoteAccelEnableSwitch 969;
BA_ "SigType" SG_ 2565865982 EngAuxShutdownSwitch 4;
BA_ "SPN" SG_ 2565865982 EngAuxShutdownSwitch 970;
BA_ "SigType" SG_ 2565865982 EngDerateSwitch 4;
BA_ "SPN" SG_ 2565865982 EngDerateSwitch 971;
BA_ "SigType" SG_ 2565865982 AccelInterlockSwitch 4;
BA_ "SPN" SG_ 2565865982 AccelInterlockSwitch 972;
BA_ "SigType" SG_ 2565865982 TractionCtrlOverrideSwitch 4;
BA_ "SPN" SG_ 2565865982 TractionCtrlOverrideSwitch 1238;
BA_ "SigType" SG_ 2565865982 ASRHillHolderSwitch 4;
BA_ "SPN" SG_ 2565865982 ASRHillHolderSwitch 577;
BA_ "SigType" SG_ 2565865982 ASROffroadSwitch 4;
BA_ "SPN" SG_ 2565865982 ASROffroadSwitch 576;
BA_ "SigType" SG_ 2565865982 ABSOffroadSwitch 4;
BA_ "SPN" SG_ 2565865982 ABSOffroadSwitch 575;
BA_ "SigType" SG_ 2565865982 BrakePedalPos 1;
BA_ "SPN" SG_ 2565865982 BrakePedalPos 521;
BA_ "SigType" SG_ 2565865982 EBSBrakeSwitch 4;
BA_ "SPN" SG_ 2565865982 EBSBrakeSwitch 1121;
BA_ "SigType" SG_ 2565865982 AntiLockBrakingActive 5;
BA_ "SPN" SG_ 2565865982 AntiLockBrakingActive 563;
BA_ "SigType" SG_ 2565865982 ASRBrakeCtrlActive 5;
BA_ "SPN" SG_ 2565865982 ASRBrakeCtrlActive 562;
BA_ "SigType" SG_ 2565865982 ASREngCtrlActive 5;
BA_ "SPN" SG_ 2565865982 ASREngCtrlActive 561;
BA_ "SigType" SG_ 2565867262 DiffLockStRearAxle3 5;
BA_ "SPN" SG_ 2565867262 DiffLockStRearAxle3 7716;
BA_ "SigType" SG_ 2565867262 RearAxleGroupEngagementStatus 5;
BA_ "SPN" SG_ 2565867262 RearAxleGroupEngagementStatus 3820;
BA_ "SigType" SG_ 2565867262 FrontAxleGroupEngagementStatus 5;
BA_ "SPN" SG_ 2565867262 FrontAxleGroupEngagementStatus 3819;
BA_ "SigType" SG_ 2565867262 DiffLockStateCentralRear 5;
BA_ "SPN" SG_ 2565867262 DiffLockStateCentralRear 566;
BA_ "SigType" SG_ 2565867262 DiffLockStateCentralFront 5;
BA_ "SPN" SG_ 2565867262 DiffLockStateCentralFront 565;
BA_ "SigType" SG_ 2565867262 DiffLockStateCentral 5;
BA_ "SPN" SG_ 2565867262 DiffLockStateCentral 564;
BA_ "SigType" SG_ 2565867262 DiffLockStateRearAxle2 5;
BA_ "SPN" SG_ 2565867262 DiffLockStateRearAxle2 570;
BA_ "SigType" SG_ 2565867262 DiffLockStateRearAxle1 5;
BA_ "SPN" SG_ 2565867262 DiffLockStateRearAxle1 569;
BA_ "SigType" SG_ 2565867262 DiffLockStateFrontAxle2 5;
BA_ "SPN" SG_ 2565867262 DiffLockStateFrontAxle2 568;
BA_ "SigType" SG_ 2565867262 DiffLockStateFrontAxle1 5;
BA_ "SPN" SG_ 2565867262 DiffLockStateFrontAxle1 567;
BA_ "SPN" SG_ 2565867262 Location 927;
BA_ "SigType" SG_ 2566821118 EngCoolantPress2 1;
BA_ "SPN" SG_ 2566821118 EngCoolantPress2 7313;
BA_ "SigType" SG_ 2566821118 EngExRangeCoolantPress 1;
BA_ "SPN" SG_ 2566821118 EngExRangeCoolantPress 20;
BA_ "SigType" SG_ 2566821118 SeaWaterPumpOutletPress 1;
BA_ "SPN" SG_ 2566821118 SeaWaterPumpOutletPress 2435;
BA_ "SigType" SG_ 2566821118 EngAuxCoolantTemp 1;
BA_ "SPN" SG_ 2566821118 EngAuxCoolantTemp 1212;
BA_ "SigType" SG_ 2566821118 EngAuxCoolantPress 1;
BA_ "SPN" SG_ 2566821118 EngAuxCoolantPress 1203;
BA_ "SigType" SG_ 2566810622 Driver2Identification 8;
BA_ "SPN" SG_ 2566810622 Driver2Identification 1626;
BA_ "SigType" SG_ 2566810622 Driver1Identification 8;
BA_ "SPN" SG_ 2566810622 Driver1Identification 1625;
BA_ "SigType" SG_ 2566847742 EngOilFilterDiffPress7471 1;
BA_ "SPN" SG_ 2566847742 EngOilFilterDiffPress7471 7471;
BA_ "SigType" SG_ 2566847742 FuelLevel2 1;
BA_ "SPN" SG_ 2566847742 FuelLevel2 38;
BA_ "SigType" SG_ 2566847742 CargoAmbientTemp 1;
BA_ "SPN" SG_ 2566847742 CargoAmbientTemp 169;
BA_ "SigType" SG_ 2566847742 EngOilFilterDiffPress 1;
BA_ "SPN" SG_ 2566847742 EngOilFilterDiffPress 99;
BA_ "SigType" SG_ 2566847742 EngFuelFilterDiffPress 1;
BA_ "SPN" SG_ 2566847742 EngFuelFilterDiffPress 95;
BA_ "SigType" SG_ 2566847742 FuelLevel1 1;
BA_ "SPN" SG_ 2566847742 FuelLevel1 96;
BA_ "SigType" SG_ 2566847742 WasherFluidLevel 1;
BA_ "SPN" SG_ 2566847742 WasherFluidLevel 80;
BA_ "SigType" SG_ 2498778622 EngCyl8AverageCombustionDuration 1;
BA_ "SPN" SG_ 2498778622 EngCyl8AverageCombustionDuration 6514;
BA_ "SigType" SG_ 2498778622 EngCyl8AvrgCntrOfCmbustionTiming 1;
BA_ "SPN" SG_ 2498778622 EngCyl8AvrgCntrOfCmbustionTiming 6513;
BA_ "SigType" SG_ 2498778622 EngCyl8AvrgStrtOfCmbustionTiming 1;
BA_ "SPN" SG_ 2498778622 EngCyl8AvrgStrtOfCmbustionTiming 6512;
BA_ "SigType" SG_ 2498778622 EngCyl8IndctedMeanEffectivePress 1;
BA_ "SPN" SG_ 2498778622 EngCyl8IndctedMeanEffectivePress 6511;
BA_ "SigType" SG_ 2498778366 EngCyl7AverageCombustionDuration 1;
BA_ "SPN" SG_ 2498778366 EngCyl7AverageCombustionDuration 6510;
BA_ "SigType" SG_ 2498778366 EngCyl7AvrgCntrOfCmbustionTiming 1;
BA_ "SPN" SG_ 2498778366 EngCyl7AvrgCntrOfCmbustionTiming 6509;
BA_ "SigType" SG_ 2498778366 EngCyl7AvrgStrtOfCmbustionTiming 1;
BA_ "SPN" SG_ 2498778366 EngCyl7AvrgStrtOfCmbustionTiming 6508;
BA_ "SigType" SG_ 2498778366 EngCyl7IndctedMeanEffectivePress 1;
BA_ "SPN" SG_ 2498778366 EngCyl7IndctedMeanEffectivePress 6507;
BA_ "SigType" SG_ 2498778110 EngCyl6AverageCombustionDuration 1;
BA_ "SPN" SG_ 2498778110 EngCyl6AverageCombustionDuration 6506;
BA_ "SigType" SG_ 2498778110 EngCyl6AvrgCntrOfCmbustionTiming 1;
BA_ "SPN" SG_ 2498778110 EngCyl6AvrgCntrOfCmbustionTiming 6505;
BA_ "SigType" SG_ 2498778110 EngCyl6AvrgStrtOfCmbustionTiming 1;
BA_ "SPN" SG_ 2498778110 EngCyl6AvrgStrtOfCmbustionTiming 6504;
BA_ "SigType" SG_ 2498778110 EngCyl6IndctedMeanEffectivePress 1;
BA_ "SPN" SG_ 2498778110 EngCyl6IndctedMeanEffectivePress 6503;
BA_ "SigType" SG_ 2498777854 EngCyl5AverageCombustionDuration 1;
BA_ "SPN" SG_ 2498777854 EngCyl5AverageCombustionDuration 6502;
BA_ "SigType" SG_ 2498777854 EngCyl5AvrgCntrOfCmbustionTiming 1;
BA_ "SPN" SG_ 2498777854 EngCyl5AvrgCntrOfCmbustionTiming 6501;
BA_ "SigType" SG_ 2498777854 EngCyl5AvrgStrtOfCmbustionTiming 1;
BA_ "SPN" SG_ 2498777854 EngCyl5AvrgStrtOfCmbustionTiming 6500;
BA_ "SigType" SG_ 2498777854 EngCyl5IndctedMeanEffectivePress 1;
BA_ "SPN" SG_ 2498777854 EngCyl5IndctedMeanEffectivePress 6499;
BA_ "SigType" SG_ 2498777598 EngCyl4AverageCombustionDuration 1;
BA_ "SPN" SG_ 2498777598 EngCyl4AverageCombustionDuration 6498;
BA_ "SigType" SG_ 2498777598 EngCyl4AvrgCntrOfCmbustionTiming 1;
BA_ "SPN" SG_ 2498777598 EngCyl4AvrgCntrOfCmbustionTiming 6497;
BA_ "SigType" SG_ 2498777598 EngCyl4AvrgStrtOfCmbustionTiming 1;
BA_ "SPN" SG_ 2498777598 EngCyl4AvrgStrtOfCmbustionTiming 6496;
BA_ "SigType" SG_ 2498777598 EngCyl4IndctedMeanEffectivePress 1;
BA_ "SPN" SG_ 2498777598 EngCyl4IndctedMeanEffectivePress 6495;
BA_ "SigType" SG_ 2498777342 EngCyl3AverageCombustionDuration 1;
BA_ "SPN" SG_ 2498777342 EngCyl3AverageCombustionDuration 6494;
BA_ "SigType" SG_ 2498777342 EngCyl3AvrgCntrOfCmbustionTiming 1;
BA_ "SPN" SG_ 2498777342 EngCyl3AvrgCntrOfCmbustionTiming 6493;
BA_ "SigType" SG_ 2498777342 EngCyl3AvrgStrtOfCmbustionTiming 1;
BA_ "SPN" SG_ 2498777342 EngCyl3AvrgStrtOfCmbustionTiming 6492;
BA_ "SigType" SG_ 2498777342 EngCyl3IndctedMeanEffectivePress 1;
BA_ "SPN" SG_ 2498777342 EngCyl3IndctedMeanEffectivePress 6491;
BA_ "SigType" SG_ 2566768382 EngCldStrtFlIgniterRelayFeedback 4;
BA_ "SPN" SG_ 2566768382 EngCldStrtFlIgniterRelayFeedback 5550;
BA_ "SigType" SG_ 2566768382 EngColdStartFuelIgniterRelay 5;
BA_ "SPN" SG_ 2566768382 EngColdStartFuelIgniterRelay 5549;
BA_ "SigType" SG_ 2566768382 EngColdStartFuelIgniterCmd 1;
BA_ "SPN" SG_ 2566768382 EngColdStartFuelIgniterCmd 5548;
BA_ "SPN" SG_ 2566768382 EngStartEnableDevice2Config 2898;
BA_ "SPN" SG_ 2566768382 EngStartEnableDevice1Config 2899;
BA_ "SigType" SG_ 2566768382 EngStartEnableDevice2 5;
BA_ "SPN" SG_ 2566768382 EngStartEnableDevice2 1804;
BA_ "SigType" SG_ 2566768382 EngStartEnableDevice1 5;
BA_ "SPN" SG_ 2566768382 EngStartEnableDevice1 626;
BA_ "SigType" SG_ 2566811902 PoweredVehicleWeight 1;
BA_ "SPN" SG_ 2566811902 PoweredVehicleWeight 1585;
BA_ "SigType" SG_ 2566811902 GrossCombinationVehicleWeight 1;
BA_ "SPN" SG_ 2566811902 GrossCombinationVehicleWeight 1760;
BA_ "SigType" SG_ 2563768062 MxCntinuousRetarderTorqueLimitRq 1;
BA_ "SPN" SG_ 2563768062 MxCntinuousRetarderTorqueLimitRq 1791;
BA_ "SigType" SG_ 2563768062 MnCntinuousRetarderTorqueLimitRq 1;
BA_ "SPN" SG_ 2563768062 MnCntinuousRetarderTorqueLimitRq 1790;
BA_ "SigType" SG_ 2563768062 MxContinuousRetarderSpeedLimitRq 1;
BA_ "SPN" SG_ 2563768062 MxContinuousRetarderSpeedLimitRq 1789;
BA_ "SigType" SG_ 2563768062 MnContinuousRetarderSpeedLimitRq 1;
BA_ "SPN" SG_ 2563768062 MnContinuousRetarderSpeedLimitRq 1788;
BA_ "SigType" SG_ 2563768062 EngTorqueLimitRqMaxContinuous 1;
BA_ "GenSigStartValue" SG_ 2563768062 EngTorqueLimitRqMaxContinuous 125;
BA_ "SPN" SG_ 2563768062 EngTorqueLimitRqMaxContinuous 1787;
BA_ "SigType" SG_ 2563768062 EngTorqueLimitRqMinContinuous 1;
BA_ "GenSigStartValue" SG_ 2563768062 EngTorqueLimitRqMinContinuous 125;
BA_ "SPN" SG_ 2563768062 EngTorqueLimitRqMinContinuous 1786;
BA_ "SigType" SG_ 2563768062 EngSpeedLimitRqMaxContinuous 1;
BA_ "SPN" SG_ 2563768062 EngSpeedLimitRqMaxContinuous 1785;
BA_ "SigType" SG_ 2563768062 EngSpeedLimitRqMinContinuous 1;
BA_ "SPN" SG_ 2563768062 EngSpeedLimitRqMinContinuous 1784;
BA_ "SigType" SG_ 2633924862 EngAverageCombustionTime 1;
BA_ "SPN" SG_ 2633924862 EngAverageCombustionTime 1465;
BA_ "SigType" SG_ 2633924862 EngDesiredCombustionTime 1;
BA_ "SPN" SG_ 2633924862 EngDesiredCombustionTime 1464;
BA_ "SigType" SG_ 2633924606 EngCyl20CombustionTime 1;
BA_ "SPN" SG_ 2633924606 EngCyl20CombustionTime 1463;
BA_ "SigType" SG_ 2633924606 EngCyl19CombustionTime 1;
BA_ "SPN" SG_ 2633924606 EngCyl19CombustionTime 1462;
BA_ "SigType" SG_ 2633924606 EngCyl18CombustionTime 1;
BA_ "SPN" SG_ 2633924606 EngCyl18CombustionTime 1461;
BA_ "SigType" SG_ 2633924606 EngCyl17CombustionTime 1;
BA_ "SPN" SG_ 2633924606 EngCyl17CombustionTime 1460;
BA_ "SigType" SG_ 2633924350 EngCyl16CombustionTime 1;
BA_ "SPN" SG_ 2633924350 EngCyl16CombustionTime 1459;
BA_ "SigType" SG_ 2633924350 EngCyl15CombustionTime 1;
BA_ "SPN" SG_ 2633924350 EngCyl15CombustionTime 1458;
BA_ "SigType" SG_ 2633924350 EngCyl14CombustionTime 1;
BA_ "SPN" SG_ 2633924350 EngCyl14CombustionTime 1457;
BA_ "SigType" SG_ 2633924350 EngCyl13CombustionTime 1;
BA_ "SPN" SG_ 2633924350 EngCyl13CombustionTime 1456;
BA_ "SigType" SG_ 2633924094 EngCyl12CombustionTime 1;
BA_ "SPN" SG_ 2633924094 EngCyl12CombustionTime 1455;
BA_ "SigType" SG_ 2633924094 EngCyl11CombustionTime 1;
BA_ "SPN" SG_ 2633924094 EngCyl11CombustionTime 1454;
BA_ "SigType" SG_ 2633924094 EngCyl10CombustionTime 1;
BA_ "SPN" SG_ 2633924094 EngCyl10CombustionTime 1453;
BA_ "SigType" SG_ 2633924094 EngCyl9CombustionTime 1;
BA_ "SPN" SG_ 2633924094 EngCyl9CombustionTime 1452;
BA_ "SigType" SG_ 2633923838 EngCyl8CombustionTime 1;
BA_ "SPN" SG_ 2633923838 EngCyl8CombustionTime 1451;
BA_ "SigType" SG_ 2633923838 EngCyl7CombustionTime 1;
BA_ "SPN" SG_ 2633923838 EngCyl7CombustionTime 1450;
BA_ "SigType" SG_ 2633923838 EngCyl6CombustionTime 1;
BA_ "SPN" SG_ 2633923838 EngCyl6CombustionTime 1449;
BA_ "SigType" SG_ 2633923838 EngCyl5CombustionTime 1;
BA_ "SPN" SG_ 2633923838 EngCyl5CombustionTime 1448;
BA_ "SigType" SG_ 2633923582 EngCyl4CombustionTime 1;
BA_ "SPN" SG_ 2633923582 EngCyl4CombustionTime 1447;
BA_ "SigType" SG_ 2633923582 EngCyl3CombustionTime 1;
BA_ "SPN" SG_ 2633923582 EngCyl3CombustionTime 1446;
BA_ "SigType" SG_ 2633923582 EngCyl2CombustionTime 1;
BA_ "SPN" SG_ 2633923582 EngCyl2CombustionTime 1445;
BA_ "SigType" SG_ 2633923582 EngCyl1CombustionTime 1;
BA_ "SPN" SG_ 2633923582 EngCyl1CombustionTime 1444;
BA_ "SigType" SG_ 2633878014 TotalCountOfConfigChangesMade 1;
BA_ "SPN" SG_ 2633878014 TotalCountOfConfigChangesMade 2887;
BA_ "SigType" SG_ 2566771966 VehTrailerStatus 4;
BA_ "SPN" SG_ 2566771966 VehTrailerStatus 7711;
BA_ "SigType" SG_ 2566771966 TransOilLevelRq 5;
BA_ "SPN" SG_ 2566771966 TransOilLevelRq 3809;
BA_ "SigType" SG_ 2566771966 FifthWheelReleaseCtrl 4;
BA_ "SPN" SG_ 2566771966 FifthWheelReleaseCtrl 3314;
BA_ "SigType" SG_ 2566771966 FfthWhlRleaseCtrlSecurityLockout 4;
BA_ "SPN" SG_ 2566771966 FfthWhlRleaseCtrlSecurityLockout 3315;
BA_ "SPN" SG_ 2566771966 TransferCaseSelectorSwitch 2796;
BA_ "SigType" SG_ 2564882174 SelectedMaxVehicleSpeedLimit 1;
BA_ "SPN" SG_ 2564882174 SelectedMaxVehicleSpeedLimit 2596;
BA_ "SigType" SG_ 2564882174 RqCabZoneHeating 5;
BA_ "SPN" SG_ 2564882174 RqCabZoneHeating 1686;
BA_ "SigType" SG_ 2564882174 RqEngZoneHeating 5;
BA_ "SPN" SG_ 2564882174 RqEngZoneHeating 1685;
BA_ "SPN" SG_ 2564882174 AuxHeaterModeRq 1683;
BA_ "SigType" SG_ 2564882174 EngAutomaticStartEnableSwitch 4;
BA_ "SPN" SG_ 2564882174 EngAutomaticStartEnableSwitch 1656;
BA_ "SigType" SG_ 2564882174 AtomaticGearShiftingEnableSwitch 4;
BA_ "SPN" SG_ 2564882174 AtomaticGearShiftingEnableSwitch 1666;
BA_ "SigType" SG_ 2564882174 AFTRegenForceSw 4;
BA_ "SPN" SG_ 2564882174 AFTRegenForceSw 3696;
BA_ "SigType" SG_ 2564882174 AFTRegenInhSw 4;
BA_ "SPN" SG_ 2564882174 AFTRegenInhSw 3695;
BA_ "SigType" SG_ 2564882174 VhclLmtngSpdGovernorEnableSwitch 4;
BA_ "SPN" SG_ 2564882174 VhclLmtngSpdGovernorEnableSwitch 1653;
BA_ "SigType" SG_ 2564882174 VhclLmtngSpdGvrnrIncrementSwitch 4;
BA_ "SPN" SG_ 2564882174 VhclLmtngSpdGvrnrIncrementSwitch 1654;
BA_ "SigType" SG_ 2564882174 VhclLmtngSpdGvrnrDecrementSwitch 4;
BA_ "SPN" SG_ 2564882174 VhclLmtngSpdGvrnrDecrementSwitch 1655;
BA_ "SigType" SG_ 2564882174 ParkBrakeCmd 5;
BA_ "SPN" SG_ 2564882174 ParkBrakeCmd 5630;
BA_ "SigType" SG_ 2564882174 SeatBeltSwitch 4;
BA_ "SPN" SG_ 2564882174 SeatBeltSwitch 1856;
BA_ "SigType" SG_ 2564882174 OperatorSeatDirectionSwitch 4;
BA_ "SPN" SG_ 2564882174 OperatorSeatDirectionSwitch 1714;
BA_ "SigType" SG_ 2564882174 BatteryMainSwitchHoldRq 5;
BA_ "SPN" SG_ 2564882174 BatteryMainSwitchHoldRq 1682;
BA_ "SigType" SG_ 2564882174 AuxHeaterCoolantPumpRq 5;
BA_ "SPN" SG_ 2564882174 AuxHeaterCoolantPumpRq 1684;
BA_ "SigType" SG_ 2564882174 CabInteriorTempCmd 1;
BA_ "SPN" SG_ 2564882174 CabInteriorTempCmd 1691;
BA_ "SigType" SG_ 2564882174 RequestedPercentFanSpeed 1;
BA_ "SPN" SG_ 2564882174 RequestedPercentFanSpeed 986;
BA_ "SigType" SG_ 2563833598 SwtchBcklghtIllmntnBrghtnssPrcnt 1;
BA_ "SPN" SG_ 2563833598 SwtchBcklghtIllmntnBrghtnssPrcnt 5532;
BA_ "SigType" SG_ 2563833598 IlluminationBrightnessPercent 1;
BA_ "SPN" SG_ 2563833598 IlluminationBrightnessPercent 1487;
BA_ "SigType" SG_ 2563833598 SwtchIndctnIllmntnBrghtnssPrcent 1;
BA_ "SPN" SG_ 2563833598 SwtchIndctnIllmntnBrghtnssPrcent 6820;
BA_ "SigType" SG_ 2566843390 UnitNumber 8;
BA_ "SPN" SG_ 2566843390 UnitNumber 233;
BA_ "SigType" SG_ 2566843390 SerialNumber 8;
BA_ "SPN" SG_ 2566843390 SerialNumber 588;
BA_ "SigType" SG_ 2566843390 Model 8;
BA_ "SPN" SG_ 2566843390 Model 587;
BA_ "SigType" SG_ 2566843390 Make 8;
BA_ "SPN" SG_ 2566843390 Make 586;
BA_ "SigType" SG_ 2566844926 EngShutdownOverrideSwitch 4;
BA_ "SPN" SG_ 2566844926 EngShutdownOverrideSwitch 1237;
BA_ "SigType" SG_ 2566844926 EngTestModeSwitch 4;
BA_ "SPN" SG_ 2566844926 EngTestModeSwitch 966;
BA_ "SigType" SG_ 2566844926 EngIdleDecrementSwitch 4;
BA_ "SPN" SG_ 2566844926 EngIdleDecrementSwitch 967;
BA_ "SigType" SG_ 2566844926 EngIdleIncrementSwitch 4;
BA_ "SPN" SG_ 2566844926 EngIdleIncrementSwitch 968;
BA_ "SPN" SG_ 2566844926 CruiseCtrlStates 527;
BA_ "SPN" SG_ 2566844926 PTOGovernorState 976;
BA_ "SigType" SG_ 2566844926 CruiseCtrlSetSpeed 1;
BA_ "SPN" SG_ 2566844926 CruiseCtrlSetSpeed 86;
BA_ "SigType" SG_ 2566844926 CruiseCtrlAccelerateSwitch 4;
BA_ "SPN" SG_ 2566844926 CruiseCtrlAccelerateSwitch 602;
BA_ "SigType" SG_ 2566844926 CruiseCtrlResumeSwitch 4;
BA_ "SPN" SG_ 2566844926 CruiseCtrlResumeSwitch 601;
BA_ "SigType" SG_ 2566844926 CruiseCtrlCoastSwitch 4;
BA_ "SPN" SG_ 2566844926 CruiseCtrlCoastSwitch 600;
BA_ "SigType" SG_ 2566844926 CruiseCtrlSetSwitch 4;
BA_ "SPN" SG_ 2566844926 CruiseCtrlSetSwitch 599;
BA_ "SigType" SG_ 2566844926 ClutchSwitch 4;
BA_ "SPN" SG_ 2566844926 ClutchSwitch 598;
BA_ "SigType" SG_ 2566844926 BrakeSwitch 4;
BA_ "SPN" SG_ 2566844926 BrakeSwitch 597;
BA_ "SigType" SG_ 2566844926 CruiseCtrlEnableSwitch 4;
BA_ "SPN" SG_ 2566844926 CruiseCtrlEnableSwitch 596;
BA_ "SigType" SG_ 2566844926 CruiseCtrlActive 4;
BA_ "SPN" SG_ 2566844926 CruiseCtrlActive 595;
BA_ "SigType" SG_ 2566844926 WheelBasedVehicleSpeed 1;
BA_ "SPN" SG_ 2566844926 WheelBasedVehicleSpeed 84;
BA_ "SigType" SG_ 2566844926 ParkBrakeReleaseInhibitRq 5;
BA_ "SPN" SG_ 2566844926 ParkBrakeReleaseInhibitRq 3807;
BA_ "SigType" SG_ 2566844926 CruiseCtrlPauseSwitch 4;
BA_ "SPN" SG_ 2566844926 CruiseCtrlPauseSwitch 1633;
BA_ "SigType" SG_ 2566844926 ParkingBrakeSwitch 4;
BA_ "SPN" SG_ 2566844926 ParkingBrakeSwitch 70;
BA_ "SigType" SG_ 2566844926 TwoSpeedAxleSwitch 4;
BA_ "SPN" SG_ 2566844926 TwoSpeedAxleSwitch 69;
BA_ "SigType" SG_ 2566843902 MaxVehicleSpeedLimit6808 1;
BA_ "SPN" SG_ 2566843902 MaxVehicleSpeedLimit6808 6808;
BA_ "SigType" SG_ 2566843902 CruiseCtrlLowSetLimitSpeed 1;
BA_ "SPN" SG_ 2566843902 CruiseCtrlLowSetLimitSpeed 88;
BA_ "SigType" SG_ 2566843902 CruiseCtrlHighSetLimitSpeed 1;
BA_ "SPN" SG_ 2566843902 CruiseCtrlHighSetLimitSpeed 87;
BA_ "SigType" SG_ 2566843902 MaxVehicleSpeedLimit 1;
BA_ "SPN" SG_ 2566843902 MaxVehicleSpeedLimit 74;
BA_ "SigType" SG_ 2566809598 AuxHeaterMaxOutputPower 1;
BA_ "SPN" SG_ 2566809598 AuxHeaterMaxOutputPower 1690;
BA_ "SigType" SG_ 2633940222 TripServiceBrakeApplications 1;
BA_ "SPN" SG_ 2633940222 TripServiceBrakeApplications 993;
BA_ "SigType" SG_ 2633940222 TripServiceBrakeDistance 1;
BA_ "SPN" SG_ 2633940222 TripServiceBrakeDistance 992;
BA_ "SigType" SG_ 2633940222 TripCompressionBrakeDistance 1;
BA_ "SPN" SG_ 2633940222 TripCompressionBrakeDistance 991;
BA_ "SigType" SG_ 2633940222 TotalCompressionBrakeDistance 1;
BA_ "SPN" SG_ 2633940222 TotalCompressionBrakeDistance 990;
BA_ "SigType" SG_ 2566775294 CbA_CRfrgrntCmpressorOutletPress 1;
BA_ "SPN" SG_ 2566775294 CbA_CRfrgrntCmpressorOutletPress 2609;
BA_ "SigType" SG_ 2566803710 SLIBattery4Temp 1;
BA_ "SPN" SG_ 2566803710 SLIBattery4Temp 2780;
BA_ "SigType" SG_ 2566803710 SLIBattery3Temp 1;
BA_ "SPN" SG_ 2566803710 SLIBattery3Temp 2779;
BA_ "SigType" SG_ 2566803710 Battery2Temp 1;
BA_ "SPN" SG_ 2566803710 Battery2Temp 1801;
BA_ "SigType" SG_ 2566803710 Battery1Temp 1;
BA_ "SPN" SG_ 2566803710 Battery1Temp 1800;
BA_ "SigType" SG_ 2566719486 VhclAccelerationRateLimitLampCmd 5;
BA_ "SPN" SG_ 2566719486 VhclAccelerationRateLimitLampCmd 6899;
BA_ "SigType" SG_ 2566719486 EngSpeedVeryHighLampCmd 5;
BA_ "SPN" SG_ 2566719486 EngSpeedVeryHighLampCmd 6710;
BA_ "SigType" SG_ 2566719486 EngSpeedHighLampCmd 5;
BA_ "SPN" SG_ 2566719486 EngSpeedHighLampCmd 6709;
BA_ "SigType" SG_ 2566719486 EngCtrlModule3ReadyForUseLampCmd 5;
BA_ "SPN" SG_ 2566719486 EngCtrlModule3ReadyForUseLampCmd 6207;
BA_ "SigType" SG_ 2566719486 EngCtrlModule2ReadyForUseLampCmd 5;
BA_ "SPN" SG_ 2566719486 EngCtrlModule2ReadyForUseLampCmd 6206;
BA_ "SigType" SG_ 2566719486 EngCtrlModule1ReadyForUseLampCmd 5;
BA_ "SPN" SG_ 2566719486 EngCtrlModule1ReadyForUseLampCmd 6205;
BA_ "SigType" SG_ 2566719486 EngFuelFilterRestrictedLampCmd 5;
BA_ "SPN" SG_ 2566719486 EngFuelFilterRestrictedLampCmd 5469;
BA_ "SigType" SG_ 2566719486 EngAirFilterRestrictionLampCmd 5;
BA_ "SPN" SG_ 2566719486 EngAirFilterRestrictionLampCmd 5086;
BA_ "SigType" SG_ 2566719486 EngIdleManagementActiveLampCmd 5;
BA_ "SPN" SG_ 2566719486 EngIdleManagementActiveLampCmd 5085;
BA_ "SigType" SG_ 2566719486 EngCoolantLevelLowLampCmd 5;
BA_ "SPN" SG_ 2566719486 EngCoolantLevelLowLampCmd 5084;
BA_ "SigType" SG_ 2566719486 EngCoolantTempHighLampCmd 5;
BA_ "SPN" SG_ 2566719486 EngCoolantTempHighLampCmd 5083;
BA_ "SigType" SG_ 2566719486 EngOilPressLowLampCmd 5;
BA_ "SPN" SG_ 2566719486 EngOilPressLowLampCmd 5082;
BA_ "SigType" SG_ 2566719486 CmprssnBrkEnblSwtchIndctrLampCmd 5;
BA_ "SPN" SG_ 2566719486 CmprssnBrkEnblSwtchIndctrLampCmd 3987;
BA_ "SigType" SG_ 2566719486 EngBrakeActiveLampCmd 5;
BA_ "SPN" SG_ 2566719486 EngBrakeActiveLampCmd 5081;
BA_ "SigType" SG_ 2566719486 OBDMalfunctionIndicatorLampCmd 5;
BA_ "SPN" SG_ 2566719486 OBDMalfunctionIndicatorLampCmd 5080;
BA_ "SigType" SG_ 2566719486 EngRedStopLampCmd 5;
BA_ "SPN" SG_ 2566719486 EngRedStopLampCmd 5079;
BA_ "SigType" SG_ 2566719486 EngAmberWarningLampCmd 5;
BA_ "SPN" SG_ 2566719486 EngAmberWarningLampCmd 5078;
BA_ "SigType" SG_ 2566719486 EngProtectLampCmd 5;
BA_ "SPN" SG_ 2566719486 EngProtectLampCmd 5077;
BA_ "SigType" SG_ 2163223550 CrashChecksum 12;
BA_ "SPN" SG_ 2163223550 CrashChecksum 4975;
BA_ "SigType" SG_ 2163223550 CrashCounter 11;
BA_ "SPN" SG_ 2163223550 CrashCounter 4974;
BA_ "SPN" SG_ 2163223550 CrashType 4973;
BA_ "SigType" SG_ 2566714878 EngChrgArClr2PrecoolerEfficiency 1;
BA_ "SPN" SG_ 2566714878 EngChrgArClr2PrecoolerEfficiency 5288;
BA_ "SigType" SG_ 2566714878 EngChrgArClr2PrecoolerOutletTemp 1;
BA_ "SPN" SG_ 2566714878 EngChrgArClr2PrecoolerOutletTemp 5287;
BA_ "SigType" SG_ 2566714878 EngChrgArClr2PrecoolerIntakeTemp 1;
BA_ "SPN" SG_ 2566714878 EngChrgArClr2PrecoolerIntakeTemp 5286;
BA_ "SigType" SG_ 2566714622 EngChargeAirCooler2Efficiency 1;
BA_ "SPN" SG_ 2566714622 EngChargeAirCooler2Efficiency 5292;
BA_ "SigType" SG_ 2566714622 EngChrgeAirCooler2AmbientAirTemp 1;
BA_ "SPN" SG_ 2566714622 EngChrgeAirCooler2AmbientAirTemp 5291;
BA_ "SigType" SG_ 2566714622 EngChargeAirCooler2OutletTemp 1;
BA_ "SPN" SG_ 2566714622 EngChargeAirCooler2OutletTemp 5290;
BA_ "SigType" SG_ 2566714622 EngChargeAirCooler2IntakeTemp 1;
BA_ "SPN" SG_ 2566714622 EngChargeAirCooler2IntakeTemp 5289;
BA_ "SigType" SG_ 2566715390 EngChrgArClr1PrecoolerEfficiency 1;
BA_ "SPN" SG_ 2566715390 EngChrgArClr1PrecoolerEfficiency 5282;
BA_ "SigType" SG_ 2566715390 EngChrgArClr1PrecoolerOutletTemp 1;
BA_ "SPN" SG_ 2566715390 EngChrgArClr1PrecoolerOutletTemp 5281;
BA_ "SigType" SG_ 2566715390 EngChrgArClr1PrecoolerIntakeTemp 1;
BA_ "SPN" SG_ 2566715390 EngChrgArClr1PrecoolerIntakeTemp 5280;
BA_ "SigType" SG_ 2566715134 EngChargeAirCooler1Efficiency 1;
BA_ "SPN" SG_ 2566715134 EngChargeAirCooler1Efficiency 5285;
BA_ "SigType" SG_ 2566715134 EngChrgeAirCooler1AmbientAirTemp 1;
BA_ "SPN" SG_ 2566715134 EngChrgeAirCooler1AmbientAirTemp 5284;
BA_ "SigType" SG_ 2566715134 EngChargeAirCooler1IntakeTemp 1;
BA_ "SPN" SG_ 2566715134 EngChargeAirCooler1IntakeTemp 5283;
BA_ "SigType" SG_ 2365400830 Joystick9Button9PressedStatus 4;
BA_ "SPN" SG_ 2365400830 Joystick9Button9PressedStatus 4697;
BA_ "SigType" SG_ 2365400830 Joystick9Button10PressedStatus 4;
BA_ "SPN" SG_ 2365400830 Joystick9Button10PressedStatus 4696;
BA_ "SigType" SG_ 2365400830 Joystick9Button11PressedStatus 4;
BA_ "SPN" SG_ 2365400830 Joystick9Button11PressedStatus 4695;
BA_ "SigType" SG_ 2365400830 Joystick9Button12PressedStatus 4;
BA_ "SPN" SG_ 2365400830 Joystick9Button12PressedStatus 4694;
BA_ "SigType" SG_ 2365400830 Joystick9Button5PressedStatus 4;
BA_ "SPN" SG_ 2365400830 Joystick9Button5PressedStatus 4693;
BA_ "SigType" SG_ 2365400830 Joystick9Button6PressedStatus 4;
BA_ "SPN" SG_ 2365400830 Joystick9Button6PressedStatus 4692;
BA_ "SigType" SG_ 2365400830 Joystick9Button7PressedStatus 4;
BA_ "SPN" SG_ 2365400830 Joystick9Button7PressedStatus 4691;
BA_ "SigType" SG_ 2365400830 Joystick9Button8PressedStatus 4;
BA_ "SPN" SG_ 2365400830 Joystick9Button8PressedStatus 4690;
BA_ "SigType" SG_ 2365400830 Joystick9Button1PressedStatus 4;
BA_ "SPN" SG_ 2365400830 Joystick9Button1PressedStatus 4689;
BA_ "SigType" SG_ 2365400830 Joystick9Button2PressedStatus 4;
BA_ "SPN" SG_ 2365400830 Joystick9Button2PressedStatus 4688;
BA_ "SigType" SG_ 2365400830 Joystick9Button3PressedStatus 4;
BA_ "SPN" SG_ 2365400830 Joystick9Button3PressedStatus 4687;
BA_ "SigType" SG_ 2365400830 Joystick9Button4PressedStatus 4;
BA_ "SPN" SG_ 2365400830 Joystick9Button4PressedStatus 4686;
BA_ "SigType" SG_ 2365400830 Joystick9XAxisDetentPosStatus 4;
BA_ "SPN" SG_ 2365400830 Joystick9XAxisDetentPosStatus 4685;
BA_ "SigType" SG_ 2365400830 Joystick9YAxisDetentPosStatus 4;
BA_ "SPN" SG_ 2365400830 Joystick9YAxisDetentPosStatus 4684;
BA_ "SPN" SG_ 2365400830 Joystick9YAxisPos 4683;
BA_ "SigType" SG_ 2365400830 Jystck9YAxsLvrFrwrdPstvPosStatus 4;
BA_ "SPN" SG_ 2365400830 Jystck9YAxsLvrFrwrdPstvPosStatus 4682;
BA_ "SigType" SG_ 2365400830 Jystck9YAxsLvrBckNgtivePosStatus 4;
BA_ "SPN" SG_ 2365400830 Jystck9YAxsLvrBckNgtivePosStatus 4681;
BA_ "SigType" SG_ 2365400830 Joystick9YAxisNeutralPosStatus 4;
BA_ "SPN" SG_ 2365400830 Joystick9YAxisNeutralPosStatus 4680;
BA_ "SPN" SG_ 2365400830 Joystick9XAxisPos 4679;
BA_ "SigType" SG_ 2365400830 Jystck9XAxsLvrRghtPstvePosStatus 4;
BA_ "SPN" SG_ 2365400830 Jystck9XAxsLvrRghtPstvePosStatus 4678;
BA_ "SigType" SG_ 2365400830 Jystck9XAxsLvrLftNgtivePosStatus 4;
BA_ "SPN" SG_ 2365400830 Jystck9XAxsLvrLftNgtivePosStatus 4677;
BA_ "SigType" SG_ 2365400830 Joystick9XAxisNeutralPosStatus 4;
BA_ "SPN" SG_ 2365400830 Joystick9XAxisNeutralPosStatus 4676;
BA_ "SigType" SG_ 2365401342 Joystick8Button9PressedStatus 4;
BA_ "SPN" SG_ 2365401342 Joystick8Button9PressedStatus 4660;
BA_ "SigType" SG_ 2365401342 Joystick8Button10PressedStatus 4;
BA_ "SPN" SG_ 2365401342 Joystick8Button10PressedStatus 4659;
BA_ "SigType" SG_ 2365401342 Joystick8Button11PressedStatus 4;
BA_ "SPN" SG_ 2365401342 Joystick8Button11PressedStatus 4658;
BA_ "SigType" SG_ 2365401342 Joystick8Button12PressedStatus 4;
BA_ "SPN" SG_ 2365401342 Joystick8Button12PressedStatus 4657;
BA_ "SigType" SG_ 2365401342 Joystick8Button5PressedStatus 4;
BA_ "SPN" SG_ 2365401342 Joystick8Button5PressedStatus 4656;
BA_ "SigType" SG_ 2365401342 Joystick8Button6PressedStatus 4;
BA_ "SPN" SG_ 2365401342 Joystick8Button6PressedStatus 4655;
BA_ "SigType" SG_ 2365401342 Joystick8Button7PressedStatus 4;
BA_ "SPN" SG_ 2365401342 Joystick8Button7PressedStatus 4654;
BA_ "SigType" SG_ 2365401342 Joystick8Button8PressedStatus 4;
BA_ "SPN" SG_ 2365401342 Joystick8Button8PressedStatus 4653;
BA_ "SigType" SG_ 2365401342 Joystick8Button1PressedStatus 4;
BA_ "SPN" SG_ 2365401342 Joystick8Button1PressedStatus 4652;
BA_ "SigType" SG_ 2365401342 Joystick8Button2PressedStatus 4;
BA_ "SPN" SG_ 2365401342 Joystick8Button2PressedStatus 4651;
BA_ "SigType" SG_ 2365401342 Joystick8Button3PressedStatus 4;
BA_ "SPN" SG_ 2365401342 Joystick8Button3PressedStatus 4650;
BA_ "SigType" SG_ 2365401342 Joystick8Button4PressedStatus 4;
BA_ "SPN" SG_ 2365401342 Joystick8Button4PressedStatus 4649;
BA_ "SigType" SG_ 2365401342 Joystick8XAxisDetentPosStatus 4;
BA_ "SPN" SG_ 2365401342 Joystick8XAxisDetentPosStatus 4648;
BA_ "SigType" SG_ 2365401342 Joystick8YAxisDetentPosStatus 4;
BA_ "SPN" SG_ 2365401342 Joystick8YAxisDetentPosStatus 4647;
BA_ "SPN" SG_ 2365401342 Joystick8YAxisPos 4646;
BA_ "SigType" SG_ 2365401342 Jystck8YAxsLvrFrwrdPstvPosStatus 4;
BA_ "SPN" SG_ 2365401342 Jystck8YAxsLvrFrwrdPstvPosStatus 4645;
BA_ "SigType" SG_ 2365401342 Jystck8YAxsLvrBckNgtivePosStatus 4;
BA_ "SPN" SG_ 2365401342 Jystck8YAxsLvrBckNgtivePosStatus 4644;
BA_ "SigType" SG_ 2365401342 Joystick8YAxisNeutralPosStatus 4;
BA_ "SPN" SG_ 2365401342 Joystick8YAxisNeutralPosStatus 4643;
BA_ "SPN" SG_ 2365401342 Joystick8XAxisPos 4642;
BA_ "SigType" SG_ 2365401342 Jystck8XAxsLvrRghtPstvePosStatus 4;
BA_ "SPN" SG_ 2365401342 Jystck8XAxsLvrRghtPstvePosStatus 4641;
BA_ "SigType" SG_ 2365401342 Jystck8XAxsLvrLftNgtivePosStatus 4;
BA_ "SPN" SG_ 2365401342 Jystck8XAxsLvrLftNgtivePosStatus 4640;
BA_ "SigType" SG_ 2365401342 Joystick8XAxisNeutralPosStatus 4;
BA_ "SPN" SG_ 2365401342 Joystick8XAxisNeutralPosStatus 4639;
BA_ "SigType" SG_ 2365401854 Joystick7Button9PressedStatus 4;
BA_ "SPN" SG_ 2365401854 Joystick7Button9PressedStatus 4623;
BA_ "SigType" SG_ 2365401854 Joystick7Button10PressedStatus 4;
BA_ "SPN" SG_ 2365401854 Joystick7Button10PressedStatus 4622;
BA_ "SigType" SG_ 2365401854 Joystick7Button11PressedStatus 4;
BA_ "SPN" SG_ 2365401854 Joystick7Button11PressedStatus 4621;
BA_ "SigType" SG_ 2365401854 Joystick7Button12PressedStatus 4;
BA_ "SPN" SG_ 2365401854 Joystick7Button12PressedStatus 4620;
BA_ "SigType" SG_ 2365401854 Joystick7Button5PressedStatus 4;
BA_ "SPN" SG_ 2365401854 Joystick7Button5PressedStatus 4619;
BA_ "SigType" SG_ 2365401854 Joystick7Button6PressedStatus 4;
BA_ "SPN" SG_ 2365401854 Joystick7Button6PressedStatus 4618;
BA_ "SigType" SG_ 2365401854 Joystick7Button7PressedStatus 4;
BA_ "SPN" SG_ 2365401854 Joystick7Button7PressedStatus 4617;
BA_ "SigType" SG_ 2365401854 Joystick7Button8PressedStatus 4;
BA_ "SPN" SG_ 2365401854 Joystick7Button8PressedStatus 4616;
BA_ "SigType" SG_ 2365401854 Joystick7Button1PressedStatus 4;
BA_ "SPN" SG_ 2365401854 Joystick7Button1PressedStatus 4615;
BA_ "SigType" SG_ 2365401854 Joystick7Button2PressedStatus 4;
BA_ "SPN" SG_ 2365401854 Joystick7Button2PressedStatus 4614;
BA_ "SigType" SG_ 2365401854 Joystick7Button3PressedStatus 4;
BA_ "SPN" SG_ 2365401854 Joystick7Button3PressedStatus 4613;
BA_ "SigType" SG_ 2365401854 Joystick7Button4PressedStatus 4;
BA_ "SPN" SG_ 2365401854 Joystick7Button4PressedStatus 4612;
BA_ "SigType" SG_ 2365401854 Joystick7XAxisDetentPosStatus 4;
BA_ "SPN" SG_ 2365401854 Joystick7XAxisDetentPosStatus 4611;
BA_ "SigType" SG_ 2365401854 Joystick7YAxisDetentPosStatus 4;
BA_ "SPN" SG_ 2365401854 Joystick7YAxisDetentPosStatus 4610;
BA_ "SPN" SG_ 2365401854 Joystick7YAxisPos 4609;
BA_ "SigType" SG_ 2365401854 Jystck7YAxsLvrFrwrdPstvPosStatus 4;
BA_ "SPN" SG_ 2365401854 Jystck7YAxsLvrFrwrdPstvPosStatus 4608;
BA_ "SigType" SG_ 2365401854 Jystck7YAxsLvrBckNgtivePosStatus 4;
BA_ "SPN" SG_ 2365401854 Jystck7YAxsLvrBckNgtivePosStatus 4607;
BA_ "SigType" SG_ 2365401854 Joystick7YAxisNeutralPosStatus 4;
BA_ "SPN" SG_ 2365401854 Joystick7YAxisNeutralPosStatus 4606;
BA_ "SPN" SG_ 2365401854 Joystick7XAxisPos 4605;
BA_ "SigType" SG_ 2365401854 Jystck7XAxsLvrRghtPstvePosStatus 4;
BA_ "SPN" SG_ 2365401854 Jystck7XAxsLvrRghtPstvePosStatus 4604;
BA_ "SigType" SG_ 2365401854 Jystck7XAxsLvrLftNgtivePosStatus 4;
BA_ "SPN" SG_ 2365401854 Jystck7XAxsLvrLftNgtivePosStatus 4603;
BA_ "SigType" SG_ 2365401854 Joystick7XAxisNeutralPosStatus 4;
BA_ "SPN" SG_ 2365401854 Joystick7XAxisNeutralPosStatus 4602;
BA_ "SigType" SG_ 2365402366 Joystick6Button9PressedStatus 4;
BA_ "SPN" SG_ 2365402366 Joystick6Button9PressedStatus 4586;
BA_ "SigType" SG_ 2365402366 Joystick6Button10PressedStatus 4;
BA_ "SPN" SG_ 2365402366 Joystick6Button10PressedStatus 4585;
BA_ "SigType" SG_ 2365402366 Joystick6Button11PressedStatus 4;
BA_ "SPN" SG_ 2365402366 Joystick6Button11PressedStatus 4584;
BA_ "SigType" SG_ 2365402366 Joystick6Button12PressedStatus 4;
BA_ "SPN" SG_ 2365402366 Joystick6Button12PressedStatus 4583;
BA_ "SigType" SG_ 2365402366 Joystick6Button5PressedStatus 4;
BA_ "SPN" SG_ 2365402366 Joystick6Button5PressedStatus 4582;
BA_ "SigType" SG_ 2365402366 Joystick6Button6PressedStatus 4;
BA_ "SPN" SG_ 2365402366 Joystick6Button6PressedStatus 4581;
BA_ "SigType" SG_ 2365402366 Joystick6Button7PressedStatus 4;
BA_ "SPN" SG_ 2365402366 Joystick6Button7PressedStatus 4580;
BA_ "SigType" SG_ 2365402366 Joystick6Button8PressedStatus 4;
BA_ "SPN" SG_ 2365402366 Joystick6Button8PressedStatus 4579;
BA_ "SigType" SG_ 2365402366 Joystick6Button1PressedStatus 4;
BA_ "SPN" SG_ 2365402366 Joystick6Button1PressedStatus 4578;
BA_ "SigType" SG_ 2365402366 Joystick6Button2PressedStatus 4;
BA_ "SPN" SG_ 2365402366 Joystick6Button2PressedStatus 4577;
BA_ "SigType" SG_ 2365402366 Joystick6Button3PressedStatus 4;
BA_ "SPN" SG_ 2365402366 Joystick6Button3PressedStatus 4576;
BA_ "SigType" SG_ 2365402366 Joystick6Button4PressedStatus 4;
BA_ "SPN" SG_ 2365402366 Joystick6Button4PressedStatus 4575;
BA_ "SigType" SG_ 2365402366 Joystick6XAxisDetentPosStatus 4;
BA_ "SPN" SG_ 2365402366 Joystick6XAxisDetentPosStatus 4574;
BA_ "SigType" SG_ 2365402366 Joystick6YAxisDetentPosStatus 4;
BA_ "SPN" SG_ 2365402366 Joystick6YAxisDetentPosStatus 4573;
BA_ "SPN" SG_ 2365402366 Joystick6YAxisPos 4572;
BA_ "SigType" SG_ 2365402366 Jystck6YAxsLvrFrwrdPstvPosStatus 4;
BA_ "SPN" SG_ 2365402366 Jystck6YAxsLvrFrwrdPstvPosStatus 4571;
BA_ "SigType" SG_ 2365402366 Jystck6YAxsLvrBckNgtivePosStatus 4;
BA_ "SPN" SG_ 2365402366 Jystck6YAxsLvrBckNgtivePosStatus 4570;
BA_ "SigType" SG_ 2365402366 Joystick6YAxisNeutralPosStatus 4;
BA_ "SPN" SG_ 2365402366 Joystick6YAxisNeutralPosStatus 4569;
BA_ "SPN" SG_ 2365402366 Joystick6XAxisPos 4568;
BA_ "SigType" SG_ 2365402366 Jystck6XAxsLvrRghtPstvePosStatus 4;
BA_ "SPN" SG_ 2365402366 Jystck6XAxsLvrRghtPstvePosStatus 4567;
BA_ "SigType" SG_ 2365402366 Jystck6XAxsLvrLftNgtivePosStatus 4;
BA_ "SPN" SG_ 2365402366 Jystck6XAxsLvrLftNgtivePosStatus 4566;
BA_ "SigType" SG_ 2365402366 Joystick6XAxisNeutralPosStatus 4;
BA_ "SPN" SG_ 2365402366 Joystick6XAxisNeutralPosStatus 4565;
BA_ "SigType" SG_ 2365402878 Joystick5Button9PressedStatus 4;
BA_ "SPN" SG_ 2365402878 Joystick5Button9PressedStatus 4549;
BA_ "SigType" SG_ 2365402878 Joystick5Button10PressedStatus 4;
BA_ "SPN" SG_ 2365402878 Joystick5Button10PressedStatus 4548;
BA_ "SigType" SG_ 2365402878 Joystick5Button11PressedStatus 4;
BA_ "SPN" SG_ 2365402878 Joystick5Button11PressedStatus 4547;
BA_ "SigType" SG_ 2365402878 Joystick5Button12PressedStatus 4;
BA_ "SPN" SG_ 2365402878 Joystick5Button12PressedStatus 4546;
BA_ "SigType" SG_ 2365402878 Joystick5Button5PressedStatus 4;
BA_ "SPN" SG_ 2365402878 Joystick5Button5PressedStatus 4545;
BA_ "SigType" SG_ 2365402878 Joystick5Button6PressedStatus 4;
BA_ "SPN" SG_ 2365402878 Joystick5Button6PressedStatus 4544;
BA_ "SigType" SG_ 2365402878 Joystick5Button7PressedStatus 4;
BA_ "SPN" SG_ 2365402878 Joystick5Button7PressedStatus 4543;
BA_ "SigType" SG_ 2365402878 Joystick5Button8PressedStatus 4;
BA_ "SPN" SG_ 2365402878 Joystick5Button8PressedStatus 4542;
BA_ "SigType" SG_ 2365402878 Joystick5Button1PressedStatus 4;
BA_ "SPN" SG_ 2365402878 Joystick5Button1PressedStatus 4541;
BA_ "SigType" SG_ 2365402878 Joystick5Button2PressedStatus 4;
BA_ "SPN" SG_ 2365402878 Joystick5Button2PressedStatus 4540;
BA_ "SigType" SG_ 2365402878 Joystick5Button3PressedStatus 4;
BA_ "SPN" SG_ 2365402878 Joystick5Button3PressedStatus 4539;
BA_ "SigType" SG_ 2365402878 Joystick5Button4PressedStatus 4;
BA_ "SPN" SG_ 2365402878 Joystick5Button4PressedStatus 4538;
BA_ "SigType" SG_ 2365402878 Joystick5XAxisDetentPosStatus 4;
BA_ "SPN" SG_ 2365402878 Joystick5XAxisDetentPosStatus 4537;
BA_ "SigType" SG_ 2365402878 Joystick5YAxisDetentPosStatus 4;
BA_ "SPN" SG_ 2365402878 Joystick5YAxisDetentPosStatus 4536;
BA_ "SPN" SG_ 2365402878 Joystick5YAxisPos 4535;
BA_ "SigType" SG_ 2365402878 Jystck5YAxsLvrFrwrdPstvPosStatus 4;
BA_ "SPN" SG_ 2365402878 Jystck5YAxsLvrFrwrdPstvPosStatus 4534;
BA_ "SigType" SG_ 2365402878 Jystck5YAxsLvrBckNgtivePosStatus 4;
BA_ "SPN" SG_ 2365402878 Jystck5YAxsLvrBckNgtivePosStatus 4533;
BA_ "SigType" SG_ 2365402878 Joystick5YAxisNeutralPosStatus 4;
BA_ "SPN" SG_ 2365402878 Joystick5YAxisNeutralPosStatus 4532;
BA_ "SPN" SG_ 2365402878 Joystick5XAxisPos 4531;
BA_ "SigType" SG_ 2365402878 Jystck5XAxsLvrRghtPstvePosStatus 4;
BA_ "SPN" SG_ 2365402878 Jystck5XAxsLvrRghtPstvePosStatus 4530;
BA_ "SigType" SG_ 2365402878 Jystck5XAxsLvrLftNgtivePosStatus 4;
BA_ "SPN" SG_ 2365402878 Jystck5XAxsLvrLftNgtivePosStatus 4529;
BA_ "SigType" SG_ 2365402878 Joystick5XAxisNeutralPosStatus 4;
BA_ "SPN" SG_ 2365402878 Joystick5XAxisNeutralPosStatus 4528;
BA_ "SigType" SG_ 2365403390 Joystick4Button9PressedStatus 4;
BA_ "SPN" SG_ 2365403390 Joystick4Button9PressedStatus 4512;
BA_ "SigType" SG_ 2365403390 Joystick4Button10PressedStatus 4;
BA_ "SPN" SG_ 2365403390 Joystick4Button10PressedStatus 4511;
BA_ "SigType" SG_ 2365403390 Joystick4Button11PressedStatus 4;
BA_ "SPN" SG_ 2365403390 Joystick4Button11PressedStatus 4510;
BA_ "SigType" SG_ 2365403390 Joystick4Button12PressedStatus 4;
BA_ "SPN" SG_ 2365403390 Joystick4Button12PressedStatus 4509;
BA_ "SigType" SG_ 2365403390 Joystick4Button5PressedStatus 4;
BA_ "SPN" SG_ 2365403390 Joystick4Button5PressedStatus 4508;
BA_ "SigType" SG_ 2365403390 Joystick4Button6PressedStatus 4;
BA_ "SPN" SG_ 2365403390 Joystick4Button6PressedStatus 4507;
BA_ "SigType" SG_ 2365403390 Joystick4Button7PressedStatus 4;
BA_ "SPN" SG_ 2365403390 Joystick4Button7PressedStatus 4506;
BA_ "SigType" SG_ 2365403390 Joystick4Button8PressedStatus 4;
BA_ "SPN" SG_ 2365403390 Joystick4Button8PressedStatus 4505;
BA_ "SigType" SG_ 2365403390 Joystick4Button1PressedStatus 4;
BA_ "SPN" SG_ 2365403390 Joystick4Button1PressedStatus 4504;
BA_ "SigType" SG_ 2365403390 Joystick4Button2PressedStatus 4;
BA_ "SPN" SG_ 2365403390 Joystick4Button2PressedStatus 4503;
BA_ "SigType" SG_ 2365403390 Joystick4Button3PressedStatus 4;
BA_ "SPN" SG_ 2365403390 Joystick4Button3PressedStatus 4502;
BA_ "SigType" SG_ 2365403390 Joystick4Button4PressedStatus 4;
BA_ "SPN" SG_ 2365403390 Joystick4Button4PressedStatus 4501;
BA_ "SigType" SG_ 2365403390 Joystick4XAxisDetentPosStatus 4;
BA_ "SPN" SG_ 2365403390 Joystick4XAxisDetentPosStatus 4500;
BA_ "SigType" SG_ 2365403390 Joystick4YAxisDetentPosStatus 4;
BA_ "SPN" SG_ 2365403390 Joystick4YAxisDetentPosStatus 4499;
BA_ "SPN" SG_ 2365403390 Joystick4YAxisPos 4498;
BA_ "SigType" SG_ 2365403390 Jystck4YAxsLvrFrwrdPstvPosStatus 4;
BA_ "SPN" SG_ 2365403390 Jystck4YAxsLvrFrwrdPstvPosStatus 4497;
BA_ "SigType" SG_ 2365403390 Jystck4YAxsLvrBckNgtivePosStatus 4;
BA_ "SPN" SG_ 2365403390 Jystck4YAxsLvrBckNgtivePosStatus 4496;
BA_ "SigType" SG_ 2365403390 Joystick4YAxisNeutralPosStatus 4;
BA_ "SPN" SG_ 2365403390 Joystick4YAxisNeutralPosStatus 4495;
BA_ "SPN" SG_ 2365403390 Joystick4XAxisPos 4494;
BA_ "SigType" SG_ 2365403390 Jystck4XAxsLvrRghtPstvePosStatus 4;
BA_ "SPN" SG_ 2365403390 Jystck4XAxsLvrRghtPstvePosStatus 4493;
BA_ "SigType" SG_ 2365403390 Jystck4XAxsLvrLftNgtivePosStatus 4;
BA_ "SPN" SG_ 2365403390 Jystck4XAxsLvrLftNgtivePosStatus 4492;
BA_ "SigType" SG_ 2365403390 Joystick4XAxisNeutralPosStatus 4;
BA_ "SPN" SG_ 2365403390 Joystick4XAxisNeutralPosStatus 4491;
VAL_ 2566767870 EmergencyBrakingActive 3 "not available" 2 "reserved" 1 "active" 0 "inactive" ;
VAL_ 2566767870 PrkngBrakeActuatorFullyActivated 3 "Not available" 2 "Error" 1 "Parking Brake Actuator fully activated" 0 "Parking Brake Actuator not fully activated" ;
VAL_ 2566767870 XBRActiveCtrlMode 15 "Not available" 3 "Maximum mode of XBR acceleration control being executed" 2 "Addition mode of XBR acceleration control being executed" 1 "Driver's brake demand being executed" 0 "No brake demand being executed" ;
VAL_ 2566767870 XBRSystemState 3 "not available" 2 "No external brake demand will be accepted" 1 "Only external brake demand of highest XBR Priority" 0 "Any external brake demand will be accepted" ;
VAL_ 2566767870 FoundationBrakeUse 3 "Not available" 2 "Reserved" 1 "Foundation brakes in use" 0 "Foundation brakes not in use" ;
VAL_ 2566767870 HillHolderMode 7 "Not available" 6 "Hill holder not functional" 3 "Active,  but may activate parking brake if needed." 2 "Active,  but will change to inactive in a short time" 1 "Active" 0 "Inactive" ;
VAL_ 2566767870 HaltBrakeMode 7 "Not available" 6 "Halt brake not functional" 2 "Active,  but not functioning properly" 1 "Active" 0 "Inactive" ;
VAL_ 2566767870 BrakeTempWarning 3 "not available" 2 "Reserved" 1 "Active" 0 "Not Active" ;
VAL_ 2565865982 TrctrMntdTrailerABSWarningSignal 3 "Take no action" 2 "Reserved" 1 "On " 0 "Off" ;
VAL_ 2565865982 TrailerABSStatus 3 "Trailer ABS Status Information Not Available or Parameter Not Supported" 2 "Reserved" 1 "Trailer ABS Active" 0 "Trailer ABS Status Information Available But Not Active" ;
VAL_ 2565865982 HaltBrakeSwitch 3 "Not available" 2 "Error" 1 "Halt brake switch active" 0 "Halt brake switch passive" ;
VAL_ 2565865982 ATC_ASRInformationSignal 3 "Take no action" 2 "Reserved" 1 "On " 0 "Off" ;
VAL_ 2565865982 ABS_EBSAmberWarningSignal 3 "Take no action" 2 "Reserved" 1 "On" 0 "Off" ;
VAL_ 2565865982 EBSRedWarningSignal 3 "Take no action" 2 "Reserved" 1 "On" 0 "Off" ;
VAL_ 2565865982 ABSFullyOperational 3 "Not available" 2 "Reserved" 1 "Fully Operational" 0 "Not Fully Operational" ;
VAL_ 2565865982 RemoteAccelEnableSwitch 3 "Not available" 2 "Error" 1 "On" 0 "Off" ;
VAL_ 2565865982 EngAuxShutdownSwitch 3 "Not available" 2 "Error" 1 "On" 0 "Off" ;
VAL_ 2565865982 EngDerateSwitch 3 "Not available" 2 "Error" 1 "On" 0 "Off" ;
VAL_ 2565865982 AccelInterlockSwitch 3 "Not available" 2 "Error" 1 "On" 0 "Off" ;
VAL_ 2565865982 TractionCtrlOverrideSwitch 3 "Not available or not installed" 2 "Error" 1 "On" 0 "Off" ;
VAL_ 2565865982 ASRHillHolderSwitch 3 "Not available" 2 "Error" 1 "ASR “hill holder” switch active" 0 "ASR “hill holder” switch passive" ;
VAL_ 2565865982 ASROffroadSwitch 3 "Not available" 2 "Error" 1 "ASR off-road switch active" 0 "ASR off-road switch passive" ;
VAL_ 2565865982 ABSOffroadSwitch 3 "Not available" 2 "Error" 1 "ABS off-road switch active" 0 "ABS off-road switch passive" ;
VAL_ 2565865982 EBSBrakeSwitch 3 "Not available" 2 "Error" 1 "Brake pedal is being pressed" 0 "Brake pedal is not being pressed" ;
VAL_ 2565865982 AntiLockBrakingActive 3 "Not available" 2 "Reserved" 1 "ABS active" 0 "ABS passive but installed" ;
VAL_ 2565865982 ASRBrakeCtrlActive 3 "Not available" 2 "Reserved" 1 "ASR brake control active" 0 "ASR brake control passive but installed" ;
VAL_ 2565865982 ASREngCtrlActive 3 "Not available" 2 "Reserved" 1 "ASR engine control active" 0 "ASR engine control passive but installed" ;
VAL_ 2565867262 RearAxleGroupEngagementStatus 3 "not available" 2 "error" 1 "rear axle group engaged" 0 "rear axle group disengaged " ;
VAL_ 2565867262 FrontAxleGroupEngagementStatus 3 "not available" 2 "error" 1 "front axle group engaged" 0 "front axle group disengaged " ;
VAL_ 2565867262 DiffLockStateCentralRear 3 "Not available" 2 "Error" 1 "Differential lock engaged" 0 "Differential lock disengaged" ;
VAL_ 2565867262 DiffLockStateCentralFront 3 "Not available" 2 "Error" 1 "Differential lock engaged" 0 "Differential lock disengaged" ;
VAL_ 2565867262 DiffLockStateCentral 3 "Not available" 2 "Error" 1 "Differential lock engaged" 0 "Differential lock disengaged" ;
VAL_ 2565867262 DiffLockStateRearAxle2 3 "Not available" 2 "Error" 1 "Differential lock engaged" 0 "Differential lock disengaged" ;
VAL_ 2565867262 DiffLockStateRearAxle1 3 "Not available" 2 "Error" 1 "Differential lock engaged" 0 "Differential lock disengaged" ;
VAL_ 2565867262 DiffLockStateFrontAxle2 3 "Not available" 2 "Error" 1 "Differential lock engaged" 0 "Differential lock disengaged" ;
VAL_ 2565867262 DiffLockStateFrontAxle1 3 "Not available" 2 "Error" 1 "Differential lock engaged" 0 "Differential lock disengaged" ;
VAL_ 2566768382 EngCldStrtFlIgniterRelayFeedback 3 "Not available" 2 "Error" 1 "On" 0 "Off" ;
VAL_ 2566768382 EngColdStartFuelIgniterRelay 3 "Don't care/take no action" 2 "Reserved" 1 "On" 0 "Off" ;
VAL_ 2566768382 EngStartEnableDevice2Config 15 "not available" 4 "electric intake air heater installed" 3 "ether injection installed" 2 "fuelled start installed" 1 "glow plugs installed" 0 "no start enable device 2 installed" ;
VAL_ 2566768382 EngStartEnableDevice1Config 15 "not available" 4 "electric intake air heater installed" 3 "ether injection installed" 2 "fuelled start installed" 1 "glow plugs installed" 0 "no start enable device 1 installed" ;
VAL_ 2566768382 EngStartEnableDevice2 3 "not available" 2 "reserved" 1 "start enable ON" 0 "start enable OFF" ;
VAL_ 2566768382 EngStartEnableDevice1 3 "not available" 2 "reserved" 1 "start enable ON" 0 "start enable OFF" ;
VAL_ 2566771966 VehTrailerStatus 3 "Not available" 2 "Error" 1 "Trailer is detected" 0 "Trailer is not detected" ;
VAL_ 2566771966 TransOilLevelRq 3 "Don't care / take no action" 2 "Reserved" 1 "Transmission oil level reading desired" 0 "No transmission oil level reading desired" ;
VAL_ 2566771966 FifthWheelReleaseCtrl 3 "Not Available" 2 "Error" 1 "Coupler Unlocked" 0 "Coupler Locked" ;
VAL_ 2566771966 FfthWhlRleaseCtrlSecurityLockout 3 "Not Available" 2 "Error   " 1 "Fifth wheel release Enabled" 0 "Fifth wheel release Disabled" ;
VAL_ 2566771966 TransferCaseSelectorSwitch 7 "Not available" 6 "Error indicator" 5 "Reserved for SAE assignment" 4 "4 wheel low or Off Highway Range" 2 "Neutral" 1 "4 wheel high Normal or On Highway Range" 0 "2 wheel high Normal or On Highway Range" 3 "2 wheel low or Off Highway Range" ;
VAL_ 2564882174 RqCabZoneHeating 3 "Don't care/take no action" 2 "Reserved" 1 "Heat cab zone" 0 "Do not heat cab engine zone" ;
VAL_ 2564882174 RqEngZoneHeating 3 "Don't care/take no action" 2 "Reserved" 1 "Heat engine zone" 0 "Do not heat engine zone" ;
VAL_ 2564882174 AuxHeaterModeRq 15 "Don't care/take no action" 14 "Reserved" 4 "Heater pump up-keep" 3 "Normal mode" 2 "Economy mode" 1 "Off due to ADR per European Regulations for Transport of hazardous materials" 0 "De-activate auxiliary heater" ;
VAL_ 2564882174 EngAutomaticStartEnableSwitch 3 "Not available" 2 "Error" 1 "Switch in the on state" 0 "Switch in the off state" ;
VAL_ 2564882174 AtomaticGearShiftingEnableSwitch 3 "Not available" 2 "Error" 1 "Automated Gear Shifting is enabled" 0 "Automated Gear Shifting is disabled" ;
VAL_ 2564882174 AFTRegenForceSw 3 "not available " 2 "error " 1 "active " 0 "not active " ;
VAL_ 2564882174 AFTRegenInhSw 3 "not available " 2 "error " 1 "active " 0 "not active " ;
VAL_ 2564882174 VhclLmtngSpdGovernorEnableSwitch 3 "Not available" 2 "Error" 1 "Switched enabled" 0 "Switch disabled" ;
VAL_ 2564882174 VhclLmtngSpdGvrnrIncrementSwitch 3 "Not available" 2 "Error" 1 "Switch in the on state" 0 "Switch in the off state" ;
VAL_ 2564882174 VhclLmtngSpdGvrnrDecrementSwitch 2 "Error" 1 "Switch in the on state" 0 "Switch in the off state" 3 "Not available" ;
VAL_ 2564882174 ParkBrakeCmd 3 "Don't care/Take no action" 2 "SAE Reserved  " 1 "Park Brake apply requested" 0 "Park Brake apply not requested" ;
VAL_ 2564882174 SeatBeltSwitch 3 "Not Available" 2 "Error" 1 "OK" 0 "NOT Buckled" ;
VAL_ 2564882174 OperatorSeatDirectionSwitch 3 "Not Available" 2 "Error" 1 "Operator seat is facing forward" 0 "Operator seat not facing forward" ;
VAL_ 2564882174 BatteryMainSwitchHoldRq 3 "Don't care/take no action" 2 "undefined" 1 "Hold Battery Main Switch" 0 "Release Battery Main Switch" ;
VAL_ 2564882174 AuxHeaterCoolantPumpRq 3 "Don't care/take no action" 2 "Reserved" 1 "Activate water pump" 0 "Deactivate water pump" ;
VAL_ 2566844926 EngShutdownOverrideSwitch 3 "Not available" 2 "Error" 1 "On" 0 "Off" ;
VAL_ 2566844926 EngTestModeSwitch 3 "Not available" 2 "Error" 1 "On" 0 "Off" ;
VAL_ 2566844926 EngIdleDecrementSwitch 3 "Not available" 2 "Error" 1 "On" 0 "Off" ;
VAL_ 2566844926 EngIdleIncrementSwitch 3 "Not available" 2 "Error" 1 "On" 0 "Off" ;
VAL_ 2566844926 CruiseCtrlStates 7 "Not available" 6 "Accelerator Override" 5 "Set" 4 "Resume" 3 "Decelerate" 2 "Accelerate" 1 "Hold" 0 "Off/Disabled" ;
VAL_ 2566844926 PTOGovernorState 31 "Not available" 19 "PTO set speed memory 2" 18 "PTO set speed memory 1" 17 "Preprogrammed set speed 8" 16 "Preprogrammed set speed 7" 15 "Preprogrammed set speed 6" 14 "Preprogrammed set speed 5" 13 "Preprogrammed set speed 4" 12 "Preprogrammed set speed 3" 11 "Preprogrammed set speed 2" 10 "Preprogrammed set speed 1" 9 "Accelerator Override" 8 "Accelerate" 7 "Resume" 6 "Decelerate/Coast" 5 "Set" 4 "Remote Standby" 3 "Standby" 2 "Remote Hold" 1 "Hold" 0 "Off/Disabled" ;
VAL_ 2566844926 CruiseCtrlAccelerateSwitch 3 "Not available" 2 "Error" 1 "Cruise control activator in position “accelerate”" 0 "Cruise control activator not in the position “accelerate”" ;
VAL_ 2566844926 CruiseCtrlResumeSwitch 3 "Not available" 2 "Error" 1 "Cruise control activator in position “resume”" 0 "Cruise control activator not in the position “resume”" ;
VAL_ 2566844926 CruiseCtrlCoastSwitch 3 "Not available" 2 "Error" 1 "Cruise control activator in position “coast”" 0 "Cruise control activator not in the position “coast”" ;
VAL_ 2566844926 CruiseCtrlSetSwitch 3 "Not available" 2 "Error" 1 "Cruise control activator in position “set”" 0 "Cruise control activator not in the position “set”" ;
VAL_ 2566844926 ClutchSwitch 3 "Not available" 2 "Error" 1 "Clutch pedal depressed" 0 "Clutch pedal released" ;
VAL_ 2566844926 BrakeSwitch 3 "Not Available" 2 "Error" 1 "Brake pedal depressed" 0 "Brake pedal released" ;
VAL_ 2566844926 CruiseCtrlEnableSwitch 3 "Not available" 2 "Error" 1 "Cruise control enabled" 0 "Cruise control disabled" ;
VAL_ 2566844926 CruiseCtrlActive 3 "Not available" 2 "Error" 1 "Cruise control switched on" 0 "Cruise control switched off" ;
VAL_ 2566844926 ParkBrakeReleaseInhibitRq 3 "Unavailable" 2 "SAE reserved" 1 "Park Brake Release Inhibit requested" 0 "Park Brake Release Inhibit not requested" ;
VAL_ 2566844926 CruiseCtrlPauseSwitch 3 "-Take No Action" 2 "- Error Indicator" 1 "- On" 0 "- Off" ;
VAL_ 2566844926 ParkingBrakeSwitch 3 "Not available" 2 "Error" 1 "Parking brake set" 0 "Parking brake not set" ;
VAL_ 2566844926 TwoSpeedAxleSwitch 3 "Not available" 2 "Error" 1 "High speed range" 0 "Low speed range" ;
VAL_ 2566719486 VhclAccelerationRateLimitLampCmd 3 "Not available" 2 "Reserved" 1 "Lamp On" 0 "Lamp Off" ;
VAL_ 2566719486 EngSpeedVeryHighLampCmd 3 "Not available" 2 "Reserved" 1 "Lamp On" 0 "Lamp Off" ;
VAL_ 2566719486 EngSpeedHighLampCmd 3 "Not available" 2 "Reserved" 1 "Lamp On" 0 "Lamp Off" ;
VAL_ 2566719486 EngCtrlModule3ReadyForUseLampCmd 3 "Not available" 2 "Reserved" 1 "Lamp On" 0 "Lamp Off" ;
VAL_ 2566719486 EngCtrlModule2ReadyForUseLampCmd 3 "Not available" 2 "Reserved" 1 "Lamp On" 0 "Lamp Off" ;
VAL_ 2566719486 EngCtrlModule1ReadyForUseLampCmd 3 "Not available" 2 "Reserved" 1 "Lamp On" 0 "Lamp Off" ;
VAL_ 2566719486 EngFuelFilterRestrictedLampCmd 3 "Not available" 2 "Reserved" 1 "Lamp On" 0 "Lamp Off" ;
VAL_ 2566719486 EngAirFilterRestrictionLampCmd 3 "Not available" 2 "Reserved" 1 "Lamp On" 0 "Lamp Off" ;
VAL_ 2566719486 EngIdleManagementActiveLampCmd 3 "Not available" 2 "Reserved" 1 "Lamp On" 0 "Lamp Off" ;
VAL_ 2566719486 EngCoolantLevelLowLampCmd 3 "Not available" 2 "Reserved" 1 "Lamp On" 0 "Lamp Off" ;
VAL_ 2566719486 EngCoolantTempHighLampCmd 3 "Not available" 2 "Reserved" 1 "Lamp On" 0 "Lamp Off" ;
VAL_ 2566719486 EngOilPressLowLampCmd 3 "Not available" 2 "Reserved" 1 "Lamp On" 0 "Lamp Off" ;
VAL_ 2566719486 CmprssnBrkEnblSwtchIndctrLampCmd 3 "Not available" 2 "Reserved" 1 "Lamp ON" 0 "Lamp OFF" ;
VAL_ 2566719486 EngBrakeActiveLampCmd 3 "Not available" 2 "Reserved" 1 "Lamp On" 0 "Lamp Off" ;
VAL_ 2566719486 OBDMalfunctionIndicatorLampCmd 3 "Not available" 2 "Reserved" 1 "Lamp On" 0 "Lamp Off" ;
VAL_ 2566719486 EngRedStopLampCmd 3 "Not available" 2 "Reserved" 1 "Lamp On" 0 "Lamp Off" ;
VAL_ 2566719486 EngAmberWarningLampCmd 3 "Not available" 2 "Reserved" 1 "Lamp On" 0 "Lamp Off" ;
VAL_ 2566719486 EngProtectLampCmd 3 "Not available" 2 "Reserved" 1 "Lamp On" 0 "Lamp Off" ;
VAL_ 2163223550 CrashType 16 "rollover" 8 "side crash, right)" 4 "side crash, left)" 2 "rear crash" 1 "frontal crash" ;
VAL_ 2365400830 Joystick9Button9PressedStatus 3 "Not Available" 2 "Error Indicator" 1 "Button pressed" 0 "Button not pressed" ;
VAL_ 2365400830 Joystick9Button10PressedStatus 3 "Not Available" 2 "Error Indicator" 1 "Button pressed" 0 "Button not pressed" ;
VAL_ 2365400830 Joystick9Button11PressedStatus 3 "Not Available" 2 "Error Indicator" 1 "Button pressed" 0 "Button not pressed" ;
VAL_ 2365400830 Joystick9Button12PressedStatus 3 "Not Available" 2 "Error Indicator" 1 "Button pressed" 0 "Button not pressed" ;
VAL_ 2365400830 Joystick9Button5PressedStatus 3 "Not Available" 2 "Error Indicator" 1 "Button pressed" 0 "Button not pressed" ;
VAL_ 2365400830 Joystick9Button6PressedStatus 3 "Not Available" 2 "Error Indicator" 1 "Button pressed" 0 "Button not pressed" ;
VAL_ 2365400830 Joystick9Button7PressedStatus 3 "Not Available" 2 "Error Indicator" 1 "Button pressed" 0 "Button not pressed" ;
VAL_ 2365400830 Joystick9Button8PressedStatus 3 "Not Available" 2 "Error Indicator" 1 "Button pressed" 0 "Button not pressed" ;
VAL_ 2365400830 Joystick9Button1PressedStatus 3 "Not Available" 2 "Error Indicator" 1 "Button pressed" 0 "Button not pressed" ;
VAL_ 2365400830 Joystick9Button2PressedStatus 3 "Not Available" 2 "Error Indicator" 1 "Button pressed" 0 "Button not pressed" ;
VAL_ 2365400830 Joystick9Button3PressedStatus 3 "Not Available" 2 "Error Indicator" 1 "Button pressed" 0 "Button not pressed" ;
VAL_ 2365400830 Joystick9Button4PressedStatus 3 "Not Available" 2 "Error Indicator" 1 "Button pressed" 0 "Button not pressed" ;
VAL_ 2365400830 Joystick9XAxisDetentPosStatus 3 "Not Available" 2 "Error Indicator" 1 "In the Detent Position" 0 "Not in the Detent Position" ;
VAL_ 2365400830 Joystick9YAxisDetentPosStatus 3 "Not Available" 2 "Error Indicator" 1 "In the Detent Position" 0 "Not in the Detent Position" ;
VAL_ 2365400830 Jystck9YAxsLvrFrwrdPstvPosStatus 3 "Not Available" 2 "Error Indicator" 1 "On positive side of Neutral" 0 "Not on Positive side of Neutral" ;
VAL_ 2365400830 Jystck9YAxsLvrBckNgtivePosStatus 3 "Not Available" 2 "Error Indicator" 1 "On negative side of Neutral" 0 "Not on negative side of Neutral" ;
VAL_ 2365400830 Joystick9YAxisNeutralPosStatus 3 "Not Available" 2 "Error Indicator" 1 "In Neutral Position" 0 "Not in Neutral Position" ;
VAL_ 2365400830 Jystck9XAxsLvrRghtPstvePosStatus 3 "Not Available" 2 "Error Indicator" 1 "On positive side of Neutral" 0 "Not on Positive side of Neutral" ;
VAL_ 2365400830 Jystck9XAxsLvrLftNgtivePosStatus 3 "Not Available" 2 "Error Indicator" 1 "On negative side of Neutral" 0 "Not on negative side of Neutral" ;
VAL_ 2365400830 Joystick9XAxisNeutralPosStatus 3 "Not Available" 2 "Error Indicator" 1 "In Neutral Position" 0 "Not in Neutral Position" ;
VAL_ 2365401342 Joystick8Button9PressedStatus 3 "Not Available" 2 "Error Indicator" 1 "Button pressed" 0 "Button not pressed" ;
VAL_ 2365401342 Joystick8Button10PressedStatus 3 "Not Available" 2 "Error Indicator" 1 "Button pressed" 0 "Button not pressed" ;
VAL_ 2365401342 Joystick8Button11PressedStatus 3 "Not Available" 2 "Error Indicator" 1 "Button pressed" 0 "Button not pressed" ;
VAL_ 2365401342 Joystick8Button12PressedStatus 3 "Not Available" 2 "Error Indicator" 1 "Button pressed" 0 "Button not pressed" ;
VAL_ 2365401342 Joystick8Button5PressedStatus 3 "Not Available" 2 "Error Indicator" 1 "Button pressed" 0 "Button not pressed" ;
VAL_ 2365401342 Joystick8Button6PressedStatus 3 "Not Available" 2 "Error Indicator" 1 "Button pressed" 0 "Button not pressed" ;
VAL_ 2365401342 Joystick8Button7PressedStatus 3 "Not Available" 2 "Error Indicator" 1 "Button pressed" 0 "Button not pressed" ;
VAL_ 2365401342 Joystick8Button8PressedStatus 3 "Not Available" 2 "Error Indicator" 1 "Button pressed" 0 "Button not pressed" ;
VAL_ 2365401342 Joystick8Button1PressedStatus 3 "Not Available" 2 "Error Indicator" 1 "Button pressed" 0 "Button not pressed" ;
VAL_ 2365401342 Joystick8Button2PressedStatus 3 "Not Available" 2 "Error Indicator" 1 "Button pressed" 0 "Button not pressed" ;
VAL_ 2365401342 Joystick8Button3PressedStatus 3 "Not Available" 2 "Error Indicator" 1 "Button pressed" 0 "Button not pressed" ;
VAL_ 2365401342 Joystick8Button4PressedStatus 3 "Not Available" 2 "Error Indicator" 1 "Button pressed" 0 "Button not pressed" ;
VAL_ 2365401342 Joystick8XAxisDetentPosStatus 3 "Not Available" 2 "Error Indicator" 1 "In the Detent Position" 0 "Not in the Detent Position" ;
VAL_ 2365401342 Joystick8YAxisDetentPosStatus 3 "Not Available" 2 "Error Indicator" 1 "In the Detent Position" 0 "Not in the Detent Position" ;
VAL_ 2365401342 Jystck8YAxsLvrFrwrdPstvPosStatus 3 "Not Available" 2 "Error Indicator" 1 "On positive side of Neutral" 0 "Not on Positive side of Neutral" ;
VAL_ 2365401342 Jystck8YAxsLvrBckNgtivePosStatus 3 "Not Available" 2 "Error Indicator" 1 "On negative side of Neutral" 0 "Not on negative side of Neutral" ;
VAL_ 2365401342 Joystick8YAxisNeutralPosStatus 3 "Not Available" 2 "Error Indicator" 1 "In Neutral Position" 0 "Not in Neutral Position" ;
VAL_ 2365401342 Jystck8XAxsLvrRghtPstvePosStatus 3 "Not Available" 2 "Error Indicator" 1 "On positive side of Neutral" 0 "Not on Positive side of Neutral" ;
VAL_ 2365401342 Jystck8XAxsLvrLftNgtivePosStatus 3 "Not Available" 2 "Error Indicator" 1 "On negative side of Neutral" 0 "Not on negative side of Neutral" ;
VAL_ 2365401342 Joystick8XAxisNeutralPosStatus 3 "Not Available" 2 "Error Indicator" 1 "In Neutral Position" 0 "Not in Neutral Position" ;
VAL_ 2365401854 Joystick7Button9PressedStatus 3 "Not Available" 2 "Error Indicator" 1 "Button pressed" 0 "Button not pressed" ;
VAL_ 2365401854 Joystick7Button10PressedStatus 3 "Not Available" 2 "Error Indicator" 1 "Button pressed" 0 "Button not pressed" ;
VAL_ 2365401854 Joystick7Button11PressedStatus 3 "Not Available" 2 "Error Indicator" 1 "Button pressed" 0 "Button not pressed" ;
VAL_ 2365401854 Joystick7Button12PressedStatus 3 "Not Available" 2 "Error Indicator" 1 "Button pressed" 0 "Button not pressed" ;
VAL_ 2365401854 Joystick7Button5PressedStatus 3 "Not Available" 2 "Error Indicator" 1 "Button pressed" 0 "Button not pressed" ;
VAL_ 2365401854 Joystick7Button6PressedStatus 3 "Not Available" 2 "Error Indicator" 1 "Button pressed" 0 "Button not pressed" ;
VAL_ 2365401854 Joystick7Button7PressedStatus 3 "Not Available" 2 "Error Indicator" 1 "Button pressed" 0 "Button not pressed" ;
VAL_ 2365401854 Joystick7Button8PressedStatus 3 "Not Available" 2 "Error Indicator" 1 "Button pressed" 0 "Button not pressed" ;
VAL_ 2365401854 Joystick7Button1PressedStatus 3 "Not Available" 2 "Error Indicator" 1 "Button pressed" 0 "Button not pressed" ;
VAL_ 2365401854 Joystick7Button2PressedStatus 3 "Not Available" 2 "Error Indicator" 1 "Button pressed" 0 "Button not pressed" ;
VAL_ 2365401854 Joystick7Button3PressedStatus 3 "Not Available" 2 "Error Indicator" 1 "Button pressed" 0 "Button not pressed" ;
VAL_ 2365401854 Joystick7Button4PressedStatus 3 "Not Available" 2 "Error Indicator" 1 "Button pressed" 0 "Button not pressed" ;
VAL_ 2365401854 Joystick7XAxisDetentPosStatus 3 "Not Available" 2 "Error Indicator" 1 "In the Detent Position" 0 "Not in the Detent Position" ;
VAL_ 2365401854 Joystick7YAxisDetentPosStatus 3 "Not Available" 2 "Error Indicator" 1 "In the Detent Position" 0 "Not in the Detent Position" ;
VAL_ 2365401854 Jystck7YAxsLvrFrwrdPstvPosStatus 3 "Not Available" 2 "Error Indicator" 1 "On positive side of Neutral" 0 "Not on Positive side of Neutral" ;
VAL_ 2365401854 Jystck7YAxsLvrBckNgtivePosStatus 3 "Not Available" 2 "Error Indicator" 1 "On negative side of Neutral" 0 "Not on negative side of Neutral" ;
VAL_ 2365401854 Joystick7YAxisNeutralPosStatus 3 "Not Available" 2 "Error Indicator" 1 "In Neutral Position" 0 "Not in Neutral Position" ;
VAL_ 2365401854 Jystck7XAxsLvrRghtPstvePosStatus 3 "Not Available" 2 "Error Indicator" 1 "On positive side of Neutral" 0 "Not on Positive side of Neutral" ;
VAL_ 2365401854 Jystck7XAxsLvrLftNgtivePosStatus 3 "Not Available" 2 "Error Indicator" 1 "On negative side of Neutral" 0 "Not on negative side of Neutral" ;
VAL_ 2365401854 Joystick7XAxisNeutralPosStatus 3 "Not Available" 2 "Error Indicator" 1 "In Neutral Position" 0 "Not in Neutral Position" ;
VAL_ 2365402366 Joystick6Button9PressedStatus 3 "Not Available" 2 "Error Indicator" 1 "Button pressed" 0 "Button not pressed" ;
VAL_ 2365402366 Joystick6Button10PressedStatus 3 "Not Available" 2 "Error Indicator" 1 "Button pressed" 0 "Button not pressed" ;
VAL_ 2365402366 Joystick6Button11PressedStatus 3 "Not Available" 2 "Error Indicator" 1 "Button pressed" 0 "Button not pressed" ;
VAL_ 2365402366 Joystick6Button12PressedStatus 3 "Not Available" 2 "Error Indicator" 1 "Button pressed" 0 "Button not pressed" ;
VAL_ 2365402366 Joystick6Button5PressedStatus 3 "Not Available" 2 "Error Indicator" 1 "Button pressed" 0 "Button not pressed" ;
VAL_ 2365402366 Joystick6Button6PressedStatus 3 "Not Available" 2 "Error Indicator" 1 "Button pressed" 0 "Button not pressed" ;
VAL_ 2365402366 Joystick6Button7PressedStatus 3 "Not Available" 2 "Error Indicator" 1 "Button pressed" 0 "Button not pressed" ;
VAL_ 2365402366 Joystick6Button8PressedStatus 3 "Not Available" 2 "Error Indicator" 1 "Button pressed" 0 "Button not pressed" ;
VAL_ 2365402366 Joystick6Button1PressedStatus 3 "Not Available" 2 "Error Indicator" 1 "Button pressed" 0 "Button not pressed" ;
VAL_ 2365402366 Joystick6Button2PressedStatus 3 "Not Available" 2 "Error Indicator" 1 "Button pressed" 0 "Button not pressed" ;
VAL_ 2365402366 Joystick6Button3PressedStatus 3 "Not Available" 2 "Error Indicator" 1 "Button pressed" 0 "Button not pressed" ;
VAL_ 2365402366 Joystick6Button4PressedStatus 3 "Not Available" 2 "Error Indicator" 1 "Button pressed" 0 "Button not pressed" ;
VAL_ 2365402366 Joystick6XAxisDetentPosStatus 3 "Not Available" 2 "Error Indicator" 1 "In the Detent Position" 0 "Not in the Detent Position" ;
VAL_ 2365402366 Joystick6YAxisDetentPosStatus 3 "Not Available" 2 "Error Indicator" 1 "In the Detent Position" 0 "Not in the Detent Position" ;
VAL_ 2365402366 Jystck6YAxsLvrFrwrdPstvPosStatus 3 "Not Available" 2 "Error Indicator" 1 "On positive side of Neutral" 0 "Not on Positive side of Neutral" ;
VAL_ 2365402366 Jystck6YAxsLvrBckNgtivePosStatus 3 "Not Available" 2 "Error Indicator" 1 "On negative side of Neutral" 0 "Not on negative side of Neutral" ;
VAL_ 2365402366 Joystick6YAxisNeutralPosStatus 3 "Not Available" 2 "Error Indicator" 1 "In Neutral Position" 0 "Not in Neutral Position" ;
VAL_ 2365402366 Jystck6XAxsLvrRghtPstvePosStatus 3 "Not Available" 2 "Error Indicator" 1 "On positive side of Neutral" 0 "Not on Positive side of Neutral" ;
VAL_ 2365402366 Jystck6XAxsLvrLftNgtivePosStatus 3 "Not Available" 2 "Error Indicator" 1 "On negative side of Neutral" 0 "Not on negative side of Neutral" ;
VAL_ 2365402366 Joystick6XAxisNeutralPosStatus 3 "Not Available" 2 "Error Indicator" 1 "In Neutral Position" 0 "Not in Neutral Position" ;
VAL_ 2365402878 Joystick5Button9PressedStatus 3 "Not Available" 2 "Error Indicator" 1 "Button pressed" 0 "Button not pressed" ;
VAL_ 2365402878 Joystick5Button10PressedStatus 3 "Not Available" 2 "Error Indicator" 1 "Button pressed" 0 "Button not pressed" ;
VAL_ 2365402878 Joystick5Button11PressedStatus 3 "Not Available" 2 "Error Indicator" 1 "Button pressed" 0 "Button not pressed" ;
VAL_ 2365402878 Joystick5Button12PressedStatus 3 "Not Available" 2 "Error Indicator" 1 "Button pressed" 0 "Button not pressed" ;
VAL_ 2365402878 Joystick5Button5PressedStatus 3 "Not Available" 2 "Error Indicator" 1 "Button pressed" 0 "Button not pressed" ;
VAL_ 2365402878 Joystick5Button6PressedStatus 3 "Not Available" 2 "Error Indicator" 1 "Button pressed" 0 "Button not pressed" ;
VAL_ 2365402878 Joystick5Button7PressedStatus 3 "Not Available" 2 "Error Indicator" 1 "Button pressed" 0 "Button not pressed" ;
VAL_ 2365402878 Joystick5Button8PressedStatus 3 "Not Available" 2 "Error Indicator" 1 "Button pressed" 0 "Button not pressed" ;
VAL_ 2365402878 Joystick5Button1PressedStatus 3 "Not Available" 2 "Error Indicator" 1 "Button pressed" 0 "Button not pressed" ;
VAL_ 2365402878 Joystick5Button2PressedStatus 3 "Not Available" 2 "Error Indicator" 1 "Button pressed" 0 "Button not pressed" ;
VAL_ 2365402878 Joystick5Button3PressedStatus 3 "Not Available" 2 "Error Indicator" 1 "Button pressed" 0 "Button not pressed" ;
VAL_ 2365402878 Joystick5Button4PressedStatus 3 "Not Available" 2 "Error Indicator" 1 "Button pressed" 0 "Button not pressed" ;
VAL_ 2365402878 Joystick5XAxisDetentPosStatus 3 "Not Available" 2 "Error Indicator" 1 "In the Detent Position" 0 "Not in the Detent Position" ;
VAL_ 2365402878 Joystick5YAxisDetentPosStatus 3 "Not Available" 2 "Error Indicator" 1 "In the Detent Position" 0 "Not in the Detent Position" ;
VAL_ 2365402878 Jystck5YAxsLvrFrwrdPstvPosStatus 3 "Not Available" 2 "Error Indicator" 1 "On positive side of Neutral" 0 "Not on Positive side of Neutral" ;
VAL_ 2365402878 Jystck5YAxsLvrBckNgtivePosStatus 3 "Not Available" 2 "Error Indicator" 1 "On negative side of Neutral" 0 "Not on negative side of Neutral" ;
VAL_ 2365402878 Joystick5YAxisNeutralPosStatus 3 "Not Available" 2 "Error Indicator" 1 "In Neutral Position" 0 "Not in Neutral Position" ;
VAL_ 2365402878 Jystck5XAxsLvrRghtPstvePosStatus 3 "Not Available" 2 "Error Indicator" 1 "On positive side of Neutral" 0 "Not on Positive side of Neutral" ;
VAL_ 2365402878 Jystck5XAxsLvrLftNgtivePosStatus 3 "Not Available" 2 "Error Indicator" 1 "On negative side of Neutral" 0 "Not on negative side of Neutral" ;
VAL_ 2365402878 Joystick5XAxisNeutralPosStatus 3 "Not Available" 2 "Error Indicator" 1 "In Neutral Position" 0 "Not in Neutral Position" ;
VAL_ 2365403390 Joystick4Button9PressedStatus 3 "Not Available" 2 "Error Indicator" 1 "Button pressed" 0 "Button not pressed" ;
VAL_ 2365403390 Joystick4Button10PressedStatus 1 "Button pressed" 0 "Button not pressed" 3 "Not Available" 2 "Error Indicator" ;
VAL_ 2365403390 Joystick4Button11PressedStatus 3 "Not Available" 2 "Error Indicator" 1 "Button pressed" 0 "Button not pressed" ;
VAL_ 2365403390 Joystick4Button12PressedStatus 3 "Not Available" 2 "Error Indicator" 1 "Button pressed" 0 "Button not pressed" ;
VAL_ 2365403390 Joystick4Button5PressedStatus 3 "Not Available" 2 "Error Indicator" 1 "Button pressed" 0 "Button not pressed" ;
VAL_ 2365403390 Joystick4Button6PressedStatus 3 "Not Available" 2 "Error Indicator" 1 "Button pressed" 0 "Button not pressed" ;
VAL_ 2365403390 Joystick4Button7PressedStatus 3 "Not Available" 2 "Error Indicator" 1 "Button pressed" 0 "Button not pressed" ;
VAL_ 2365403390 Joystick4Button8PressedStatus 3 "Not Available" 2 "Error Indicator" 1 "Button pressed" 0 "Button not pressed" ;
VAL_ 2365403390 Joystick4Button1PressedStatus 3 "Not Available" 2 "Error Indicator" 1 "Button pressed" 0 "Button not pressed" ;
VAL_ 2365403390 Joystick4Button2PressedStatus 3 "Not Available" 2 "Error Indicator" 1 "Button pressed" 0 "Button not pressed" ;
VAL_ 2365403390 Joystick4Button3PressedStatus 3 "Not Available" 2 "Error Indicator" 1 "Button pressed" 0 "Button not pressed" ;
VAL_ 2365403390 Joystick4Button4PressedStatus 3 "Not Available" 2 "Error Indicator" 1 "Button pressed" 0 "Button not pressed" ;
VAL_ 2365403390 Joystick4XAxisDetentPosStatus 3 "Not Available" 2 "Error Indicator" 1 "In the Detent Position" 0 "Not in the Detent Position" ;
VAL_ 2365403390 Joystick4YAxisDetentPosStatus 3 "Not Available" 2 "Error Indicator" 1 "In the Detent Position" 0 "Not in the Detent Position" ;
VAL_ 2365403390 Jystck4YAxsLvrFrwrdPstvPosStatus 3 "Not Available" 2 "Error Indicator" 1 "On positive side of Neutral" 0 "Not on Positive side of Neutral" ;
VAL_ 2365403390 Jystck4YAxsLvrBckNgtivePosStatus 3 "Not Available" 2 "Error Indicator" 1 "On negative side of Neutral" 0 "Not on negative side of Neutral" ;
VAL_ 2365403390 Joystick4YAxisNeutralPosStatus 3 "Not Available" 2 "Error Indicator" 1 "In Neutral Position" 0 "Not in Neutral Position" ;
VAL_ 2365403390 Jystck4XAxsLvrRghtPstvePosStatus 3 "Not Available" 2 "Error Indicator" 1 "On positive side of Neutral" 0 "Not on Positive side of Neutral" ;
VAL_ 2365403390 Jystck4XAxsLvrLftNgtivePosStatus 3 "Not Available" 2 "Error Indicator" 1 "On negative side of Neutral" 0 "Not on negative side of Neutral" ;
VAL_ 2365403390 Joystick4XAxisNeutralPosStatus 3 "Not Available" 2 "Error Indicator" 1 "In Neutral Position" 0 "Not in Neutral Position" ;
